VERSION ""

NS_ :

BS_:

BU_: WPC2 RLPSU DPSU APSU PSB SHVU_RR vHS_B2 FCS EMCU SLB ARS RCM CGW_CCU vDummy_HS_B ATS RLHV SGU PFSU ALBCU DSAU SWRC SHVU_FR RCS RRPSU BLTN_CAM SCM DLBCU OHCL RWPC RRHV WPC HOD ASAU

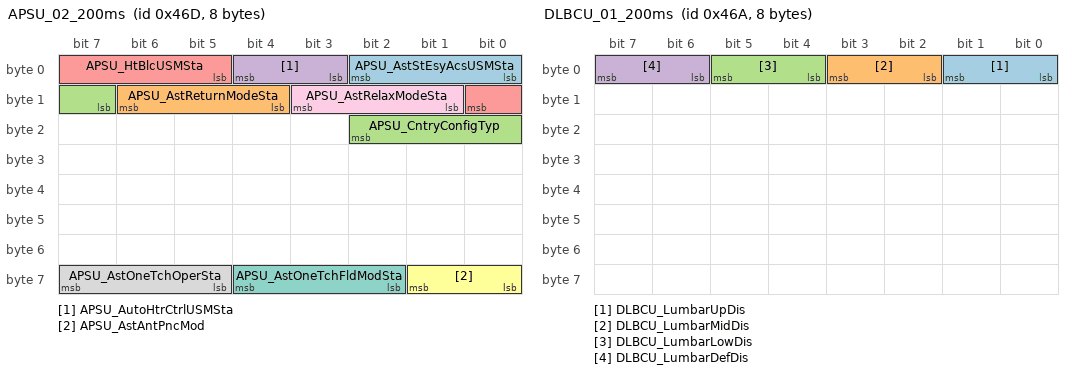
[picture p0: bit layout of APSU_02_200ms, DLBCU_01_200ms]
BO_ 1133 APSU_02_200ms: 8 APSU
 SG_ APSU_AstStEsyAcsUSMSta : 0|3@1+ (1,0) [0|0] ""  ALBCU,CGW_CCU
 SG_ APSU_AstReturnModeSta : 12|3@1+ (1,0) [0|0] ""  CGW_CCU
 SG_ APSU_CntryConfigTyp : 15|4@1+ (1,0) [0|0] ""  Vector__XXX
 SG_ APSU_AutoHtrCtrlUSMSta : 3|2@1+ (1,0) [0|0] ""  Vector__XXX
 SG_ APSU_HtBlcUSMSta : 5|4@1+ (1,0) [0|0] ""  Vector__XXX
 SG_ APSU_AstAntPncMod : 56|2@1+ (1,0) [0|0] ""  RLPSU,RRPSU
 SG_ APSU_AstOneTchFldModSta : 58|3@1+ (1,0) [0|0] ""  RLPSU,RRPSU
 SG_ APSU_AstOneTchOperSta : 61|3@1+ (1,0) [0|0] ""  RLPSU,RRPSU
 SG_ APSU_AstRelaxModeSta : 9|3@1+ (1,0) [0|0] ""  CGW_CCU

BO_ 1130 DLBCU_01_200ms: 8 DLBCU
 SG_ DLBCU_LumbarUpDis : 0|2@1+ (1,0) [0|0] ""  CGW_CCU
 SG_ DLBCU_LumbarMidDis : 2|2@1+ (1,0) [0|0] ""  CGW_CCU
 SG_ DLBCU_LumbarLowDis : 4|2@1+ (1,0) [0|0] ""  CGW_CCU
 SG_ DLBCU_LumbarDefDis : 6|2@1+ (1,0) [0|0] ""  CGW_CCU

BO_ 1131 DLBCU_02_200ms: 8 DLBCU
 SG_ DLBCU_BolsterInfDis : 0|2@1+ (1,0) [0|0] ""  CGW_CCU
 SG_ DLBCU_BolsterDefDis : 2|2@1+ (1,0) [0|0] ""  CGW_CCU

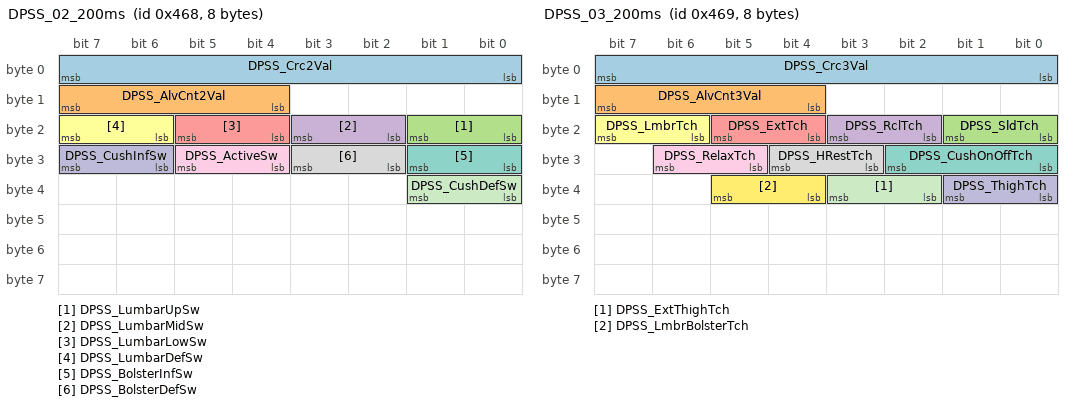
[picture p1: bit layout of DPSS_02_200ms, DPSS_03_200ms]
BO_ 1128 DPSS_02_200ms: 8 DPSU
 SG_ DPSS_Crc2Val : 0|8@1+ (1,0) [0|0] ""  DLBCU
 SG_ DPSS_AlvCnt2Val : 12|4@1+ (1,0) [0|0] ""  DLBCU
 SG_ DPSS_LumbarUpSw : 16|2@1+ (1,0) [0|0] ""  DLBCU
 SG_ DPSS_LumbarMidSw : 18|2@1+ (1,0) [0|0] ""  DLBCU
 SG_ DPSS_LumbarLowSw : 20|2@1+ (1,0) [0|0] ""  DLBCU
 SG_ DPSS_LumbarDefSw : 22|2@1+ (1,0) [0|0] ""  DLBCU
 SG_ DPSS_BolsterInfSw : 24|2@1+ (1,0) [0|0] ""  DLBCU
 SG_ DPSS_BolsterDefSw : 26|2@1+ (1,0) [0|0] ""  DLBCU
 SG_ DPSS_ActiveSw : 28|2@1+ (1,0) [0|0] ""  DLBCU
 SG_ DPSS_CushInfSw : 30|2@1+ (1,0) [0|0] ""  DLBCU
 SG_ DPSS_CushDefSw : 32|2@1+ (1,0) [0|0] ""  DLBCU

BO_ 1129 DPSS_03_200ms: 8 DPSU
 SG_ DPSS_Crc3Val : 0|8@1+ (1,0) [0|0] ""  CGW_CCU
 SG_ DPSS_AlvCnt3Val : 12|4@1+ (1,0) [0|0] ""  Vector__XXX
 SG_ DPSS_SldTch : 16|2@1+ (1,0) [0|0] ""  CGW_CCU
 SG_ DPSS_RclTch : 18|2@1+ (1,0) [0|0] ""  CGW_CCU
 SG_ DPSS_ExtTch : 20|2@1+ (1,0) [0|0] ""  CGW_CCU
 SG_ DPSS_LmbrTch : 22|2@1+ (1,0) [0|0] ""  CGW_CCU
 SG_ DPSS_CushOnOffTch : 24|3@1+ (1,0) [0|0] ""  CGW_CCU
 SG_ DPSS_HRestTch : 27|2@1+ (1,0) [0|0] ""  CGW_CCU
 SG_ DPSS_RelaxTch : 29|2@1+ (1,0) [0|0] ""  CGW_CCU
 SG_ DPSS_ThighTch : 32|2@1+ (1,0) [0|0] ""  CGW_CCU
 SG_ DPSS_ExtThighTch : 34|2@1+ (1,0) [0|0] ""  CGW_CCU
 SG_ DPSS_LmbrBolsterTch : 36|2@1+ (1,0) [0|0] ""  CGW_CCU

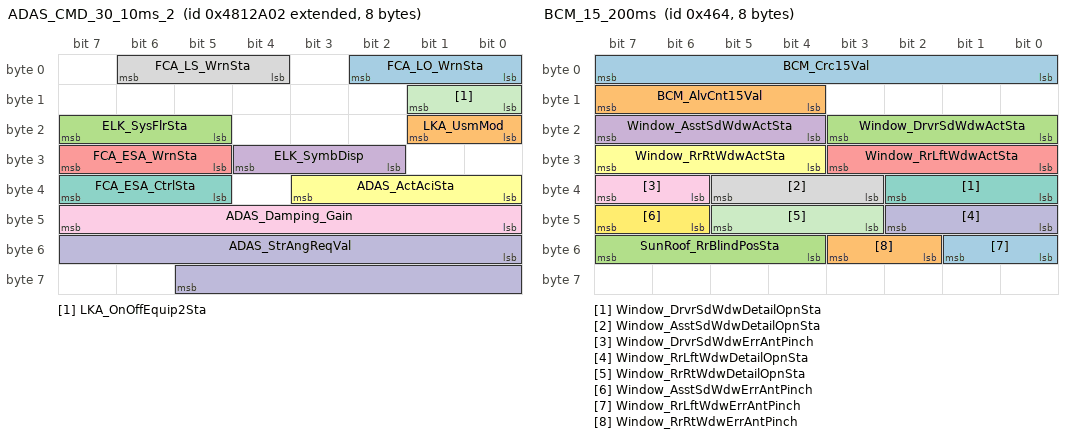
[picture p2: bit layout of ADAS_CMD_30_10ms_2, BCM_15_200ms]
BO_ 2223057410 ADAS_CMD_30_10ms_2: 8 CGW_CCU
 SG_ FCA_LO_WrnSta : 0|3@1+ (1,0) [0|0] ""  SWRC
 SG_ LKA_UsmMod : 16|2@1+ (1,0) [0|0] ""  Vector__XXX
 SG_ ELK_SysFlrSta : 21|3@1+ (1,0) [0|0] ""  Vector__XXX
 SG_ ELK_SymbDisp : 26|3@1+ (1,0) [0|0] ""  Vector__XXX
 SG_ FCA_ESA_WrnSta : 29|3@1+ (1,0) [0|0] ""  SWRC
 SG_ ADAS_ActAciSta : 32|4@1+ (1,0) [0|0] ""  Vector__XXX
 SG_ FCA_ESA_CtrlSta : 37|3@1+ (1,0) [0|0] ""  Vector__XXX
 SG_ FCA_LS_WrnSta : 4|3@1+ (1,0) [0|0] ""  SWRC
 SG_ ADAS_Damping_Gain : 40|8@1+ (1,0) [0|0] ""  Vector__XXX
 SG_ ADAS_StrAngReqVal : 48|14@1- (0.1,0) [0|0] "Deg"  Vector__XXX
 SG_ LKA_OnOffEquip2Sta : 8|2@1+ (1,0) [0|0] ""  Vector__XXX

BO_ 1127 DPSS_01_200ms: 8 DPSU
 SG_ DPSS_Crc1Val : 0|8@1+ (1,0) [0|0] ""  Vector__XXX
 SG_ DPSS_AlvCnt1Val : 12|4@1+ (1,0) [0|0] ""  Vector__XXX
 SG_ DPSS_StExtFwdMvBtn : 16|2@1+ (1,0) [0|0] ""  Vector__XXX
 SG_ DPSS_StExtBwdMvBtn : 18|2@1+ (1,0) [0|0] ""  Vector__XXX
 SG_ DPSS_StSldFwdMvBtn : 20|2@1+ (1,0) [0|0] ""  Vector__XXX
 SG_ DPSS_StSldBwdMvBtn : 24|2@1+ (1,0) [0|0] ""  Vector__XXX
 SG_ DPSS_StRclFwdMvBtn : 26|2@1+ (1,0) [0|0] ""  Vector__XXX
 SG_ DPSS_StRclBwdMvBtn : 28|2@1+ (1,0) [0|0] ""  Vector__XXX
 SG_ DPSS_StHgtUpMvBtn : 30|2@1+ (1,0) [0|0] ""  Vector__XXX
 SG_ DPSS_StHgtDnMvBtn : 32|2@1+ (1,0) [0|0] ""  Vector__XXX
 SG_ DPSS_StTltUpMvBtn : 34|2@1+ (1,0) [0|0] ""  Vector__XXX
 SG_ DPSS_StTltDnMvBtn : 36|2@1+ (1,0) [0|0] ""  Vector__XXX
 SG_ DPSS_StHRestUpMvBtn : 38|2@1+ (1,0) [0|0] ""  Vector__XXX
 SG_ DPSS_StHRestDnMvBtn : 40|2@1+ (1,0) [0|0] ""  Vector__XXX
 SG_ DPSS_StHRestFwdMvBtn : 42|2@1+ (1,0) [0|0] ""  Vector__XXX
 SG_ DPSS_StHRestBwdMvBtn : 44|2@1+ (1,0) [0|0] ""  Vector__XXX
 SG_ DPSS_StLegUpMvBtn : 46|2@1+ (1,0) [0|0] ""  Vector__XXX
 SG_ DPSS_StLegDnMvBtn : 48|2@1+ (1,0) [0|0] ""  Vector__XXX
 SG_ DPSS_StRlxModeBtn : 50|2@1+ (1,0) [0|0] ""  Vector__XXX
 SG_ DPSS_StRlxReturnBtn : 52|2@1+ (1,0) [0|0] ""  Vector__XXX
 SG_ DPSS_StRlxTltUpMvBtn : 54|2@1+ (1,0) [0|0] ""  Vector__XXX
 SG_ DPSS_StRlxTltDnMvBtn : 56|2@1+ (1,0) [0|0] ""  Vector__XXX

BO_ 1124 BCM_15_200ms: 8 CGW_CCU
 SG_ BCM_Crc15Val : 0|8@1+ (1,0) [0|0] ""  Vector__XXX
 SG_ BCM_AlvCnt15Val : 12|4@1+ (1,0) [0|0] ""  Vector__XXX
 SG_ Window_DrvrSdWdwActSta : 16|4@1+ (1,0) [0|0] ""  Vector__XXX
 SG_ Window_AsstSdWdwActSta : 20|4@1+ (1,0) [0|0] ""  Vector__XXX
 SG_ Window_RrLftWdwActSta : 24|4@1+ (1,0) [0|0] ""  Vector__XXX
 SG_ Window_RrRtWdwActSta : 28|4@1+ (1,0) [0|0] ""  Vector__XXX
 SG_ Window_DrvrSdWdwDetailOpnSta : 32|3@1+ (1,0) [0|0] ""  Vector__XXX
 SG_ Window_AsstSdWdwDetailOpnSta : 35|3@1+ (1,0) [0|0] ""  Vector__XXX
 SG_ Window_DrvrSdWdwErrAntPinch : 38|2@1+ (1,0) [0|0] ""  Vector__XXX
 SG_ Window_RrLftWdwDetailOpnSta : 40|3@1+ (1,0) [0|0] ""  Vector__XXX
 SG_ Window_RrRtWdwDetailOpnSta : 43|3@1+ (1,0) [0|0] ""  Vector__XXX
 SG_ Window_AsstSdWdwErrAntPinch : 46|2@1+ (1,0) [0|0] ""  Vector__XXX
 SG_ Window_RrLftWdwErrAntPinch : 48|2@1+ (1,0) [0|0] ""  Vector__XXX
 SG_ Window_RrRtWdwErrAntPinch : 50|2@1+ (1,0) [0|0] ""  Vector__XXX
 SG_ SunRoof_RrBlindPosSta : 52|4@1+ (1,0) [0|0] ""  ATS

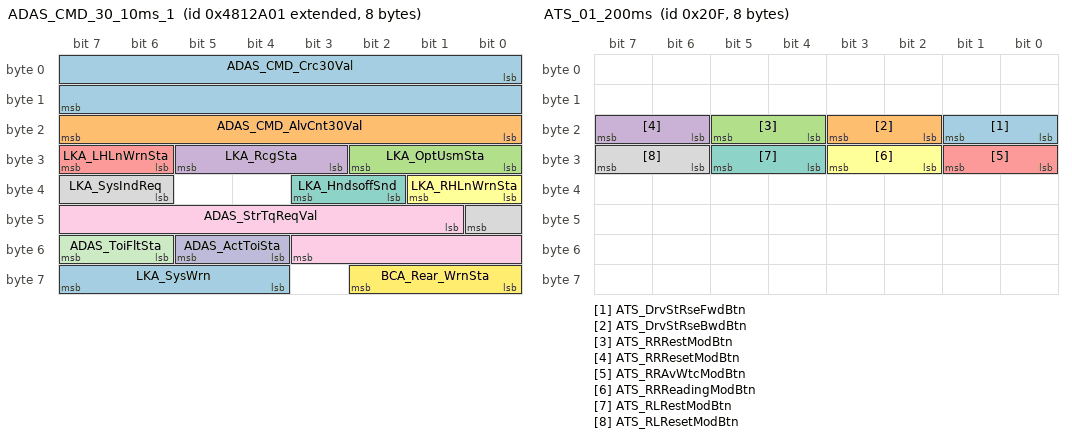
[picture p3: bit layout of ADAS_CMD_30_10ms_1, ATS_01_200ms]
BO_ 2223057409 ADAS_CMD_30_10ms_1: 8 CGW_CCU
 SG_ ADAS_CMD_Crc30Val : 0|16@1+ (1,0) [0|0] ""  Vector__XXX
 SG_ ADAS_CMD_AlvCnt30Val : 16|8@1+ (1,0) [0|0] ""  Vector__XXX
 SG_ LKA_OptUsmSta : 24|3@1+ (1,0) [0|0] ""  Vector__XXX
 SG_ LKA_RcgSta : 27|3@1+ (1,0) [0|0] ""  Vector__XXX
 SG_ LKA_LHLnWrnSta : 30|2@1+ (1,0) [0|0] ""  Vector__XXX
 SG_ LKA_RHLnWrnSta : 32|2@1+ (1,0) [0|0] ""  Vector__XXX
 SG_ LKA_HndsoffSnd : 34|2@1+ (1,0) [0|0] ""  Vector__XXX
 SG_ LKA_SysIndReq : 38|3@1+ (1,0) [0|0] ""  Vector__XXX
 SG_ ADAS_StrTqReqVal : 41|11@1+ (0.0078125,-8) [0|0] "Nm"  Vector__XXX
 SG_ ADAS_ActToiSta : 52|2@1+ (1,0) [0|0] ""  Vector__XXX
 SG_ ADAS_ToiFltSta : 54|2@1+ (1,0) [0|0] ""  Vector__XXX
 SG_ BCA_Rear_WrnSta : 56|3@1+ (1,0) [0|0] ""  Vector__XXX
 SG_ LKA_SysWrn : 60|4@1+ (1,0) [0|0] ""  Vector__XXX

BO_ 527 ATS_01_200ms: 8 ATS
 SG_ ATS_DrvStRseFwdBtn : 16|2@1+ (1,0) [0|0] ""  Vector__XXX
 SG_ ATS_DrvStRseBwdBtn : 18|2@1+ (1,0) [0|0] ""  Vector__XXX
 SG_ ATS_RRRestModBtn : 20|2@1+ (1,0) [0|0] ""  Vector__XXX
 SG_ ATS_RRResetModBtn : 22|2@1+ (1,0) [0|0] ""  Vector__XXX
 SG_ ATS_RRAvWtcModBtn : 24|2@1+ (1,0) [0|0] ""  Vector__XXX
 SG_ ATS_RRReadingModBtn : 26|2@1+ (1,0) [0|0] ""  Vector__XXX
 SG_ ATS_RLRestModBtn : 28|2@1+ (1,0) [0|0] ""  Vector__XXX
 SG_ ATS_RLResetModBtn : 30|2@1+ (1,0) [0|0] ""  Vector__XXX

BO_ 1616 MKBD_HU_E_01: 8 CGW_CCU
 SG_ MKBD_IllumiState : 48|2@1+ (1,0) [0|0] ""  Vector__XXX
 SG_ MKBD_SeatKeySet : 50|2@1+ (1,0) [0|0] ""  APSU,SHVU_FR,DPSU

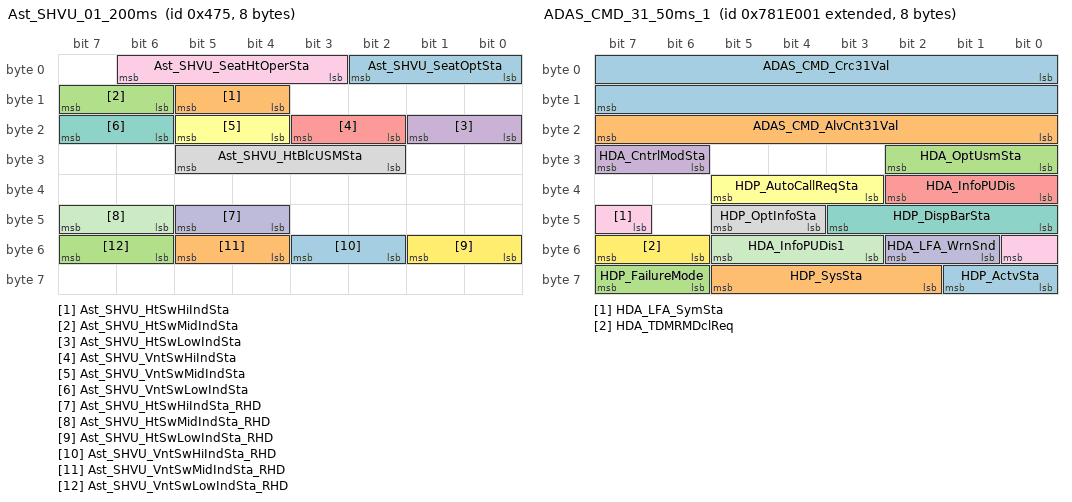
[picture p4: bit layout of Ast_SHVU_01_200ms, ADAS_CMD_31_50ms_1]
BO_ 1141 Ast_SHVU_01_200ms: 8 APSU
 SG_ Ast_SHVU_SeatOptSta : 0|3@1+ (1,0) [0|0] ""  FCS,CGW_CCU
 SG_ Ast_SHVU_HtSwHiIndSta : 12|2@1+ (1,0) [0|0] ""  FCS,CGW_CCU
 SG_ Ast_SHVU_HtSwMidIndSta : 14|2@1+ (1,0) [0|0] ""  FCS,CGW_CCU
 SG_ Ast_SHVU_HtSwLowIndSta : 16|2@1+ (1,0) [0|0] ""  FCS,CGW_CCU
 SG_ Ast_SHVU_VntSwHiIndSta : 18|2@1+ (1,0) [0|0] ""  FCS,CGW_CCU
 SG_ Ast_SHVU_VntSwMidIndSta : 20|2@1+ (1,0) [0|0] ""  FCS,CGW_CCU
 SG_ Ast_SHVU_VntSwLowIndSta : 22|2@1+ (1,0) [0|0] ""  FCS,CGW_CCU
 SG_ Ast_SHVU_HtBlcUSMSta : 26|4@1+ (1,0) [0|0] ""  CGW_CCU
 SG_ Ast_SHVU_SeatHtOperSta : 3|4@1+ (1,0) [0|0] ""  CGW_CCU
 SG_ Ast_SHVU_HtSwHiIndSta_RHD : 44|2@1+ (1,0) [0|0] ""  FCS,CGW_CCU
 SG_ Ast_SHVU_HtSwMidIndSta_RHD : 46|2@1+ (1,0) [0|0] ""  FCS,CGW_CCU
 SG_ Ast_SHVU_HtSwLowIndSta_RHD : 48|2@1+ (1,0) [0|0] ""  FCS,CGW_CCU
 SG_ Ast_SHVU_VntSwHiIndSta_RHD : 50|2@1+ (1,0) [0|0] ""  FCS,CGW_CCU
 SG_ Ast_SHVU_VntSwMidIndSta_RHD : 52|2@1+ (1,0) [0|0] ""  FCS,CGW_CCU
 SG_ Ast_SHVU_VntSwLowIndSta_RHD : 54|2@1+ (1,0) [0|0] ""  FCS,CGW_CCU

BO_ 543 ATS_02_200ms: 8 ATS
 SG_ ATS_AstStSldFwdBtn : 16|2@1+ (1,0) [0|0] ""  Vector__XXX
 SG_ ATS_AstStSldBwdBtn : 18|2@1+ (1,0) [0|0] ""  Vector__XXX
 SG_ ATS_AstStRclFwdBtn : 20|2@1+ (1,0) [0|0] ""  Vector__XXX
 SG_ ATS_AstStRclBwdBtn : 22|2@1+ (1,0) [0|0] ""  Vector__XXX
 SG_ ATS_AstStHgtUpBtn : 28|2@1+ (1,0) [0|0] ""  Vector__XXX
 SG_ ATS_AstStHgtDnBtn : 30|2@1+ (1,0) [0|0] ""  Vector__XXX
 SG_ ATS_AstStHRestUpBtn : 40|2@1+ (1,0) [0|0] ""  Vector__XXX
 SG_ ATS_AstStHRestDnBtn : 42|2@1+ (1,0) [0|0] ""  Vector__XXX
 SG_ ATS_AstStHRestFwdBtn : 44|2@1+ (1,0) [0|0] ""  Vector__XXX
 SG_ ATS_AstStHRestBwdBtn : 46|2@1+ (1,0) [0|0] ""  Vector__XXX
 SG_ ATS_AstStHRestFldBtn : 48|2@1+ (1,0) [0|0] ""  Vector__XXX
 SG_ ATS_AstStHRestUnFldBtn : 50|2@1+ (1,0) [0|0] ""  Vector__XXX
 SG_ ATS_AstStRseFwdBtn : 52|2@1+ (1,0) [0|0] ""  Vector__XXX
 SG_ ATS_AstStRseBwdBtn : 54|2@1+ (1,0) [0|0] ""  Vector__XXX
 SG_ ATS_AstStFRestFldBtn : 56|2@1+ (1,0) [0|0] ""  Vector__XXX
 SG_ ATS_AstStFRestUnFldBtn : 58|2@1+ (1,0) [0|0] ""  Vector__XXX
 SG_ ATS_AstTltUpBtn : 60|2@1+ (1,0) [0|0] ""  Vector__XXX
 SG_ ATS_AstTltDnBtn : 62|2@1+ (1,0) [0|0] ""  Vector__XXX

BO_ 2273435649 ADAS_CMD_31_50ms_1: 8 CGW_CCU
 SG_ ADAS_CMD_Crc31Val : 0|16@1+ (1,0) [0|0] ""  Vector__XXX
 SG_ ADAS_CMD_AlvCnt31Val : 16|8@1+ (1,0) [0|0] ""  Vector__XXX
 SG_ HDA_OptUsmSta : 24|3@1+ (1,0) [0|0] ""  Vector__XXX
 SG_ HDA_CntrlModSta : 30|2@1+ (1,0) [0|0] ""  Vector__XXX
 SG_ HDA_InfoPUDis : 32|3@1+ (1,0) [0|0] ""  Vector__XXX
 SG_ HDP_AutoCallReqSta : 35|3@1+ (1,0) [0|0] ""  Vector__XXX
 SG_ HDP_DispBarSta : 40|4@1+ (1,0) [0|0] ""  Vector__XXX
 SG_ HDP_OptInfoSta : 44|2@1+ (1,0) [0|0] ""  Vector__XXX
 SG_ HDA_LFA_SymSta : 47|2@1+ (1,0) [0|0] ""  Vector__XXX
 SG_ HDA_LFA_WrnSnd : 49|2@1+ (1,0) [0|0] ""  Vector__XXX
 SG_ HDA_InfoPUDis1 : 51|3@1+ (1,0) [0|0] ""  Vector__XXX
 SG_ HDA_TDMRMDclReq : 54|2@1+ (1,0) [0|0] ""  Vector__XXX
 SG_ HDP_ActvSta : 56|2@1+ (1,0) [0|0] ""  Vector__XXX
 SG_ HDP_SysSta : 58|4@1+ (1,0) [0|0] ""  HOD
 SG_ HDP_FailureMode : 62|2@1+ (1,0) [0|0] ""  Vector__XXX

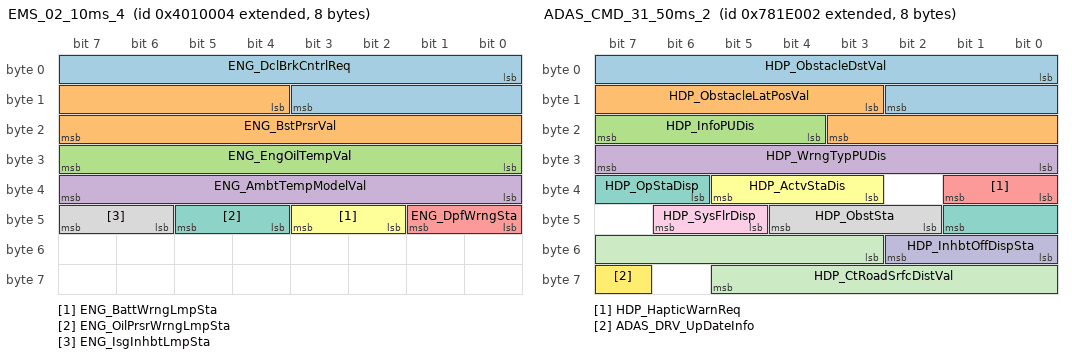
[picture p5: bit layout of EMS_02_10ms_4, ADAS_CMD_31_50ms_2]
BO_ 2214658052 EMS_02_10ms_4: 8 CGW_CCU
 SG_ ENG_DclBrkCntrlReq : 0|12@1+ (0.001,-4.094) [0|0] "m/s^2"  Vector__XXX
 SG_ ENG_BstPrsrVal : 12|12@1+ (1.322,0) [0|0] "hPa"  Vector__XXX
 SG_ ENG_EngOilTempVal : 24|8@1+ (0.75,-40) [0|0] "¡É"  Vector__XXX
 SG_ ENG_AmbtTempModelVal : 32|8@1+ (0.5,-41) [0|0] "¡É"  Vector__XXX
 SG_ ENG_DpfWrngSta : 40|2@1+ (1,0) [0|0] ""  Vector__XXX
 SG_ ENG_BattWrngLmpSta : 42|2@1+ (1,0) [0|0] ""  Vector__XXX
 SG_ ENG_OilPrsrWrngLmpSta : 44|2@1+ (1,0) [0|0] ""  Vector__XXX
 SG_ ENG_IsgInhbtLmpSta : 46|2@1+ (1,0) [0|0] ""  FCS

BO_ 2273435650 ADAS_CMD_31_50ms_2: 8 CGW_CCU
 SG_ HDP_ObstacleDstVal : 0|11@1+ (0.1,0) [0|0] "m"  Vector__XXX
 SG_ HDP_ObstacleLatPosVal : 11|9@1+ (0.1,-20) [0|0] "m"  Vector__XXX
 SG_ HDP_InfoPUDis : 20|4@1+ (1,0) [0|0] ""  Vector__XXX
 SG_ HDP_WrngTypPUDis : 24|8@1+ (1,0) [0|0] ""  Vector__XXX
 SG_ HDP_HapticWarnReq : 32|2@1+ (1,0) [0|0] ""  PSB
 SG_ HDP_ActvStaDis : 35|3@1+ (1,0) [0|0] ""  Vector__XXX
 SG_ HDP_OpStaDisp : 38|4@1+ (1,0) [0|0] ""  Vector__XXX
 SG_ HDP_ObstSta : 42|3@1+ (1,0) [0|0] ""  Vector__XXX
 SG_ HDP_SysFlrDisp : 45|2@1+ (1,0) [0|0] ""  Vector__XXX
 SG_ HDP_InhbtOffDispSta : 48|3@1+ (1,0) [0|0] ""  Vector__XXX
 SG_ HDP_CtRoadSrfcDistVal : 51|11@1+ (1,0) [0|0] ""  Vector__XXX
 SG_ ADAS_DRV_UpDateInfo : 63|1@1+ (1,0) [0|0] ""  Vector__XXX

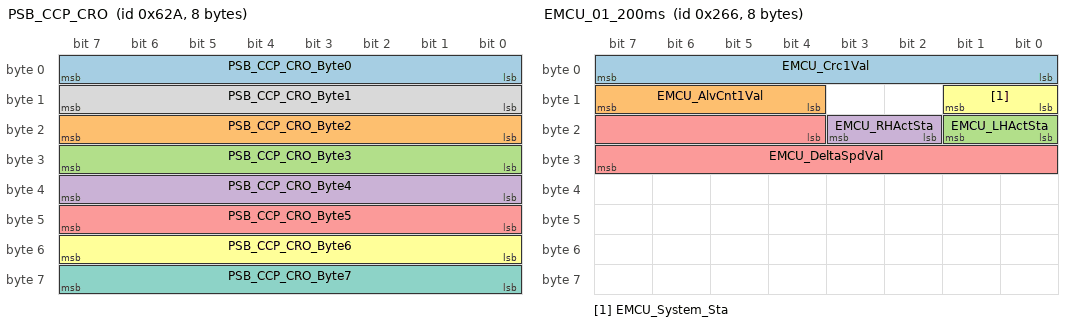
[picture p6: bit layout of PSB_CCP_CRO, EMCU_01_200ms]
BO_ 1578 PSB_CCP_CRO: 8 CGW_CCU
 SG_ PSB_CCP_CRO_Byte0 : 0|8@1+ (1,0) [0|0] ""  PSB
 SG_ PSB_CCP_CRO_Byte2 : 16|8@1+ (1,0) [0|0] ""  PSB
 SG_ PSB_CCP_CRO_Byte3 : 24|8@1+ (1,0) [0|0] ""  PSB
 SG_ PSB_CCP_CRO_Byte4 : 32|8@1+ (1,0) [0|0] ""  PSB
 SG_ PSB_CCP_CRO_Byte5 : 40|8@1+ (1,0) [0|0] ""  PSB
 SG_ PSB_CCP_CRO_Byte6 : 48|8@1+ (1,0) [0|0] ""  PSB
 SG_ PSB_CCP_CRO_Byte7 : 56|8@1+ (1,0) [0|0] ""  PSB
 SG_ PSB_CCP_CRO_Byte1 : 8|8@1+ (1,0) [0|0] ""  PSB

BO_ 614 EMCU_01_200ms: 8 EMCU
 SG_ EMCU_Crc1Val : 0|8@1+ (1,0) [0|0] ""  Vector__XXX
 SG_ EMCU_AlvCnt1Val : 12|4@1+ (1,0) [0|0] ""  Vector__XXX
 SG_ EMCU_LHActSta : 16|2@1+ (1,0) [0|0] ""  Vector__XXX
 SG_ EMCU_RHActSta : 18|2@1+ (1,0) [0|0] ""  Vector__XXX
 SG_ EMCU_DeltaSpdVal : 20|12@1+ (0.01,0) [0|0] ""  Vector__XXX
 SG_ EMCU_System_Sta : 8|2@1+ (1,0) [0|0] ""  Vector__XXX

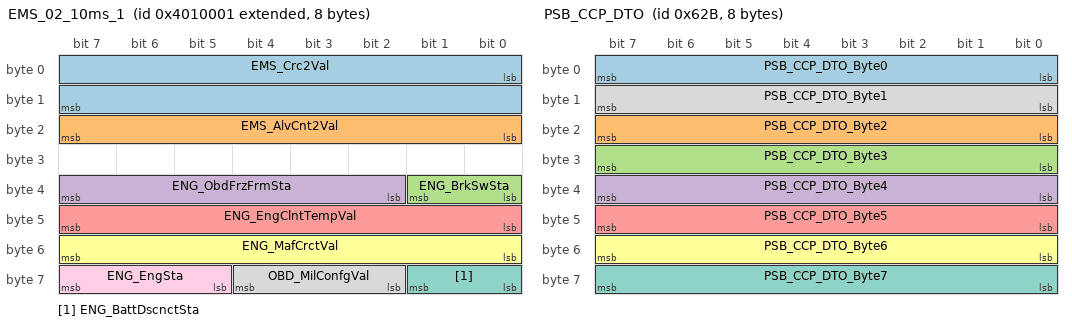
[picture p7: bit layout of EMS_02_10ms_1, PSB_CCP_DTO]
BO_ 2214658049 EMS_02_10ms_1: 8 CGW_CCU
 SG_ EMS_Crc2Val : 0|16@1+ (1,0) [0|0] ""  Vector__XXX
 SG_ EMS_AlvCnt2Val : 16|8@1+ (1,0) [0|0] ""  Vector__XXX
 SG_ ENG_BrkSwSta : 32|2@1+ (1,0) [0|0] ""  BLTN_CAM
 SG_ ENG_ObdFrzFrmSta : 34|6@1+ (1,0) [0|0] ""  Vector__XXX
 SG_ ENG_EngClntTempVal : 40|8@1+ (0.75,-48) [0|0] "¡É"  Vector__XXX
 SG_ ENG_MafCrctVal : 48|8@1+ (0.00781,0) [0|0] ""  Vector__XXX
 SG_ ENG_BattDscnctSta : 56|2@1+ (1,0) [0|0] ""  Vector__XXX
 SG_ OBD_MilConfgVal : 58|3@1+ (1,0) [0|0] ""  Vector__XXX
 SG_ ENG_EngSta : 61|3@1+ (1,0) [0|0] ""  SCM,WPC,RWPC,SWRC,APSU,RLHV,RRHV,SHVU_FR,SHVU_RR,DPSU,DLBCU,PFSU,RRPSU,RLPSU,HOD,RCM,BLTN_CAM,EMCU,WPC2

BO_ 1579 PSB_CCP_DTO: 8 PSB
 SG_ PSB_CCP_DTO_Byte0 : 0|8@1+ (1,0) [0|0] ""  CGW_CCU
 SG_ PSB_CCP_DTO_Byte2 : 16|8@1+ (1,0) [0|0] ""  CGW_CCU
 SG_ PSB_CCP_DTO_Byte3 : 24|8@1+ (1,0) [0|0] ""  CGW_CCU
 SG_ PSB_CCP_DTO_Byte4 : 32|8@1+ (1,0) [0|0] ""  CGW_CCU
 SG_ PSB_CCP_DTO_Byte5 : 40|8@1+ (1,0) [0|0] ""  CGW_CCU
 SG_ PSB_CCP_DTO_Byte6 : 48|8@1+ (1,0) [0|0] ""  CGW_CCU
 SG_ PSB_CCP_DTO_Byte7 : 56|8@1+ (1,0) [0|0] ""  CGW_CCU
 SG_ PSB_CCP_DTO_Byte1 : 8|8@1+ (1,0) [0|0] ""  CGW_CCU

BO_ 2244046850 ADAS_PRK_10_20ms_2: 8 CGW_CCU
 SG_ ADAS_PRK_PDW_SwIndOnReq : 0|2@1+ (1,0) [0|0] ""  FCS
 SG_ PCA_RrEquipChkSta : 10|2@1+ (1,0) [0|0] ""  Vector__XXX
 SG_ PCA_FrWrngLvlSta : 12|3@1+ (1,0) [0|0] ""  Vector__XXX
 SG_ PCA_LtWrngLvlSta : 16|3@1+ (1,0) [0|0] ""  Vector__XXX
 SG_ ADAS_PRK_PDW_OptTyp : 2|3@1+ (1,0) [0|0] ""  Vector__XXX
 SG_ PCA_RtWrngLvlSta : 20|3@1+ (1,0) [0|0] ""  Vector__XXX
 SG_ PCA_RrFlrDis : 32|2@1+ (1,0) [0|0] ""  Vector__XXX
 SG_ PCA_FrFlrDis : 34|2@1+ (1,0) [0|0] ""  Vector__XXX
 SG_ PCA_LtFlrDis : 36|2@1+ (1,0) [0|0] ""  Vector__XXX
 SG_ PCA_RtFlrDis : 38|2@1+ (1,0) [0|0] ""  Vector__XXX
 SG_ PCA_FrBndryLn : 40|2@1+ (1,0) [0|0] ""  Vector__XXX
 SG_ PCA_RrBndryLn : 42|2@1+ (1,0) [0|0] ""  Vector__XXX
 SG_ PCA_LtBndryLn : 44|2@1+ (1,0) [0|0] ""  Vector__XXX
 SG_ PCA_RtBndryLn : 46|2@1+ (1,0) [0|0] ""  Vector__XXX
 SG_ PCA_WrngPhrs : 48|3@1+ (1,0) [0|0] ""  Vector__XXX
 SG_ ADAS_PRK_PDW_AutoOn_USM : 5|2@1+ (1,0) [0|0] ""  Vector__XXX
 SG_ PCA_FrSdEquipChkSta : 8|2@1+ (1,0) [0|0] ""  Vector__XXX

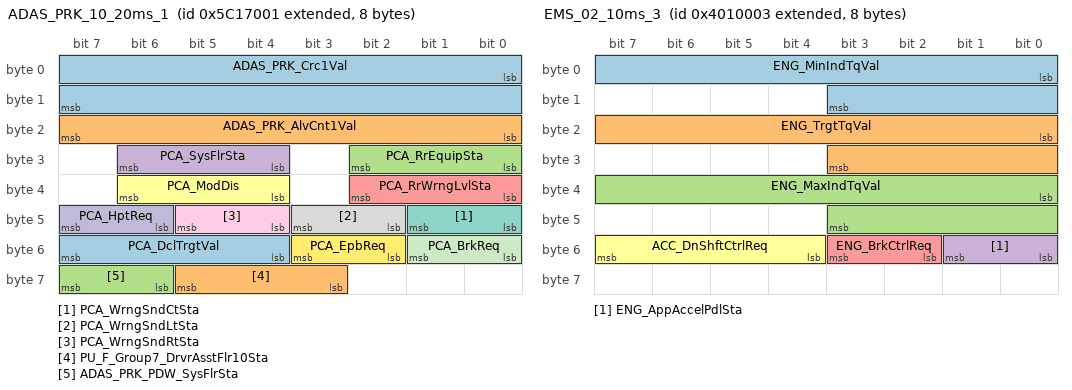
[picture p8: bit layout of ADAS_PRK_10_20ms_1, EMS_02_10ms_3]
BO_ 2244046849 ADAS_PRK_10_20ms_1: 8 CGW_CCU
 SG_ ADAS_PRK_Crc1Val : 0|16@1+ (1,0) [0|0] ""  Vector__XXX
 SG_ ADAS_PRK_AlvCnt1Val : 16|8@1+ (1,0) [0|0] ""  Vector__XXX
 SG_ PCA_RrEquipSta : 24|3@1+ (1,0) [0|0] ""  Vector__XXX
 SG_ PCA_SysFlrSta : 28|3@1+ (1,0) [0|0] ""  Vector__XXX
 SG_ PCA_RrWrngLvlSta : 32|3@1+ (1,0) [0|0] ""  Vector__XXX
 SG_ PCA_ModDis : 36|3@1+ (1,0) [0|0] ""  Vector__XXX
 SG_ PCA_WrngSndCtSta : 40|2@1+ (1,0) [0|0] ""  Vector__XXX
 SG_ PCA_WrngSndLtSta : 42|2@1+ (1,0) [0|0] ""  Vector__XXX
 SG_ PCA_WrngSndRtSta : 44|2@1+ (1,0) [0|0] ""  Vector__XXX
 SG_ PCA_HptReq : 46|2@1+ (1,0) [0|0] ""  Vector__XXX
 SG_ PCA_BrkReq : 48|2@1+ (1,0) [0|0] ""  Vector__XXX
 SG_ PCA_EpbReq : 50|2@1+ (1,0) [0|0] ""  Vector__XXX
 SG_ PCA_DclTrgtVal : 52|4@1+ (0.04,0) [0|0] "g"  Vector__XXX
 SG_ PU_F_Group7_DrvrAsstFlr10Sta : 59|3@1+ (1,0) [0|0] ""  Vector__XXX
 SG_ ADAS_PRK_PDW_SysFlrSta : 62|2@1+ (1,0) [0|0] ""  Vector__XXX

BO_ 2214658051 EMS_02_10ms_3: 8 CGW_CCU
 SG_ ENG_MinIndTqVal : 0|12@1- (1,0) [0|0] "Nm"  Vector__XXX
 SG_ ENG_TrgtTqVal : 16|12@1- (1,0) [0|0] "Nm"  Vector__XXX
 SG_ ENG_MaxIndTqVal : 32|12@1- (1,0) [0|0] "Nm"  Vector__XXX
 SG_ ENG_AppAccelPdlSta : 48|2@1+ (1,0) [0|0] ""  Vector__XXX
 SG_ ENG_BrkCtrlReq : 50|2@1+ (1,0) [0|0] ""  Vector__XXX
 SG_ ACC_DnShftCtrlReq : 52|4@1+ (1,0) [0|0] ""  Vector__XXX

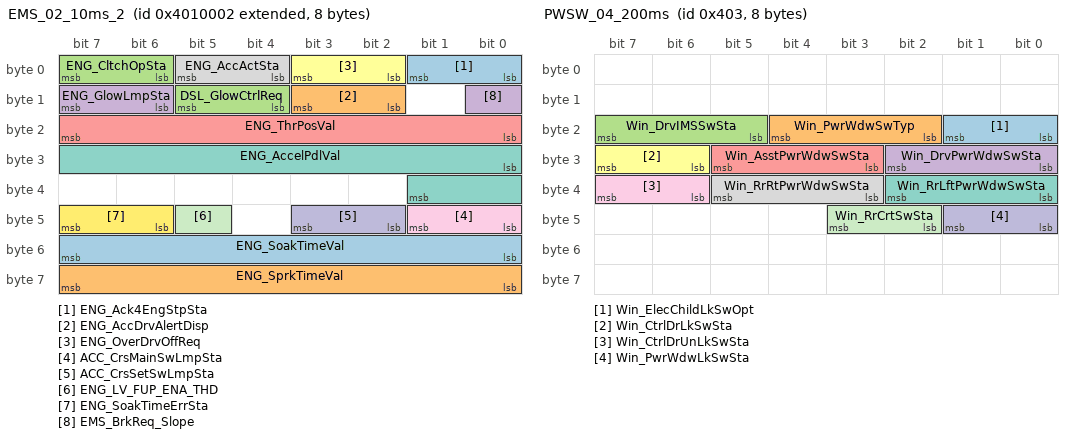
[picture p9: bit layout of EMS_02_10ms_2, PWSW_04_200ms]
BO_ 2214658050 EMS_02_10ms_2: 8 CGW_CCU
 SG_ ENG_Ack4EngStpSta : 0|2@1+ (1,0) [0|0] ""  Vector__XXX
 SG_ ENG_AccDrvAlertDisp : 10|2@1+ (1,0) [0|0] ""  Vector__XXX
 SG_ DSL_GlowCtrlReq : 12|2@1+ (1,0) [0|0] ""  Vector__XXX
 SG_ ENG_GlowLmpSta : 14|2@1+ (1,0) [0|0] ""  Vector__XXX
 SG_ ENG_ThrPosVal : 16|8@1+ (0.4694836,-15.0234742) [0|0] "%"  Vector__XXX
 SG_ ENG_OverDrvOffReq : 2|2@1+ (1,0) [0|0] ""  Vector__XXX
 SG_ ENG_AccelPdlVal : 24|10@1+ (0.09784,0) [0|0] "%"  BLTN_CAM,EMCU
 SG_ ENG_AccActSta : 4|2@1+ (1,0) [0|0] ""  Vector__XXX
 SG_ ACC_CrsMainSwLmpSta : 40|2@1+ (1,0) [0|0] ""  Vector__XXX
 SG_ ACC_CrsSetSwLmpSta : 42|2@1+ (1,0) [0|0] ""  Vector__XXX
 SG_ ENG_LV_FUP_ENA_THD : 45|1@1+ (1,0) [0|0] ""  Vector__XXX
 SG_ ENG_SoakTimeErrSta : 46|2@1+ (1,0) [0|0] ""  Vector__XXX
 SG_ ENG_SoakTimeVal : 48|8@1+ (1,0) [0|0] "Min"  Vector__XXX
 SG_ ENG_SprkTimeVal : 56|8@1+ (0.375,-35.625) [0|0] "¢ª"  Vector__XXX
 SG_ ENG_CltchOpSta : 6|2@1+ (1,0) [0|0] ""  Vector__XXX
 SG_ EMS_BrkReq_Slope : 8|1@1+ (1,0) [0|0] ""  Vector__XXX

BO_ 1027 PWSW_04_200ms: 8 CGW_CCU
 SG_ Win_ElecChildLkSwOpt : 16|2@1+ (1,0) [0|0] ""  Vector__XXX
 SG_ Win_PwrWdwSwTyp : 18|3@1+ (1,0) [0|0] ""  Vector__XXX
 SG_ Win_DrvIMSSwSta : 21|3@1+ (1,0) [0|0] ""  DPSU
 SG_ Win_DrvPwrWdwSwSta : 24|3@1+ (1,0) [0|0] ""  Vector__XXX
 SG_ Win_AsstPwrWdwSwSta : 27|3@1+ (1,0) [0|0] ""  Vector__XXX
 SG_ Win_CtrlDrLkSwSta : 30|2@1+ (1,0) [0|0] ""  Vector__XXX
 SG_ Win_RrLftPwrWdwSwSta : 32|3@1+ (1,0) [0|0] ""  Vector__XXX
 SG_ Win_RrRtPwrWdwSwSta : 35|3@1+ (1,0) [0|0] ""  Vector__XXX
 SG_ Win_CtrlDrUnLkSwSta : 38|2@1+ (1,0) [0|0] ""  Vector__XXX
 SG_ Win_PwrWdwLkSwSta : 40|2@1+ (1,0) [0|0] ""  Vector__XXX
 SG_ Win_RrCrtSwSta : 42|2@1+ (1,0) [0|0] ""  Vector__XXX

BO_TX_BU_ 1141 : APSU,SHVU_FR;
CM_ BO_ 2223057409 "[P] Periodic";
CM_ SG_ 2223057409 ADAS_CMD_Crc30Val "ADAS_CMD_CyclicRedundancyCheck30Value";
CM_ SG_ 2223057409 ADAS_CMD_AlvCnt30Val "ADAS_CMD_AliveCounter30Value";
CM_ SG_ 2223057409 LKA_OptUsmSta "LKA_OptionUsmStatus ##2G##LDW_LKA - LKA11 - CF_LKA_Opt_USM";
CM_ SG_ 2223057409 LKA_RcgSta "LKA_RecognitionStatus ##2G##LDW_LKA - LKA11 - CF_LKA_LaneRecogState";
CM_ SG_ 2223057409 LKA_LHLnWrnSta "LKA_LHLaneWarningStatus ##2G##LDW_LKA - LKA11 - CF_LKA_LHWarning";
CM_ SG_ 2223057409 LKA_RHLnWrnSta "LKA_RHLaneWarningStatus ##2G##LDW_LKA - LKA11 - CF_LKA_RHWarning";
CM_ SG_ 2223057409 LKA_HndsoffSnd "LKA_HandsoffSound ##2G##LDW_LKA - LKA11 - CF_LKA_HandsOff_Snd";
CM_ SG_ 2223057409 LKA_SysIndReq "LKA_SystemIndicatorRequest ##2G##LDW_LKA - LKA11 - CF_LKA_SymbolState";
CM_ SG_ 2223057409 ADAS_StrTqReqVal "LKA_SteeringTorqueRequestValue ##2G##LDW_LKA - LKA11 - CR_LKA_StrToqReq";
CM_ SG_ 2223057409 ADAS_ActToiSta "ADAS_ActiveTorqueOverlayInterfaceStatus ##2G##LDW_LKA - LKA11 - CF_LKA_ActToi";
CM_ SG_ 2223057409 ADAS_ToiFltSta "ADAS_TorqueOverlayInterfaceFaultStatus ##2G##LDW_LKA - LKA11 - CF_LKA_ToiFlt";
CM_ SG_ 2223057409 BCA_Rear_WrnSta "BCA_Rear_WarningStatus";
CM_ SG_ 2223057409 LKA_SysWrn "LKA_Additional_Info";
CM_ BO_ 2223057410 "[P] Periodic";
CM_ SG_ 2223057410 FCA_LO_WrnSta "FCA_LO_WarningStatus";
CM_ SG_ 2223057410 LKA_UsmMod "LKA_USM Mode ##2G##LDW_LKA-LKA11-CF_LKA_USM_Mode";
CM_ SG_ 2223057410 ELK_SysFlrSta "ELK System Failure State";
CM_ SG_ 2223057410 ELK_SymbDisp "ELK Symbol Display";
CM_ SG_ 2223057410 FCA_ESA_WrnSta "FCA w/ ESA HMI";
CM_ SG_ 2223057410 ADAS_ActAciSta "ADAS_ActiveAngleControlInterfaceStatus";
CM_ SG_ 2223057410 FCA_ESA_CtrlSta "FCA w/ ESA Control Status";
CM_ SG_ 2223057410 FCA_LS_WrnSta "FCA_LS_WarningStatus";
CM_ SG_ 2223057410 ADAS_Damping_Gain "ADAS_Damping_Gain";
CM_ SG_ 2223057410 ADAS_StrAngReqVal "ADAS_SteeringAngleRequestValue";
CM_ SG_ 2223057410 LKA_OnOffEquip2Sta "LKA On Off Equipment 2 State";
CM_ BO_ 2273435649 "[P] Periodic";
CM_ SG_ 2273435649 ADAS_CMD_Crc31Val "ADAS_CMD_CyclicRedundancyCheck31Value";
CM_ SG_ 2273435649 ADAS_CMD_AlvCnt31Val "ADAS_CMD_AliveCounter31Value";
CM_ SG_ 2273435649 HDA_OptUsmSta "HDA_OptionUSMStatus ##2G##LDW_LKA - HDA11 - CF_HDA_Opt_USM";
CM_ SG_ 2273435649 HDA_CntrlModSta "HDA_ControlModeStatus ##2G##LDW_LKA - HDA11 - CF_HDA_Mode";
CM_ SG_ 2273435649 HDA_InfoPUDis "HDA_InformationPopUpDisplay ##2G##LDW_LKA - HDA11 - CF_HDA_InfoDisplay";
CM_ SG_ 2273435649 HDP_AutoCallReqSta "HDP Auto Call Request State";
CM_ SG_ 2273435649 HDP_DispBarSta "HDP Display Bar State";
CM_ SG_ 2273435649 HDP_OptInfoSta "HDP Option Infomation State";
CM_ SG_ 2273435649 HDA_LFA_SymSta "HDA_LFA_SymbolStatus ##2G##LDW_LKA - HDA11 - CF_HDA_LFA_SymbolState";
CM_ SG_ 2273435649 HDA_LFA_WrnSnd "HDA/LFA Additional Warning Sound";
CM_ SG_ 2273435649 HDA_InfoPUDis1 "HDA_InfomationPopupDisplay";
CM_ SG_ 2273435649 HDP_ActvSta "HDP_ControlActiveStatus";
CM_ SG_ 2273435649 HDP_SysSta "HDP_SystemStatus";
CM_ BO_ 2273435650 "[P] Periodic";
CM_ SG_ 2273435650 HDP_ObstacleDstVal "HDP_InPathObstacleDistance";
CM_ SG_ 2273435650 HDP_ObstacleLatPosVal "HDP_InPathObstaclePositionValue";
CM_ SG_ 2273435650 HDP_InfoPUDis "HDP_InformationPopupDisplay (main pop-up)";
CM_ SG_ 2273435650 HDP_WrngTypPUDis "HDP_WarningTypePopupDisplay (mini pop-up)";
CM_ SG_ 2273435650 HDP_HapticWarnReq "Request for HDP haptic warning";
CM_ SG_ 2273435650 HDP_ActvStaDis "HDP_Active/Deactive Status Display";
CM_ SG_ 2273435650 HDP_OpStaDisp "HDP Operation State Display";
CM_ SG_ 2273435650 HDP_ObstSta "HDP Obstacle State";
CM_ SG_ 2273435650 HDP_SysFlrDisp "HDP System Failure Display";
CM_ SG_ 2273435650 HDP_InhbtOffDispSta "HDP Inhibit Off Display State";
CM_ SG_ 2273435650 HDP_CtRoadSrfcDistVal "HDP Center Road Surface Distance Value";
CM_ SG_ 2273435650 ADAS_DRV_UpDateInfo "ADAS_DRV update state info";
CM_ BO_ 2244046849 "[P] Periodic";
CM_ SG_ 2244046849 ADAS_PRK_Crc1Val "ADAS_PRK_CyclicRedundancyCheck1Value";
CM_ SG_ 2244046849 ADAS_PRK_AlvCnt1Val "ADAs_PRK_AliveCounter1Value";
CM_ SG_ 2244046849 PCA_RrEquipSta "PCA_RearEquipmentStatus";
CM_ SG_ 2244046849 PCA_SysFlrSta "PCA_SystemFailureStatus";
CM_ SG_ 2244046849 PCA_RrWrngLvlSta "PCA_RearWarningLevelStatus";
CM_ SG_ 2244046849 PCA_ModDis "PCA_ ModeDisplay";
CM_ SG_ 2244046849 PCA_WrngSndCtSta "PCA_WarningSoundCenterStatus";
CM_ SG_ 2244046849 PCA_WrngSndLtSta "PCA_WarningSoundLeftStatus";
CM_ SG_ 2244046849 PCA_WrngSndRtSta "PCA_WarningSoundRightStatus";
CM_ SG_ 2244046849 PCA_HptReq "PCA_HapticRequest";
CM_ SG_ 2244046849 PCA_BrkReq "PCA_BrakeRequest";
CM_ SG_ 2244046849 PCA_EpbReq "PCA_EPBRequest";
CM_ SG_ 2244046849 PCA_DclTrgtVal "PCA_DecelerationTargetValue";
CM_ SG_ 2244046849 PU_F_Group7_DrvrAsstFlr10Sta "PDW or PCA Blockage / Failure Status";
CM_ SG_ 2244046849 ADAS_PRK_PDW_SysFlrSta "PDW System Failure State";
CM_ BO_ 2244046850 "[P] Periodic";
CM_ SG_ 2244046850 PCA_RrEquipChkSta "PCA RearEquipmentCheckStatus";
CM_ SG_ 2244046850 PCA_FrWrngLvlSta "PCA_FrontWarningLevelStatus";
CM_ SG_ 2244046850 PCA_LtWrngLvlSta "PCA_LeftWarningLevelStatus";
CM_ SG_ 2244046850 ADAS_PRK_PDW_OptTyp "Option information for None, PDW-R, PDW-FR, PDW-FSR";
CM_ SG_ 2244046850 PCA_RtWrngLvlSta "PCA_RightWarningLevelStatus";
CM_ SG_ 2244046850 PCA_RrFlrDis "PCA_RearFailureDisplay";
CM_ SG_ 2244046850 PCA_FrFlrDis "PCA_FrontFailureDisplay";
CM_ SG_ 2244046850 PCA_LtFlrDis "PCA_LeftFailureDisplay";
CM_ SG_ 2244046850 PCA_RtFlrDis "PCA_RightFailureDisplay";
CM_ SG_ 2244046850 PCA_FrBndryLn "PCA - Front Boundary Line Display Status";
CM_ SG_ 2244046850 PCA_RrBndryLn "PCA - Rear Boundary Line Display Status";
CM_ SG_ 2244046850 PCA_LtBndryLn "PCA - Left Boundary Line Display Status";
CM_ SG_ 2244046850 PCA_RtBndryLn "PCA - Right Boundary Line Display Status";
CM_ SG_ 2244046850 PCA_WrngPhrs "PCA - Warning Phrase Display Status";
CM_ SG_ 2244046850 PCA_FrSdEquipChkSta "PCA_FrontSideEquipmentCheckStatus";
CM_ BO_ 1133 "[PE] Periodic and On Event";
CM_ SG_ 1133 APSU_AstStEsyAcsUSMSta "USM_MovingValue";
CM_ SG_ 1133 APSU_CntryConfigTyp "APSU_ContryConfigurationType";
CM_ SG_ 1133 APSU_AutoHtrCtrlUSMSta "Auto Down Seat Heater (USM Setting)";
CM_ SG_ 1133 APSU_HtBlcUSMSta "Hetaer Balance Assistant USM R vaule";
CM_ BO_ 527 "[PE] Periodic and On Event";
CM_ SG_ 527 ATS_DrvStRseFwdBtn "Drive Seat  RSE Forward Touch Button";
CM_ SG_ 527 ATS_DrvStRseBwdBtn "Drive Seat  RSE Backward Touch Button";
CM_ SG_ 527 ATS_RRRestModBtn "Rear Right Rest Mode Touch Button";
CM_ SG_ 527 ATS_RRResetModBtn "Rear Right Return Mode Touch Button";
CM_ SG_ 527 ATS_RRAvWtcModBtn "Rear Right AV Watching Mode Touch Button";
CM_ SG_ 527 ATS_RRReadingModBtn "Rear Right Reading Mode Touch Button";
CM_ SG_ 527 ATS_RLRestModBtn "Rear Left Rest Mode Touch Button";
CM_ SG_ 527 ATS_RLResetModBtn "Rear Left Return Mode Touch Button";
CM_ BO_ 543 "[PE] Periodic and On Event";
CM_ SG_ 543 ATS_AstStSldFwdBtn "Assist Power Seat Slide Forward Rear Walk In Button";
CM_ SG_ 543 ATS_AstStSldBwdBtn "Assist Power Seat Slide Backward Rear Walk In Button";
CM_ SG_ 543 ATS_AstStRclFwdBtn "Assist Power Seat Recline Forward Rear Walk In Button";
CM_ SG_ 543 ATS_AstStRclBwdBtn "Assist Power Seat Recline Backward Rear Walk In Button";
CM_ SG_ 543 ATS_AstStHgtUpBtn "Assist Power Seat Height Up Walk In Button";
CM_ SG_ 543 ATS_AstStHgtDnBtn "Assist Power Seat Height Dn Walk In Button";
CM_ SG_ 543 ATS_AstStHRestUpBtn "Assist Power Seat Head Rest Up Walk In Button";
CM_ SG_ 543 ATS_AstStHRestDnBtn "Assist Power Seat  Head Rest Dn Walk In Button";
CM_ SG_ 543 ATS_AstStHRestFwdBtn "Assist Power Seat Head Rest Forward  Walk In Button";
CM_ SG_ 543 ATS_AstStHRestBwdBtn "Assist Power Seat Head Rest Backward  Walk In Button";
CM_ SG_ 543 ATS_AstStHRestFldBtn "Assist Power Seat Head Rest Folding  Walk In Button";
CM_ SG_ 543 ATS_AstStHRestUnFldBtn "Assist Power Seat Head Rest Unfolding  Walk In Button";
CM_ SG_ 543 ATS_AstStRseFwdBtn "Assist Power Seat RSE Forward  Walk In Button";
CM_ SG_ 543 ATS_AstStRseBwdBtn "Assist Power Seat RSE Backward Walk In Button";
CM_ SG_ 543 ATS_AstStFRestFldBtn "Assist Power Seat Foot Rest Folding Walk In Button";
CM_ SG_ 543 ATS_AstStFRestUnFldBtn "Assist Power Seat Foot Rest Unfolding Walk In Button";
CM_ SG_ 543 ATS_AstTltUpBtn "Assist Power Seat  Tilt Up Walk In Button";
CM_ SG_ 543 ATS_AstTltDnBtn "Assist Power Seat Tilt Down  Walk In Button";
CM_ BO_ 1141 "[PE] Periodic and On Event";
CM_ SG_ 1141 Ast_SHVU_SeatOptSta "Ast Seat Heater/Vent option info";
CM_ SG_ 1141 Ast_SHVU_HtSwHiIndSta "Ast Seat Heater Switch High Indicator Status";
CM_ SG_ 1141 Ast_SHVU_HtSwMidIndSta "Ast Seat Heater Switch Mid Indicator Status";
CM_ SG_ 1141 Ast_SHVU_HtSwLowIndSta "Ast Seat Heater Switch Low Indicator Status";
CM_ SG_ 1141 Ast_SHVU_VntSwHiIndSta "Ast Seat Vent Switch High Indicator Status";
CM_ SG_ 1141 Ast_SHVU_VntSwMidIndSta "Ast Seat Vent Switch Mid Indicator Status";
CM_ SG_ 1141 Ast_SHVU_VntSwLowIndSta "Ast Seat Vent Switch Low Indicator Status";
CM_ SG_ 1141 Ast_SHVU_HtBlcUSMSta "Hetaer Balance Assistant USM R vaule";
CM_ SG_ 1141 Ast_SHVU_SeatHtOperSta "Ast Seat Heater/Vent current operation state";
CM_ SG_ 1141 Ast_SHVU_HtSwHiIndSta_RHD "Ast Seat Heater Switch High Indicator Status(RHD)";
CM_ SG_ 1141 Ast_SHVU_HtSwMidIndSta_RHD "Ast Seat Heater Switch Mid Indicator Status(RHD)";
CM_ SG_ 1141 Ast_SHVU_HtSwLowIndSta_RHD "Ast Seat Heater Switch Low Indicator Status(RHD)";
CM_ SG_ 1141 Ast_SHVU_VntSwHiIndSta_RHD "Ast Seat Vent Switch High Indicator Status(RHD)";
CM_ SG_ 1141 Ast_SHVU_VntSwMidIndSta_RHD "Ast Seat Vent Switch Mid Indicator Status(RHD)";
CM_ SG_ 1141 Ast_SHVU_VntSwLowIndSta_RHD "Ast Seat Vent Switch Low Indicator Status(RHD)";
CM_ BO_ 1124 "[PE] Periodic and On Event";
CM_ SG_ 1124 BCM_Crc15Val "BCM_CyclicRedundancyCheck15Value";
CM_ SG_ 1124 BCM_AlvCnt15Val "BCM_AliveCounter15Value";
CM_ SG_ 1124 Window_DrvrSdWdwActSta "Window_DriverSideWindowActionStatus ##2G##BCM - BCMmsg25 - C_DrvWindowActState";
CM_ SG_ 1124 Window_AsstSdWdwActSta "Window_AssistantSideWindowActionStatus ##2G##BCM - BCMmsg25 - C_AstWindowActState";
CM_ SG_ 1124 Window_RrLftWdwActSta "Window_RearLeftWindowActionStatus ##2G##BCM - BCMmsg25 - C_RLWindowActState";
CM_ SG_ 1124 Window_RrRtWdwActSta "Window_RearRightWindowActionStatus ##2G##BCM - BCMmsg25 - C_RRWindowActState";
CM_ SG_ 1124 Window_DrvrSdWdwDetailOpnSta "Window_DriverSideWindowDetailOpenStatus ##2G##BCM - BCMmsg26 - C_DrvWdwDetailOpenState";
CM_ SG_ 1124 Window_AsstSdWdwDetailOpnSta "Window_AssistantSideWindowDetailOpenStatus ##2G##BCM - BCMmsg26 - C_AstWdwDetailOpenState";
CM_ SG_ 1124 Window_DrvrSdWdwErrAntPinch "Window_DriverSideWindowErrorAntiPinch ##2G##BCM - BCMmsg26 - C_DrvWdwErrAntiPinch";
CM_ SG_ 1124 Window_RrLftWdwDetailOpnSta "Window_RearLeftWindowDetailOpenStatus ##2G##BCM - BCMmsg26 - C_RLWdwDetailOpenState";
CM_ SG_ 1124 Window_RrRtWdwDetailOpnSta "Window_RearRightWindowDetailOpenStatus ##2G##BCM - BCMmsg26 - C_RRWdwDetailOpenState";
CM_ SG_ 1124 Window_AsstSdWdwErrAntPinch "Window_AssistantSideWindowErrorAntiPinch ##2G##BCM - BCMmsg26 - C_AstWdwErrAntiPinch";
CM_ SG_ 1124 Window_RrLftWdwErrAntPinch "Window_RearLeftWindowErrorAntiPinch ##2G##BCM - BCMmsg26 - C_RLWdwErrAntiPinch";
CM_ SG_ 1124 Window_RrRtWdwErrAntPinch "Window_RearRightWindowErrorAntiPinch ##2G##BCM - BCMmsg26 - C_RRWdwErrAntiPinch";
CM_ SG_ 1124 SunRoof_RrBlindPosSta "SunRoof_RearBlindPositionStatus";
CM_ BO_ 1130 "[PE] Periodic and On Event";
CM_ SG_ 1130 DLBCU_LumbarUpDis "DLBCU_LumbarUppperDisplay";
CM_ SG_ 1130 DLBCU_LumbarMidDis "DLBCU_LumbarMidDisplay";
CM_ SG_ 1130 DLBCU_LumbarLowDis "DLBCU_LumbarLowerDisplay";
CM_ SG_ 1130 DLBCU_LumbarDefDis "DLBCU_LumbarDeflationDisplay";
CM_ BO_ 1131 "[PE] Periodic and On Event";
CM_ SG_ 1131 DLBCU_BolsterInfDis "DLBCU_BolsterInflationDisplay";
CM_ SG_ 1131 DLBCU_BolsterDefDis "DLBCU_BolsterDeflationDisplay";
CM_ BO_ 1127 "[PE] Periodic and On Event";
CM_ SG_ 1127 DPSS_Crc1Val "DPSS_CyclicRedundancyCheck1Value";
CM_ SG_ 1127 DPSS_AlvCnt1Val "DPSS_AliveCounter1Value";
CM_ SG_ 1127 DPSS_StExtFwdMvBtn "DPSS_ExtensionForwardMoveButton";
CM_ SG_ 1127 DPSS_StExtBwdMvBtn "DPSS_ExtensionBackwardMoveButton";
CM_ SG_ 1127 DPSS_StSldFwdMvBtn "DPSS_SlideForwardMoveButton";
CM_ SG_ 1127 DPSS_StSldBwdMvBtn "DPSS_SlideBackwardMoveButton";
CM_ SG_ 1127 DPSS_StRclFwdMvBtn "DPSS_ReclinerForwardMoveButton";
CM_ SG_ 1127 DPSS_StRclBwdMvBtn "DPSS_ReclinerBackwardMoveButton";
CM_ SG_ 1127 DPSS_StHgtUpMvBtn "DPSS_HeightUpMoveButton";
CM_ SG_ 1127 DPSS_StHgtDnMvBtn "DPSS_HeightDownMoveButton";
CM_ SG_ 1127 DPSS_StTltUpMvBtn "DPSS_TiltUpMoveButton";
CM_ SG_ 1127 DPSS_StTltDnMvBtn "DPSS_TiltDownMoveButton";
CM_ SG_ 1127 DPSS_StHRestUpMvBtn "DPSS_StHRestUpMvBtn";
CM_ SG_ 1127 DPSS_StHRestDnMvBtn "DPSS_StHRestDnMvBtn";
CM_ SG_ 1127 DPSS_StHRestFwdMvBtn "DPSS_StHRestFwdMvBtn";
CM_ SG_ 1127 DPSS_StHRestBwdMvBtn "DPSS_StHRestBwdMvBtn";
CM_ SG_ 1127 DPSS_StLegUpMvBtn "DPSS_LegUpMoveButton";
CM_ SG_ 1127 DPSS_StLegDnMvBtn "DPSS_LegDownMoveButton";
CM_ SG_ 1127 DPSS_StRlxModeBtn "DPSS_RelaxModeButton";
CM_ SG_ 1127 DPSS_StRlxReturnBtn "DPSS_RelaxReturnButton";
CM_ SG_ 1127 DPSS_StRlxTltUpMvBtn "DPSS_RelaxTiltUpMoveButton";
CM_ SG_ 1127 DPSS_StRlxTltDnMvBtn "DPSS_RelaxTiltDownMoveButton";
CM_ BO_ 1128 "[PE] Periodic and On Event";
CM_ SG_ 1128 DPSS_Crc2Val "DPSS_CyclicRedundancyCheck2Value";
CM_ SG_ 1128 DPSS_AlvCnt2Val "DPSS_AliveCounter2Value";
CM_ SG_ 1128 DPSS_LumbarUpSw "DPSS_LumbarUpMoveSwitch";
CM_ SG_ 1128 DPSS_LumbarMidSw "DPSS_LumbarMiddleSwitch";
CM_ SG_ 1128 DPSS_LumbarLowSw "DPSS_LumbarLowerSwitch";
CM_ SG_ 1128 DPSS_LumbarDefSw "DPSS_LumbarDeflationSwitch";
CM_ SG_ 1128 DPSS_BolsterInfSw "DPSS_BolsterInflationSwitch";
CM_ SG_ 1128 DPSS_BolsterDefSw "DPSS_BolsterDeflationSwitch";
CM_ SG_ 1128 DPSS_ActiveSw "DPSS_ActiveSwitch";
CM_ SG_ 1128 DPSS_CushInfSw "DPSS_Cush Support Inflation Switch";
CM_ SG_ 1128 DPSS_CushDefSw "DPSS_Cush Support Deflation Switch";
CM_ BO_ 1129 "[PE] Periodic and On Event";
CM_ SG_ 1129 DPSS_Crc3Val "DPSS_CyclicRedundancyCheck3Value";
CM_ SG_ 1129 DPSS_AlvCnt3Val "DPSS_AliveCounter3Value";
CM_ SG_ 1129 DPSS_SldTch "DPSS_SlideTouch";
CM_ SG_ 1129 DPSS_RclTch "DPSS_ReclinerTouch";
CM_ SG_ 1129 DPSS_ExtTch "DPSS_ExtensionTouch";
CM_ SG_ 1129 DPSS_LmbrTch "DPSS_LumbarTouch";
CM_ SG_ 1129 DPSS_CushOnOffTch "DPSS_CushOnOffTouch";
CM_ SG_ 1129 DPSS_HRestTch "DPSS_HeadResetTouch";
CM_ SG_ 1129 DPSS_RelaxTch "DPSS_RelaxTouch";
CM_ SG_ 1129 DPSS_ThighTch "DPSS_ThighTouch";
CM_ SG_ 1129 DPSS_ExtThighTch "DPSS_ExtensionThighTouch";
CM_ SG_ 1129 DPSS_LmbrBolsterTch "DPSS_LumbarBolsterTouch";
CM_ BO_ 614 "[PE] Periodic and On Event";
CM_ SG_ 614 EMCU_Crc1Val "EMCU_CyclicRedundancyCheck1Value";
CM_ SG_ 614 EMCU_AlvCnt1Val "EMCU_AliveCounter1Value";
CM_ SG_ 614 EMCU_LHActSta "EMCU_LeftActuatorStatus";
CM_ SG_ 614 EMCU_RHActSta "EMCU_RightActuatorStatus";
CM_ SG_ 614 EMCU_DeltaSpdVal "EMCU_DeltaSpeedValue";
CM_ SG_ 614 EMCU_System_Sta "EMCU_SystemStatus";
CM_ BO_ 2214658049 "[P] Periodic";
CM_ SG_ 2214658049 EMS_Crc2Val "EMS_CyclicRedundancyCheck2Value";
CM_ SG_ 2214658049 EMS_AlvCnt2Val "EMS_AliveCounter2Value";
CM_ SG_ 2214658049 ENG_BrkSwSta "ENG_BrakeSwitchStatus ##2G##EMS - EMS12 - BRAKE_ACT";
CM_ SG_ 2214658049 ENG_ObdFrzFrmSta "ENG_ObdFreezeFrameStatus ##2G##EMS - EMS12 - OBD_FRF_ACK";
CM_ SG_ 2214658049 ENG_EngClntTempVal "ENG_EngineCoolantTemperatureValue ##2G##EMS - EMS12 - TEMP_ENG";
CM_ SG_ 2214658049 ENG_MafCrctVal "ENG_MassAirFlowCorrectionValue ##2G##EMS - EMS12 - MAF_FAC_ALTI_MMV";
CM_ SG_ 2214658049 ENG_BattDscnctSta "ENG_BatteryDisconnectStatus ##2G##EMS - EMS12 - VB_OFF_ACT";
CM_ SG_ 2214658049 OBD_MilConfgVal "OBD_MalfunctionIndicationLampConfigurationValue ##2G##EMS - EMS12 - CONF_MIL_FMY";
CM_ SG_ 2214658049 ENG_EngSta "ENG_EngineStatus ##2G##EMS - EMS16 - ENG_STAT";
CM_ BO_ 2214658050 "[P] Periodic";
CM_ SG_ 2214658050 ENG_Ack4EngStpSta "ENG_AcknowledgeForEngineStopStatus ##2G##EMS - EMS12 - ACK_ES";
CM_ SG_ 2214658050 ENG_AccDrvAlertDisp "The status of No Auto cruise Engaged or Auto cruise Disengaged.";
CM_ SG_ 2214658050 DSL_GlowCtrlReq "DSL_GlowControlRequest ##2G##EMS - EMS12 - GP_CTL";
CM_ SG_ 2214658050 ENG_GlowLmpSta "ENG_GlowLampStatus ##2G##EMS - EMS16 - GLOW_STAT";
CM_ SG_ 2214658050 ENG_ThrPosVal "ENG_ThrottlePositionValue ##2G##EMS - EMS12 - TPS";
CM_ SG_ 2214658050 ENG_OverDrvOffReq "ENG_OverDriveOffRequest ##2G##EMS - EMS12 - OD_OFF_REQ";
CM_ SG_ 2214658050 ENG_AccelPdlVal "ENG_AcceleratorPedalValue ##2G##EMS - EMS12 - PV_AV_CAN";
CM_ SG_ 2214658050 ENG_AccActSta "ENG_AutoCruiseControlActiveStatus ##2G##EMS - EMS12 - ACC_ACT";
CM_ SG_ 2214658050 ACC_CrsMainSwLmpSta "ACC_CruiseMainSwLampStatus ##2G##EMS - EMS16 - CRUISE_LAMP_M";
CM_ SG_ 2214658050 ACC_CrsSetSwLmpSta "ACC_CruiseSetSwLampStatus ##2G##EMS - EMS16 - CRUISE_LAMP_S";
CM_ SG_ 2214658050 ENG_LV_FUP_ENA_THD "Fuel prsssure state ##2G##EMS - LPI11 - LV_FUP_ENA_THD";
CM_ SG_ 2214658050 ENG_SoakTimeErrSta "ENG_SoakTimeErrorStatus ##2G##EMS - EMS16 - SOAK_TIME_ERROR";
CM_ SG_ 2214658050 ENG_SoakTimeVal "ENG_SoakTimeValue ##2G##EMS - EMS16 - SOAK_TIME";
CM_ SG_ 2214658050 ENG_SprkTimeVal "ENG_SparkTimeValue ##2G##EMS - EMS16 - SPK_TIME_CUR";
CM_ SG_ 2214658050 ENG_CltchOpSta "ENG_ClutchStatus ##2G##EMS - EMS12 - CLU_ACK";
CM_ SG_ 2214658050 EMS_BrkReq_Slope "Brake request at slope for anti-stall";
CM_ BO_ 2214658051 "[P] Periodic";
CM_ SG_ 2214658051 ENG_MinIndTqVal "ENG_MinimumIndicatedTorqueValue ##2G##EMS - EMS16 - TQI_MIN";
CM_ SG_ 2214658051 ENG_TrgtTqVal "ENG_TargetTorqueValue ##2G##EMS - EMS16 - TQI_TARGET";
CM_ SG_ 2214658051 ENG_MaxIndTqVal "ENG_MaximumIndicatedTorqueValue ##2G##EMS - EMS16 - TQI_MAX";
CM_ SG_ 2214658051 ENG_AppAccelPdlSta "ENG_AppliedAcceleratorPedalStatus ##2G##EMS - EMS16 - CF_Ems_AclAct";
CM_ SG_ 2214658051 ENG_BrkCtrlReq "ENG_BrakeControlRequest ##2G##EMS - EMS19 - CF_Ems_BrkReq";
CM_ SG_ 2214658051 ACC_DnShftCtrlReq "ACC_DownShiftControlRequest ##2G##EMS - EMS19 - CF_Ems_DnShftReq";
CM_ BO_ 2214658052 "[P] Periodic";
CM_ SG_ 2214658052 ENG_DclBrkCntrlReq "ENG_DecelerationBrakeControlRequest ##2G##EMS - EMS19 - CF_Ems_DecelReq";
CM_ SG_ 2214658052 ENG_BstPrsrVal "ENG_BoostPressureValue ##2G##EMS - EMS19 - CR_Ems_BstPre";
CM_ SG_ 2214658052 ENG_EngOilTempVal "ENG_EngineOilTemperatureValue ##2G##EMS - EMS19 - CR_Ems_EngOilTemp";
CM_ SG_ 2214658052 ENG_AmbtTempModelVal "ENG_AmbientTemperatureModelValue ##2G##EMS - EMS19 - CF_Ems_ModeledAmbTemp";
CM_ SG_ 2214658052 ENG_DpfWrngSta "ENG_DpfWarningStatus ##2G##EMS - EMS19 - DPF_LAMP_STAT";
CM_ SG_ 2214658052 ENG_BattWrngLmpSta "ENG_BatteryWarningLampStatus ##2G##EMS - EMS19 - BAT_LAMP_STAT";
CM_ SG_ 2214658052 ENG_OilPrsrWrngLmpSta "ENG_OilPressureWarningLampStatus ##2G##EMS - EMS19 - CF_Ems_OPSFail";
CM_ SG_ 2214658052 ENG_IsgInhbtLmpSta "ENG_IsgInhibitLampStatus ##2G##EMS - EMS19 - ISG_INHIBIT_LAMP_STAT";
CM_ BO_ 1616 "[EC] On Event and On Change";
CM_ SG_ 1616 MKBD_IllumiState "Signal to confirm completion transmission of illumination information between MKBD and HU";
CM_ SG_ 1616 MKBD_SeatKeySet "The signal for transmitting Seat Key inputs from MKBD to Seat ECU";
CM_ BO_ 1578 "[EW] On Event and On Write";
CM_ SG_ 1578 PSB_CCP_CRO_Byte0 "EOL Message for PSB";
CM_ SG_ 1578 PSB_CCP_CRO_Byte2 "EOL Message for PSB";
CM_ SG_ 1578 PSB_CCP_CRO_Byte3 "EOL Message for PSB";
CM_ SG_ 1578 PSB_CCP_CRO_Byte4 "EOL Message for PSB";
CM_ SG_ 1578 PSB_CCP_CRO_Byte5 "EOL Message for PSB";
CM_ SG_ 1578 PSB_CCP_CRO_Byte6 "EOL Message for PSB";
CM_ SG_ 1578 PSB_CCP_CRO_Byte7 "EOL Message for PSB";
CM_ SG_ 1578 PSB_CCP_CRO_Byte1 "EOL Message for PSB";
CM_ BO_ 1579 "[EW] On Event and On Write";
CM_ SG_ 1579 PSB_CCP_DTO_Byte0 "EOL Message for PSB";
CM_ SG_ 1579 PSB_CCP_DTO_Byte2 "EOL Message for PSB";
CM_ SG_ 1579 PSB_CCP_DTO_Byte3 "EOL Message for PSB";
CM_ SG_ 1579 PSB_CCP_DTO_Byte4 "EOL Message for PSB";
CM_ SG_ 1579 PSB_CCP_DTO_Byte5 "EOL Message for PSB";
CM_ SG_ 1579 PSB_CCP_DTO_Byte6 "EOL Message for PSB";
CM_ SG_ 1579 PSB_CCP_DTO_Byte7 "EOL Message for PSB";
CM_ SG_ 1579 PSB_CCP_DTO_Byte1 "EOL Message for PSB";
CM_ BO_ 1027 "[PE] Periodic and On Event";
CM_ SG_ 1027 Win_ElecChildLkSwOpt "Window_ElectricChildLockSwitchOption";
CM_ SG_ 1027 Win_PwrWdwSwTyp "Window_PowerWindowSwitchType";
CM_ SG_ 1027 Win_DrvIMSSwSta "Window_DriverIMSSwitchStatus";
CM_ SG_ 1027 Win_DrvPwrWdwSwSta "Window_DriverPowerWindowSwitchStatus";
CM_ SG_ 1027 Win_AsstPwrWdwSwSta "Window_AssistantPowerWindowSwitchStatus";
CM_ SG_ 1027 Win_CtrlDrLkSwSta "Window_CentralDoorLockSwitchStatus";
CM_ SG_ 1027 Win_RrLftPwrWdwSwSta "Window_RearLeftPowerWindowSwitchStatus";
CM_ SG_ 1027 Win_RrRtPwrWdwSwSta "Window_RearRightPowerWindowSwitchStatus";
CM_ SG_ 1027 Win_CtrlDrUnLkSwSta "Window_CentralDoorUnlockSwitchStatus";
CM_ SG_ 1027 Win_PwrWdwLkSwSta "Window_PowerWindowLockSwitchStatus";
CM_ SG_ 1027 Win_RrCrtSwSta "Window_RearCurtainSwitchStatus";
BA_DEF_ BO_ "DiagState" ENUM "No","Yes" ;
BA_DEF_ BO_ "DiagResponse" ENUM "No","Yes" ;
BA_DEF_ BO_ "DiagRequest" ENUM "No","Yes" ;
BA_DEF_ BO_ "TpMessage" ENUM "No","Yes" ;
BA_DEF_ BO_ "UsrMsgIDSforwardDeviation" INT 0 100 ;
BA_DEF_ BO_ "UsrMsgIDSbackwardDeviation" INT 50 1000 ;
BA_DEF_ BO_ "GenMsgCycleTime" INT 0 2000 ;
BA_DEF_ BO_ "GenMsgStartDelayTime" INT 0 2000 ;
BA_DEF_ BO_ "GenMsgSendType" ENUM "Cyclic","NoMsgSendType" ;
BA_DEF_ BO_ "GenMsgCycleTimeFast" INT 0 500 ;
BA_DEF_ BO_ "GenMsgDelayTime" INT 0 20 ;
BA_DEF_ BO_ "GenMsgILSupport" ENUM "No","Yes" ;
BA_DEF_ BO_ "GenMsgNrOfRepetition" INT 0 3 ;
BA_DEF_ BO_ "NmMessage" ENUM "No","Yes" ;
BA_DEF_ BO_ "NWM-Botschaft" ENUM "No","Yes" ;
BA_DEF_ BO_ "TpTxIndex" INT 0 255 ;
BA_DEF_ BO_ "VFrameFormat" ENUM "StandardCAN","ExtendedCAN","reserved","reserved","reserved","reserved","reserved","reserved","reserved","reserved","reserved","reserved","reserved","reserved","StandardCAN_FD","ExtendedCAN_FD" ;
BA_DEF_ SG_ "UserSigValidity" ENUM "B+","ACC","IG","IG1","IG2","IG3","IG1 or IG2","IG1 or IG3","Undef" ;
BA_DEF_ SG_ "TimeoutValue" STRING ;
BA_DEF_ SG_ "UsrSigPurpose" ENUM "Undef","FN","DIAG","DIAG(Req)","DIAG(Res)","DIAG(Phy)","DEV","CCP(Req)","CCP(Res)","NM","TP" ;
BA_DEF_ SG_ "GenSigStartValue" INT 0 1215752192 ;
BA_DEF_ SG_ "NetworkRequest" ENUM "Yes","No" ;
BA_DEF_ SG_ "NetworkRequestHoldingTime" INT 0 65535 ;
BA_DEF_ SG_ "Description" STRING ;
BA_DEF_ SG_ "Version" STRING ;
BA_DEF_ SG_ "GenSigEnvVarType" ENUM "Int","Float","Undef" ;
BA_DEF_ SG_ "GenSigSendType" ENUM "Cyclic","OnWrite","OnWriteWithRepetition","OnChange","OnChangeWithRepetition","IfActive","IfActiveWithRepetition","NoSigSendType","OnChangeAndIfActive","OnChangeAndIfActiveWithRepetition" ;
BA_DEF_ SG_ "GwSigLatencyTime" INT 0 65536 ;
BA_DEF_ SG_ "GwSigMissingSourceType" ENUM "Undef","OldValue","DefaultValue","InitialValue" ;
BA_DEF_ SG_ "NWM-WakeupAllowed" ENUM "<n.a.>" ;
BA_DEF_ SG_ "RoutingFactor" INT 1 1215752192 ;
BA_DEF_REL_ BU_SG_REL_ "GenSigTimeoutTime" INT 0 7000 ;
BA_DEF_DEF_ "DiagState" "No" ;
BA_DEF_DEF_ "DiagResponse" "No" ;
BA_DEF_DEF_ "DiagRequest" "No" ;
BA_DEF_DEF_ "TpMessage" "No" ;
BA_DEF_DEF_ "UsrMsgIDSforwardDeviation" 10 ;
BA_DEF_DEF_ "UsrMsgIDSbackwardDeviation" 100 ;
BA_DEF_DEF_ "GenMsgCycleTime" 200 ;
BA_DEF_DEF_ "GenMsgStartDelayTime" 0 ;
BA_DEF_DEF_ "GenMsgSendType" "NoMsgSendType" ;
BA_DEF_DEF_ "GenMsgCycleTimeFast" 40 ;
BA_DEF_DEF_ "GenMsgDelayTime" 20 ;
BA_DEF_DEF_ "GenMsgILSupport" "Yes" ;
BA_DEF_DEF_ "GenMsgNrOfRepetition" 3 ;
BA_DEF_DEF_ "NmMessage" "No" ;
BA_DEF_DEF_ "NWM-Botschaft" "No" ;
BA_DEF_DEF_ "TpTxIndex" 0 ;
BA_DEF_DEF_ "VFrameFormat" "StandardCAN" ;
BA_DEF_DEF_ "UserSigValidity" "IG" ;
BA_DEF_DEF_ "TimeoutValue" "" ;
BA_DEF_DEF_ "UsrSigPurpose" "FN" ;
BA_DEF_DEF_ "GenSigStartValue" 0 ;
BA_DEF_DEF_ "NetworkRequest" "No" ;
BA_DEF_DEF_ "NetworkRequestHoldingTime" 0 ;
BA_DEF_DEF_ "Description" "" ;
BA_DEF_DEF_ "Version" "" ;
BA_DEF_DEF_ "GenSigEnvVarType" "Undef" ;
BA_DEF_DEF_ "GenSigSendType" "NoSigSendType" ;
BA_DEF_DEF_ "GwSigLatencyTime" 40 ;
BA_DEF_DEF_ "GwSigMissingSourceType" "Undef" ;
BA_DEF_DEF_ "NWM-WakeupAllowed" "<n.a.>" ;
BA_DEF_DEF_ "RoutingFactor" 1 ;
BA_DEF_DEF_REL_ "GenSigTimeoutTime" 500 ;
BA_ "GenMsgSendType" BO_ 2223057409 0;
BA_ "GenMsgCycleTime" BO_ 2223057409 50;
BA_ "GenMsgCycleTimeFast" BO_ 2223057409 0;
BA_ "GenMsgNrOfRepetition" BO_ 2223057409 0;
BA_ "VFrameFormat" BO_ 2223057409 1;
BA_ "Description" SG_ 2223057409 ADAS_CMD_Crc30Val "The data area for CRC calculation is based on the data length (DLC) of the message DB.

The CRC shall be calculated over the entire data block (excluding the CRC bytes) including the user data, alive counter and Data ID

 

- CRC Polynomial (0x1021) , Initial Value : 0xFFFF, XOR value : 0x0000, Data ID : Message ID + 0xF800 

- The initial value is for CRC calculation and the message should be sent with the calculated result value. 

- The mathematical expression to 16 bit CRC polynomial is given here. G(x) = x16 + x12 + x5 + 1";
BA_ "GenSigStartValue" SG_ 2223057409 ADAS_CMD_Crc30Val 65535;
BA_ "UserSigValidity" SG_ 2223057409 ADAS_CMD_Crc30Val 3;
BA_ "RoutingFactor" SG_ 2223057409 ADAS_CMD_Crc30Val 5;
BA_ "Version" SG_ 2223057409 ADAS_CMD_Crc30Val "18.11.08";
BA_ "Description" SG_ 2223057409 ADAS_CMD_AlvCnt30Val "For the first transmission request for a data element the counter shall be initialized with 0 and shall be incremented by 1 for every subsequent send request. 

When the counter reaches the maximum value(0xFF), then it shall restart with 0 for the next send request";
BA_ "UserSigValidity" SG_ 2223057409 ADAS_CMD_AlvCnt30Val 3;
BA_ "RoutingFactor" SG_ 2223057409 ADAS_CMD_AlvCnt30Val 5;
BA_ "Version" SG_ 2223057409 ADAS_CMD_AlvCnt30Val "18.11.08";
BA_ "UserSigValidity" SG_ 2223057409 LKA_OptUsmSta 3;
BA_ "RoutingFactor" SG_ 2223057409 LKA_OptUsmSta 5;
BA_ "Version" SG_ 2223057409 LKA_OptUsmSta "17.12.02";
BA_ "UserSigValidity" SG_ 2223057409 LKA_RcgSta 3;
BA_ "RoutingFactor" SG_ 2223057409 LKA_RcgSta 5;
BA_ "Version" SG_ 2223057409 LKA_RcgSta "18.10.12";
BA_ "UserSigValidity" SG_ 2223057409 LKA_LHLnWrnSta 3;
BA_ "RoutingFactor" SG_ 2223057409 LKA_LHLnWrnSta 5;
BA_ "Version" SG_ 2223057409 LKA_LHLnWrnSta "19.02.05";
BA_ "UserSigValidity" SG_ 2223057409 LKA_RHLnWrnSta 3;
BA_ "RoutingFactor" SG_ 2223057409 LKA_RHLnWrnSta 5;
BA_ "Version" SG_ 2223057409 LKA_RHLnWrnSta "19.02.05";
BA_ "UserSigValidity" SG_ 2223057409 LKA_HndsoffSnd 3;
BA_ "RoutingFactor" SG_ 2223057409 LKA_HndsoffSnd 5;
BA_ "Version" SG_ 2223057409 LKA_HndsoffSnd "17.12.02";
BA_ "UserSigValidity" SG_ 2223057409 LKA_SysIndReq 3;
BA_ "RoutingFactor" SG_ 2223057409 LKA_SysIndReq 5;
BA_ "Version" SG_ 2223057409 LKA_SysIndReq "20.12.00";
BA_ "Description" SG_ 2223057409 ADAS_StrTqReqVal "This is the driver torque overlay demand value. A negative value represents a torque that would accelerate the steering wheel in a clockwise direction. This signal is always zero whilst the TOI is inactive.";
BA_ "GenSigStartValue" SG_ 2223057409 ADAS_StrTqReqVal 1024;
BA_ "UserSigValidity" SG_ 2223057409 ADAS_StrTqReqVal 3;
BA_ "RoutingFactor" SG_ 2223057409 ADAS_StrTqReqVal 5;
BA_ "Version" SG_ 2223057409 ADAS_StrTqReqVal "18.10.00";
BA_ "Description" SG_ 2223057409 ADAS_ActToiSta "This is a flag that is set to 1 when requesting the steering to activate the torque overlay interface (TOI).  This must be done before an attempt is made to request non-zero steering torque overlay.";
BA_ "UserSigValidity" SG_ 2223057409 ADAS_ActToiSta 3;
BA_ "RoutingFactor" SG_ 2223057409 ADAS_ActToiSta 5;
BA_ "Version" SG_ 2223057409 ADAS_ActToiSta "18.12.07";
BA_ "Description" SG_ 2223057409 ADAS_ToiFltSta "This fault flag is set when a fault in the LKA system has been detected by the LKA ECU such that LKA can no longer function. CAN failures, internal video ECU failures, hard-wired component (e.g. master switch) failures and other system logic failures are all reported by this flag. Failures reported by the MDPS are not looped back through this flag.";
BA_ "UserSigValidity" SG_ 2223057409 ADAS_ToiFltSta 3;
BA_ "RoutingFactor" SG_ 2223057409 ADAS_ToiFltSta 5;
BA_ "Version" SG_ 2223057409 ADAS_ToiFltSta "18.12.07";
BA_ "Description" SG_ 2223057409 BCA_Rear_WrnSta "This signal indicates BCA-Rear warning for display and sound.";
BA_ "UserSigValidity" SG_ 2223057409 BCA_Rear_WrnSta 3;
BA_ "RoutingFactor" SG_ 2223057409 BCA_Rear_WrnSta 5;
BA_ "Version" SG_ 2223057409 BCA_Rear_WrnSta "18.10.09";
BA_ "Description" SG_ 2223057409 LKA_SysWrn "A signal that provides additional information on the operation of the LKA system for the HMI to display to the driver. This includes additional fault information, reasons for unavailability of the system and additional warnings like the hands-off warning. Some of the information may be displayed for short periods, whilst others like the hands-off warning may be displayed for longer periods.";
BA_ "UserSigValidity" SG_ 2223057409 LKA_SysWrn 3;
BA_ "RoutingFactor" SG_ 2223057409 LKA_SysWrn 5;
BA_ "Version" SG_ 2223057409 LKA_SysWrn "20.12.00";
BA_ "GenMsgSendType" BO_ 2223057410 0;
BA_ "GenMsgCycleTime" BO_ 2223057410 50;
BA_ "GenMsgCycleTimeFast" BO_ 2223057410 0;
BA_ "GenMsgNrOfRepetition" BO_ 2223057410 0;
BA_ "VFrameFormat" BO_ 2223057410 1;
BA_ "Description" SG_ 2223057410 FCA_LO_WrnSta "This signal indicates FCA-LO warning for display and sound.";
BA_ "UserSigValidity" SG_ 2223057410 FCA_LO_WrnSta 3;
BA_ "RoutingFactor" SG_ 2223057410 FCA_LO_WrnSta 5;
BA_ "Version" SG_ 2223057410 FCA_LO_WrnSta "17.11.00";
BA_ "Description" SG_ 2223057410 LKA_UsmMod "This signal indicates LKA USM Mode";
BA_ "UserSigValidity" SG_ 2223057410 LKA_UsmMod 3;
BA_ "RoutingFactor" SG_ 2223057410 LKA_UsmMod 5;
BA_ "Version" SG_ 2223057410 LKA_UsmMod "19.05.00";
BA_ "Description" SG_ 2223057410 ELK_SysFlrSta "ELK ÀÛµ¿ Á¦ÇÑ, °íÀå ÆË¾÷ ½ÅÈ£";
BA_ "UserSigValidity" SG_ 2223057410 ELK_SysFlrSta 3;
BA_ "RoutingFactor" SG_ 2223057410 ELK_SysFlrSta 5;
BA_ "Version" SG_ 2223057410 ELK_SysFlrSta "20.09.00";
BA_ "Description" SG_ 2223057410 ELK_SymbDisp "This signal describes warning symbol about ELK system (FCA-LO/LS, w/ ESA).";
BA_ "UserSigValidity" SG_ 2223057410 ELK_SymbDisp 3;
BA_ "RoutingFactor" SG_ 2223057410 ELK_SymbDisp 5;
BA_ "Version" SG_ 2223057410 ELK_SymbDisp "20.12.04";
BA_ "Description" SG_ 2223057410 FCA_ESA_WrnSta "FCA w/ ESA HMI";
BA_ "UserSigValidity" SG_ 2223057410 FCA_ESA_WrnSta 3;
BA_ "RoutingFactor" SG_ 2223057410 FCA_ESA_WrnSta 5;
BA_ "Version" SG_ 2223057410 FCA_ESA_WrnSta "18.08.06";
BA_ "Description" SG_ 2223057410 ADAS_ActAciSta "State for angle control";
BA_ "UserSigValidity" SG_ 2223057410 ADAS_ActAciSta 3;
BA_ "RoutingFactor" SG_ 2223057410 ADAS_ActAciSta 5;
BA_ "Version" SG_ 2223057410 ADAS_ActAciSta "19.11.03";
BA_ "Description" SG_ 2223057410 FCA_ESA_CtrlSta "FCA w/ ESA Control Status for ECS Control";
BA_ "UserSigValidity" SG_ 2223057410 FCA_ESA_CtrlSta 3;
BA_ "RoutingFactor" SG_ 2223057410 FCA_ESA_CtrlSta 5;
BA_ "Version" SG_ 2223057410 FCA_ESA_CtrlSta "18.10.00";
BA_ "Description" SG_ 2223057410 FCA_LS_WrnSta "This signal indicates FCA-LS warning for display and sound.";
BA_ "UserSigValidity" SG_ 2223057410 FCA_LS_WrnSta 3;
BA_ "RoutingFactor" SG_ 2223057410 FCA_LS_WrnSta 5;
BA_ "Version" SG_ 2223057410 FCA_LS_WrnSta "17.11.00";
BA_ "Description" SG_ 2223057410 ADAS_Damping_Gain "ADAS Damping Gain for MDPS";
BA_ "GenSigStartValue" SG_ 2223057410 ADAS_Damping_Gain 100;
BA_ "UserSigValidity" SG_ 2223057410 ADAS_Damping_Gain 3;
BA_ "RoutingFactor" SG_ 2223057410 ADAS_Damping_Gain 5;
BA_ "Version" SG_ 2223057410 ADAS_Damping_Gain "18.12.01";
BA_ "Description" SG_ 2223057410 ADAS_StrAngReqVal "Request angle control value";
BA_ "UserSigValidity" SG_ 2223057410 ADAS_StrAngReqVal 3;
BA_ "RoutingFactor" SG_ 2223057410 ADAS_StrAngReqVal 5;
BA_ "Version" SG_ 2223057410 ADAS_StrAngReqVal "19.08.05";
BA_ "Description" SG_ 2223057410 LKA_OnOffEquip2Sta "Signal to turn LKA function on and off in USM. When USM content for LKA function is just a toggle button, this signal can be used.";
BA_ "UserSigValidity" SG_ 2223057410 LKA_OnOffEquip2Sta 3;
BA_ "RoutingFactor" SG_ 2223057410 LKA_OnOffEquip2Sta 5;
BA_ "Version" SG_ 2223057410 LKA_OnOffEquip2Sta "20.12.00";
BA_ "GenMsgSendType" BO_ 2273435649 0;
BA_ "GenMsgCycleTime" BO_ 2273435649 150;
BA_ "GenMsgCycleTimeFast" BO_ 2273435649 0;
BA_ "GenMsgNrOfRepetition" BO_ 2273435649 0;
BA_ "VFrameFormat" BO_ 2273435649 1;
BA_ "Description" SG_ 2273435649 ADAS_CMD_Crc31Val "The data area for CRC calculation is based on the data length (DLC) of the message DB.

The CRC shall be calculated over the entire data block (excluding the CRC bytes) including the user data, alive counter and Data ID

 

- CRC Polynomial (0x1021) , Initial Value : 0xFFFF, XOR value : 0x0000, Data ID : Message ID + 0xF800 

- The initial value is for CRC calculation and the message should be sent with the calculated result value. 

- The mathematical expression to 16 bit CRC polynomial is given here. G(x) = x16 + x12 + x5 + 1";
BA_ "UserSigValidity" SG_ 2273435649 ADAS_CMD_Crc31Val 3;
BA_ "RoutingFactor" SG_ 2273435649 ADAS_CMD_Crc31Val 3;
BA_ "Version" SG_ 2273435649 ADAS_CMD_Crc31Val "18.11.08";
BA_ "Description" SG_ 2273435649 ADAS_CMD_AlvCnt31Val "For the first transmission request for a data element the counter shall be initialized with 0 and shall be incremented by 1 for every subsequent send request. 

When the counter reaches the maximum value(0xFF), then it shall restart with 0 for the next send request";
BA_ "UserSigValidity" SG_ 2273435649 ADAS_CMD_AlvCnt31Val 3;
BA_ "RoutingFactor" SG_ 2273435649 ADAS_CMD_AlvCnt31Val 3;
BA_ "Version" SG_ 2273435649 ADAS_CMD_AlvCnt31Val "18.11.08";
BA_ "Description" SG_ 2273435649 HDA_OptUsmSta "This is HDA system status needed for the cluster USM display.";
BA_ "UserSigValidity" SG_ 2273435649 HDA_OptUsmSta 3;
BA_ "RoutingFactor" SG_ 2273435649 HDA_OptUsmSta 3;
BA_ "Version" SG_ 2273435649 HDA_OptUsmSta "17.12.02";
BA_ "Description" SG_ 2273435649 HDA_CntrlModSta "This is HDA Control Mode needed for longitudinal/lateral control and cluster display.";
BA_ "UserSigValidity" SG_ 2273435649 HDA_CntrlModSta 3;
BA_ "RoutingFactor" SG_ 2273435649 HDA_CntrlModSta 3;
BA_ "Version" SG_ 2273435649 HDA_CntrlModSta "20.05.02";
BA_ "Description" SG_ 2273435649 HDA_InfoPUDis "This is HDA information display needed for the cluster pop-up display.";
BA_ "UserSigValidity" SG_ 2273435649 HDA_InfoPUDis 3;
BA_ "RoutingFactor" SG_ 2273435649 HDA_InfoPUDis 3;
BA_ "Version" SG_ 2273435649 HDA_InfoPUDis "21.10.02";
BA_ "Description" SG_ 2273435649 HDP_AutoCallReqSta "This signal is needed for HDP Auto Call.";
BA_ "UserSigValidity" SG_ 2273435649 HDP_AutoCallReqSta 3;
BA_ "RoutingFactor" SG_ 2273435649 HDP_AutoCallReqSta 3;
BA_ "Version" SG_ 2273435649 HDP_AutoCallReqSta "21.04.03";
BA_ "Description" SG_ 2273435649 HDP_DispBarSta "This signal indicates HDP operation state (always not covered other display)";
BA_ "UserSigValidity" SG_ 2273435649 HDP_DispBarSta 0;
BA_ "RoutingFactor" SG_ 2273435649 HDP_DispBarSta 3;
BA_ "Version" SG_ 2273435649 HDP_DispBarSta "21.03.11";
BA_ "Description" SG_ 2273435649 HDP_OptInfoSta "This signal indicates whether the HDP system has been applied or not.";
BA_ "UserSigValidity" SG_ 2273435649 HDP_OptInfoSta 0;
BA_ "RoutingFactor" SG_ 2273435649 HDP_OptInfoSta 3;
BA_ "Version" SG_ 2273435649 HDP_OptInfoSta "21.03.11";
BA_ "Description" SG_ 2273435649 HDA_LFA_SymSta "This signal shows the state of steering assist.";
BA_ "UserSigValidity" SG_ 2273435649 HDA_LFA_SymSta 3;
BA_ "RoutingFactor" SG_ 2273435649 HDA_LFA_SymSta 3;
BA_ "Version" SG_ 2273435649 HDA_LFA_SymSta "20.11.02";
BA_ "Description" SG_ 2273435649 HDA_LFA_WrnSnd "HDA/LFA Additional Warning Sound";
BA_ "UserSigValidity" SG_ 2273435649 HDA_LFA_WrnSnd 3;
BA_ "RoutingFactor" SG_ 2273435649 HDA_LFA_WrnSnd 3;
BA_ "Version" SG_ 2273435649 HDA_LFA_WrnSnd "18.02.03";
BA_ "Description" SG_ 2273435649 HDA_InfoPUDis1 "This is HDA/LFA information display needed for the cluster pop-up display.";
BA_ "UserSigValidity" SG_ 2273435649 HDA_InfoPUDis1 3;
BA_ "RoutingFactor" SG_ 2273435649 HDA_InfoPUDis1 3;
BA_ "Version" SG_ 2273435649 HDA_InfoPUDis1 "21.01.08";
BA_ "Description" SG_ 2273435649 HDA_TDMRMDclReq "This signal show the state of LFA automatic deactivation.";
BA_ "UserSigValidity" SG_ 2273435649 HDA_TDMRMDclReq 3;
BA_ "RoutingFactor" SG_ 2273435649 HDA_TDMRMDclReq 3;
BA_ "Version" SG_ 2273435649 HDA_TDMRMDclReq "19.02.00";
BA_ "Description" SG_ 2273435649 HDP_ActvSta "This signal indicates control active status of HDP.";
BA_ "UserSigValidity" SG_ 2273435649 HDP_ActvSta 3;
BA_ "RoutingFactor" SG_ 2273435649 HDP_ActvSta 3;
BA_ "Version" SG_ 2273435649 HDP_ActvSta "19.11.02";
BA_ "Description" SG_ 2273435649 HDP_SysSta "This signal indicates system status of HDP.";
BA_ "UserSigValidity" SG_ 2273435649 HDP_SysSta 3;
BA_REL_ "GenSigTimeoutTime" BU_SG_REL_ HOD SG_ 2273435649 HDP_SysSta 1500;
BA_ "RoutingFactor" SG_ 2273435649 HDP_SysSta 3;
BA_ "Version" SG_ 2273435649 HDP_SysSta "20.07.10";
BA_ "Description" SG_ 2273435649 HDP_FailureMode "This signal shows HDP failure status";
BA_ "UserSigValidity" SG_ 2273435649 HDP_FailureMode 3;
BA_ "RoutingFactor" SG_ 2273435649 HDP_FailureMode 3;
BA_ "Version" SG_ 2273435649 HDP_FailureMode "20.07.10";
BA_ "GenMsgSendType" BO_ 2273435650 0;
BA_ "GenMsgCycleTime" BO_ 2273435650 150;
BA_ "GenMsgCycleTimeFast" BO_ 2273435650 0;
BA_ "GenMsgNrOfRepetition" BO_ 2273435650 0;
BA_ "VFrameFormat" BO_ 2273435650 1;
BA_ "Description" SG_ 2273435650 HDP_ObstacleDstVal "This signal indicates distance to a obstacle which is on driving path.";
BA_ "GenSigStartValue" SG_ 2273435650 HDP_ObstacleDstVal 2046;
BA_ "UserSigValidity" SG_ 2273435650 HDP_ObstacleDstVal 3;
BA_ "RoutingFactor" SG_ 2273435650 HDP_ObstacleDstVal 3;
BA_ "Version" SG_ 2273435650 HDP_ObstacleDstVal "19.11.02";
BA_ "Description" SG_ 2273435650 HDP_ObstacleLatPosVal "This signal indicates distance to a obstacle which is on driving path.";
BA_ "GenSigStartValue" SG_ 2273435650 HDP_ObstacleLatPosVal 510;
BA_ "UserSigValidity" SG_ 2273435650 HDP_ObstacleLatPosVal 3;
BA_ "RoutingFactor" SG_ 2273435650 HDP_ObstacleLatPosVal 3;
BA_ "Version" SG_ 2273435650 HDP_ObstacleLatPosVal "19.11.02";
BA_ "Description" SG_ 2273435650 HDP_InfoPUDis "This signal needed for the cluster pop-up display to inform HDP system status and warning.";
BA_ "UserSigValidity" SG_ 2273435650 HDP_InfoPUDis 3;
BA_ "RoutingFactor" SG_ 2273435650 HDP_InfoPUDis 3;
BA_ "Version" SG_ 2273435650 HDP_InfoPUDis "20.09.00";
BA_ "Description" SG_ 2273435650 HDP_WrngTypPUDis "This signal is needed for the cluster mini pop-up display to inform a reason of unavailable/TD activation or warning messages.";
BA_ "UserSigValidity" SG_ 2273435650 HDP_WrngTypPUDis 3;
BA_ "RoutingFactor" SG_ 2273435650 HDP_WrngTypPUDis 3;
BA_ "Version" SG_ 2273435650 HDP_WrngTypPUDis "20.03.01";
BA_ "Description" SG_ 2273435650 HDP_HapticWarnReq "This signal is needed for HDP haptic warning";
BA_ "UserSigValidity" SG_ 2273435650 HDP_HapticWarnReq 3;
BA_REL_ "GenSigTimeoutTime" BU_SG_REL_ PSB SG_ 2273435650 HDP_HapticWarnReq 1500;
BA_ "RoutingFactor" SG_ 2273435650 HDP_HapticWarnReq 3;
BA_ "Version" SG_ 2273435650 HDP_HapticWarnReq "20.03.01";
BA_ "Description" SG_ 2273435650 HDP_ActvStaDis "This signal is needed for the cluster symbol display to inform a activation or deactivation status";
BA_ "UserSigValidity" SG_ 2273435650 HDP_ActvStaDis 3;
BA_ "RoutingFactor" SG_ 2273435650 HDP_ActvStaDis 3;
BA_ "Version" SG_ 2273435650 HDP_ActvStaDis "20.03.01";
BA_ "Description" SG_ 2273435650 HDP_OpStaDisp "This signal is needed for the cluster symbol display to inform highway driving pilot status";
BA_ "UserSigValidity" SG_ 2273435650 HDP_OpStaDisp 3;
BA_ "RoutingFactor" SG_ 2273435650 HDP_OpStaDisp 3;
BA_ "Version" SG_ 2273435650 HDP_OpStaDisp "20.06.01";
BA_ "Description" SG_ 2273435650 HDP_ObstSta "This signal represents the state of in-path obstacle and information of controllable state.

- ÀÚÂ÷¼±»óÀÇ Àü¹æ ÀÏ¹Ý¹°Ã¼ ÀÎ½Ä ¿©ºÎ ¹× Á¦¾î °¡´É »óÅÂ Á¤º¸";
BA_ "UserSigValidity" SG_ 2273435650 HDP_ObstSta 3;
BA_ "RoutingFactor" SG_ 2273435650 HDP_ObstSta 3;
BA_ "Version" SG_ 2273435650 HDP_ObstSta "20.06.01";
BA_ "Description" SG_ 2273435650 HDP_SysFlrDisp "This signal is for pop-up indication of HDP system failure.

If this signal is set to 1, the display device shall indicate HDP failure information to the driver.";
BA_ "UserSigValidity" SG_ 2273435650 HDP_SysFlrDisp 3;
BA_ "RoutingFactor" SG_ 2273435650 HDP_SysFlrDisp 3;
BA_ "Version" SG_ 2273435650 HDP_SysFlrDisp "20.09.00";
BA_ "Description" SG_ 2273435650 HDP_InhbtOffDispSta "This signal is shows that driving safety functions are inhibited while HDP in operation";
BA_ "UserSigValidity" SG_ 2273435650 HDP_InhbtOffDispSta 3;
BA_ "RoutingFactor" SG_ 2273435650 HDP_InhbtOffDispSta 3;
BA_ "Version" SG_ 2273435650 HDP_InhbtOffDispSta "20.12.04";
BA_ "Description" SG_ 2273435650 HDP_CtRoadSrfcDistVal "This signal is notifying how far to display the road surfaces.";
BA_ "GenSigStartValue" SG_ 2273435650 HDP_CtRoadSrfcDistVal 2046;
BA_ "UserSigValidity" SG_ 2273435650 HDP_CtRoadSrfcDistVal 3;
BA_ "RoutingFactor" SG_ 2273435650 HDP_CtRoadSrfcDistVal 3;
BA_ "Version" SG_ 2273435650 HDP_CtRoadSrfcDistVal "21.03.11";
BA_ "Description" SG_ 2273435650 ADAS_DRV_UpDateInfo "ADAS_DRV update state info for AVN";
BA_ "GenSigStartValue" SG_ 2273435650 ADAS_DRV_UpDateInfo 1;
BA_ "UserSigValidity" SG_ 2273435650 ADAS_DRV_UpDateInfo 3;
BA_ "RoutingFactor" SG_ 2273435650 ADAS_DRV_UpDateInfo 3;
BA_ "Version" SG_ 2273435650 ADAS_DRV_UpDateInfo "20.10.02";
BA_ "GenMsgSendType" BO_ 2244046849 0;
BA_ "GenMsgCycleTime" BO_ 2244046849 100;
BA_ "GenMsgCycleTimeFast" BO_ 2244046849 0;
BA_ "GenMsgNrOfRepetition" BO_ 2244046849 0;
BA_ "VFrameFormat" BO_ 2244046849 1;
BA_ "Description" SG_ 2244046849 ADAS_PRK_Crc1Val "The data area for CRC calculation is based on the data length (DLC) of the message DB.

The CRC shall be calculated over the entire data block (excluding the CRC bytes) including the user data, alive counter and Data ID

 

- CRC Polynomial (0x1021) , Initial Value : 0xFFFF, XOR value : 0x0000, Data ID : Message ID + 0xF800 

- The initial value is for CRC calculation and the message should be sent with the calculated result value. 

- The mathematical expression to 16 bit CRC polynomial is given here. G(x) = x16 + x12 + x5 + 1";
BA_ "GenSigStartValue" SG_ 2244046849 ADAS_PRK_Crc1Val 65535;
BA_ "UserSigValidity" SG_ 2244046849 ADAS_PRK_Crc1Val 3;
BA_ "RoutingFactor" SG_ 2244046849 ADAS_PRK_Crc1Val 5;
BA_ "Version" SG_ 2244046849 ADAS_PRK_Crc1Val "18.11.08";
BA_ "Description" SG_ 2244046849 ADAS_PRK_AlvCnt1Val "For the first transmission request for a data element the counter shall be initialized with 0 and shall be incremented by 1 for every subsequent send request. 

When the counter reaches the maximum value(0xFF), then it shall restart with 0 for the next send request";
BA_ "UserSigValidity" SG_ 2244046849 ADAS_PRK_AlvCnt1Val 3;
BA_ "RoutingFactor" SG_ 2244046849 ADAS_PRK_AlvCnt1Val 5;
BA_ "Version" SG_ 2244046849 ADAS_PRK_AlvCnt1Val "18.11.08";
BA_ "Description" SG_ 2244046849 PCA_RrEquipSta "PCA Rear Equipment Status";
BA_ "UserSigValidity" SG_ 2244046849 PCA_RrEquipSta 3;
BA_ "RoutingFactor" SG_ 2244046849 PCA_RrEquipSta 5;
BA_ "Version" SG_ 2244046849 PCA_RrEquipSta "19.10.03";
BA_ "Description" SG_ 2244046849 PCA_SysFlrSta "PCA Failure status";
BA_ "UserSigValidity" SG_ 2244046849 PCA_SysFlrSta 3;
BA_ "RoutingFactor" SG_ 2244046849 PCA_SysFlrSta 5;
BA_ "Version" SG_ 2244046849 PCA_SysFlrSta "21.02.00";
BA_ "Description" SG_ 2244046849 PCA_RrWrngLvlSta "PCA Rear Warning level status";
BA_ "UserSigValidity" SG_ 2244046849 PCA_RrWrngLvlSta 3;
BA_ "RoutingFactor" SG_ 2244046849 PCA_RrWrngLvlSta 5;
BA_ "Version" SG_ 2244046849 PCA_RrWrngLvlSta "19.10.03";
BA_ "Description" SG_ 2244046849 PCA_ModDis "PCA Mode Display";
BA_ "UserSigValidity" SG_ 2244046849 PCA_ModDis 3;
BA_ "RoutingFactor" SG_ 2244046849 PCA_ModDis 5;
BA_ "Version" SG_ 2244046849 PCA_ModDis "20.02.01";
BA_ "Description" SG_ 2244046849 PCA_WrngSndCtSta "Warning sound center status";
BA_ "UserSigValidity" SG_ 2244046849 PCA_WrngSndCtSta 3;
BA_ "RoutingFactor" SG_ 2244046849 PCA_WrngSndCtSta 5;
BA_ "Version" SG_ 2244046849 PCA_WrngSndCtSta "20.01.01";
BA_ "Description" SG_ 2244046849 PCA_WrngSndLtSta "Warning sound left status";
BA_ "UserSigValidity" SG_ 2244046849 PCA_WrngSndLtSta 3;
BA_ "RoutingFactor" SG_ 2244046849 PCA_WrngSndLtSta 5;
BA_ "Version" SG_ 2244046849 PCA_WrngSndLtSta "20.01.01";
BA_ "Description" SG_ 2244046849 PCA_WrngSndRtSta "Warning sound right status";
BA_ "UserSigValidity" SG_ 2244046849 PCA_WrngSndRtSta 3;
BA_ "RoutingFactor" SG_ 2244046849 PCA_WrngSndRtSta 5;
BA_ "Version" SG_ 2244046849 PCA_WrngSndRtSta "17.12.00";
BA_ "Description" SG_ 2244046849 PCA_HptReq "PCA Haptic Request";
BA_ "UserSigValidity" SG_ 2244046849 PCA_HptReq 3;
BA_ "RoutingFactor" SG_ 2244046849 PCA_HptReq 5;
BA_ "Version" SG_ 2244046849 PCA_HptReq "20.02.03";
BA_ "Description" SG_ 2244046849 PCA_BrkReq "Brake request

with EPB : 0x2 PCA Brake on (hold)

without EPB : 0x1 PCA Brake on";
BA_ "UserSigValidity" SG_ 2244046849 PCA_BrkReq 3;
BA_ "RoutingFactor" SG_ 2244046849 PCA_BrkReq 5;
BA_ "Version" SG_ 2244046849 PCA_BrkReq "19.07.06";
BA_ "Description" SG_ 2244046849 PCA_EpbReq "request to hold the vehicle, applying EPB";
BA_ "UserSigValidity" SG_ 2244046849 PCA_EpbReq 3;
BA_ "RoutingFactor" SG_ 2244046849 PCA_EpbReq 5;
BA_ "Version" SG_ 2244046849 PCA_EpbReq "19.07.06";
BA_ "Description" SG_ 2244046849 PCA_DclTrgtVal "Deceleration target value";
BA_ "UserSigValidity" SG_ 2244046849 PCA_DclTrgtVal 3;
BA_ "RoutingFactor" SG_ 2244046849 PCA_DclTrgtVal 5;
BA_ "Version" SG_ 2244046849 PCA_DclTrgtVal "18.07.01";
BA_ "Description" SG_ 2244046849 PU_F_Group7_DrvrAsstFlr10Sta "PDW & PCA Blockage / Failure Display (Full Pop-up)";
BA_ "UserSigValidity" SG_ 2244046849 PU_F_Group7_DrvrAsstFlr10Sta 3;
BA_ "RoutingFactor" SG_ 2244046849 PU_F_Group7_DrvrAsstFlr10Sta 5;
BA_ "Version" SG_ 2244046849 PU_F_Group7_DrvrAsstFlr10Sta "22.01.06";
BA_ "Description" SG_ 2244046849 ADAS_PRK_PDW_SysFlrSta "PDW Failure Status";
BA_ "UserSigValidity" SG_ 2244046849 ADAS_PRK_PDW_SysFlrSta 3;
BA_ "RoutingFactor" SG_ 2244046849 ADAS_PRK_PDW_SysFlrSta 5;
BA_ "Version" SG_ 2244046849 ADAS_PRK_PDW_SysFlrSta "20.11.02";
BA_ "GenMsgSendType" BO_ 2244046850 0;
BA_ "GenMsgCycleTime" BO_ 2244046850 100;
BA_ "GenMsgCycleTimeFast" BO_ 2244046850 0;
BA_ "GenMsgNrOfRepetition" BO_ 2244046850 0;
BA_ "VFrameFormat" BO_ 2244046850 1;
BA_ "Description" SG_ 2244046850 ADAS_PRK_PDW_SwIndOnReq "-PDW Switch Indicator On/Off Request

This signal is used for PDW-R and PDW-F/R";
BA_ "UserSigValidity" SG_ 2244046850 ADAS_PRK_PDW_SwIndOnReq 3;
BA_REL_ "GenSigTimeoutTime" BU_SG_REL_ FCS SG_ 2244046850 ADAS_PRK_PDW_SwIndOnReq 1500;
BA_ "RoutingFactor" SG_ 2244046850 ADAS_PRK_PDW_SwIndOnReq 5;
BA_ "Version" SG_ 2244046850 ADAS_PRK_PDW_SwIndOnReq "18.05.02";
BA_ "Description" SG_ 2244046850 PCA_RrEquipChkSta "PCA Rear Equipment Check Status";
BA_ "UserSigValidity" SG_ 2244046850 PCA_RrEquipChkSta 3;
BA_ "RoutingFactor" SG_ 2244046850 PCA_RrEquipChkSta 5;
BA_ "Version" SG_ 2244046850 PCA_RrEquipChkSta "20.05.02";
BA_ "Description" SG_ 2244046850 PCA_FrWrngLvlSta "PCA Front warning level status";
BA_ "UserSigValidity" SG_ 2244046850 PCA_FrWrngLvlSta 3;
BA_ "RoutingFactor" SG_ 2244046850 PCA_FrWrngLvlSta 5;
BA_ "Version" SG_ 2244046850 PCA_FrWrngLvlSta "19.10.03";
BA_ "Description" SG_ 2244046850 PCA_LtWrngLvlSta "PCA Left warning level status";
BA_ "UserSigValidity" SG_ 2244046850 PCA_LtWrngLvlSta 3;
BA_ "RoutingFactor" SG_ 2244046850 PCA_LtWrngLvlSta 5;
BA_ "Version" SG_ 2244046850 PCA_LtWrngLvlSta "20.01.01";
BA_ "Description" SG_ 2244046850 ADAS_PRK_PDW_OptTyp "this signal means PDW Option (Non, PDW-R, PDW-FR, PDW-FSR)";
BA_ "UserSigValidity" SG_ 2244046850 ADAS_PRK_PDW_OptTyp 3;
BA_ "RoutingFactor" SG_ 2244046850 ADAS_PRK_PDW_OptTyp 5;
BA_ "Version" SG_ 2244046850 ADAS_PRK_PDW_OptTyp "20.11.02";
BA_ "Description" SG_ 2244046850 PCA_RtWrngLvlSta "PCA Right warning level status";
BA_ "UserSigValidity" SG_ 2244046850 PCA_RtWrngLvlSta 3;
BA_ "RoutingFactor" SG_ 2244046850 PCA_RtWrngLvlSta 5;
BA_ "Version" SG_ 2244046850 PCA_RtWrngLvlSta "19.08.08";
BA_ "Description" SG_ 2244046850 PCA_RrFlrDis "PCA Rear Failure Display";
BA_ "UserSigValidity" SG_ 2244046850 PCA_RrFlrDis 3;
BA_ "RoutingFactor" SG_ 2244046850 PCA_RrFlrDis 5;
BA_ "Version" SG_ 2244046850 PCA_RrFlrDis "19.10.04";
BA_ "Description" SG_ 2244046850 PCA_FrFlrDis "PCA Front Failure Display";
BA_ "UserSigValidity" SG_ 2244046850 PCA_FrFlrDis 3;
BA_ "RoutingFactor" SG_ 2244046850 PCA_FrFlrDis 5;
BA_ "Version" SG_ 2244046850 PCA_FrFlrDis "19.10.04";
BA_ "Description" SG_ 2244046850 PCA_LtFlrDis "PCA Left Failure Display";
BA_ "UserSigValidity" SG_ 2244046850 PCA_LtFlrDis 3;
BA_ "RoutingFactor" SG_ 2244046850 PCA_LtFlrDis 5;
BA_ "Version" SG_ 2244046850 PCA_LtFlrDis "20.01.01";
BA_ "Description" SG_ 2244046850 PCA_RtFlrDis "PCA Right Failure Display";
BA_ "UserSigValidity" SG_ 2244046850 PCA_RtFlrDis 3;
BA_ "RoutingFactor" SG_ 2244046850 PCA_RtFlrDis 5;
BA_ "Version" SG_ 2244046850 PCA_RtFlrDis "19.10.04";
BA_ "UserSigValidity" SG_ 2244046850 PCA_FrBndryLn 3;
BA_ "RoutingFactor" SG_ 2244046850 PCA_FrBndryLn 5;
BA_ "Version" SG_ 2244046850 PCA_FrBndryLn "21.04.09";
BA_ "UserSigValidity" SG_ 2244046850 PCA_RrBndryLn 3;
BA_ "RoutingFactor" SG_ 2244046850 PCA_RrBndryLn 5;
BA_ "Version" SG_ 2244046850 PCA_RrBndryLn "21.04.09";
BA_ "UserSigValidity" SG_ 2244046850 PCA_LtBndryLn 3;
BA_ "RoutingFactor" SG_ 2244046850 PCA_LtBndryLn 5;
BA_ "Version" SG_ 2244046850 PCA_LtBndryLn "21.04.09";
BA_ "UserSigValidity" SG_ 2244046850 PCA_RtBndryLn 3;
BA_ "RoutingFactor" SG_ 2244046850 PCA_RtBndryLn 5;
BA_ "Version" SG_ 2244046850 PCA_RtBndryLn "21.04.09";
BA_ "UserSigValidity" SG_ 2244046850 PCA_WrngPhrs 3;
BA_ "RoutingFactor" SG_ 2244046850 PCA_WrngPhrs 5;
BA_ "Version" SG_ 2244046850 PCA_WrngPhrs "21.04.09";
BA_ "Description" SG_ 2244046850 ADAS_PRK_PDW_AutoOn_USM "PDW system automatically on/off setting status";
BA_ "UserSigValidity" SG_ 2244046850 ADAS_PRK_PDW_AutoOn_USM 3;
BA_ "RoutingFactor" SG_ 2244046850 ADAS_PRK_PDW_AutoOn_USM 5;
BA_ "Version" SG_ 2244046850 ADAS_PRK_PDW_AutoOn_USM "18.05.02";
BA_ "Description" SG_ 2244046850 PCA_FrSdEquipChkSta "PCA Front Side Equipment Check Status";
BA_ "UserSigValidity" SG_ 2244046850 PCA_FrSdEquipChkSta 3;
BA_ "RoutingFactor" SG_ 2244046850 PCA_FrSdEquipChkSta 5;
BA_ "Version" SG_ 2244046850 PCA_FrSdEquipChkSta "20.05.02";
BA_ "GenMsgSendType" BO_ 1133 0;
BA_ "GenSigSendType" SG_ 1133 APSU_AstStEsyAcsUSMSta 4;
BA_ "UserSigValidity" SG_ 1133 APSU_AstStEsyAcsUSMSta 0;
BA_REL_ "GenSigTimeoutTime" BU_SG_REL_ ALBCU SG_ 1133 APSU_AstStEsyAcsUSMSta 1500;
BA_REL_ "GenSigTimeoutTime" BU_SG_REL_ CGW_CCU SG_ 1133 APSU_AstStEsyAcsUSMSta 1500;
BA_ "NetworkRequest" SG_ 1133 APSU_AstStEsyAcsUSMSta 0;
BA_ "NetworkRequestHoldingTime" SG_ 1133 APSU_AstStEsyAcsUSMSta 5000;
BA_ "Version" SG_ 1133 APSU_AstStEsyAcsUSMSta "18.02.01";
BA_ "Description" SG_ 1133 APSU_AstReturnModeSta "APSU_AssistReturnModeState";
BA_ "GenSigSendType" SG_ 1133 APSU_AstReturnModeSta 4;
BA_ "UserSigValidity" SG_ 1133 APSU_AstReturnModeSta 0;
BA_REL_ "GenSigTimeoutTime" BU_SG_REL_ CGW_CCU SG_ 1133 APSU_AstReturnModeSta 1500;
BA_ "NetworkRequest" SG_ 1133 APSU_AstReturnModeSta 0;
BA_ "NetworkRequestHoldingTime" SG_ 1133 APSU_AstReturnModeSta 5000;
BA_ "Version" SG_ 1133 APSU_AstReturnModeSta "19.12.00";
BA_ "GenSigSendType" SG_ 1133 APSU_CntryConfigTyp 4;
BA_ "UserSigValidity" SG_ 1133 APSU_CntryConfigTyp 0;
BA_ "NetworkRequest" SG_ 1133 APSU_CntryConfigTyp 0;
BA_ "NetworkRequestHoldingTime" SG_ 1133 APSU_CntryConfigTyp 5000;
BA_ "Version" SG_ 1133 APSU_CntryConfigTyp "21.07.06";
BA_ "Description" SG_ 1133 APSU_AutoHtrCtrlUSMSta "-(Old)C_AstAutoHeatRValue";
BA_ "GenSigSendType" SG_ 1133 APSU_AutoHtrCtrlUSMSta 4;
BA_ "UserSigValidity" SG_ 1133 APSU_AutoHtrCtrlUSMSta 0;
BA_ "NetworkRequest" SG_ 1133 APSU_AutoHtrCtrlUSMSta 0;
BA_ "NetworkRequestHoldingTime" SG_ 1133 APSU_AutoHtrCtrlUSMSta 5000;
BA_ "Version" SG_ 1133 APSU_AutoHtrCtrlUSMSta "18.02.01";
BA_ "Description" SG_ 1133 APSU_HtBlcUSMSta "Hetaer Balance Assistant USM R vaule";
BA_ "GenSigSendType" SG_ 1133 APSU_HtBlcUSMSta 4;
BA_ "UserSigValidity" SG_ 1133 APSU_HtBlcUSMSta 0;
BA_ "Version" SG_ 1133 APSU_HtBlcUSMSta "18.07.03";
BA_ "Description" SG_ 1133 APSU_AstAntPncMod "¾ÈÆ¼-ÇÉÄ¡ µ¿ÀÛ »óÅÂ Á¤º¸

Anti-Pinch Mode Operating Status Information";
BA_ "GenSigSendType" SG_ 1133 APSU_AstAntPncMod 4;
BA_ "UserSigValidity" SG_ 1133 APSU_AstAntPncMod 0;
BA_REL_ "GenSigTimeoutTime" BU_SG_REL_ RLPSU SG_ 1133 APSU_AstAntPncMod 1500;
BA_REL_ "GenSigTimeoutTime" BU_SG_REL_ RRPSU SG_ 1133 APSU_AstAntPncMod 1500;
BA_ "Version" SG_ 1133 APSU_AstAntPncMod "20.12.04";
BA_ "Description" SG_ 1133 APSU_AstOneTchFldModSta "¸®Å¬¶óÀÌ´× / ¿øÅÍÄ¡Æúµå ¸ðµå Á¤º¸

Assist Reclining / One-Touch Folding Mode Status Information";
BA_ "GenSigSendType" SG_ 1133 APSU_AstOneTchFldModSta 4;
BA_ "UserSigValidity" SG_ 1133 APSU_AstOneTchFldModSta 0;
BA_REL_ "GenSigTimeoutTime" BU_SG_REL_ RLPSU SG_ 1133 APSU_AstOneTchFldModSta 1500;
BA_REL_ "GenSigTimeoutTime" BU_SG_REL_ RRPSU SG_ 1133 APSU_AstOneTchFldModSta 1500;
BA_ "Version" SG_ 1133 APSU_AstOneTchFldModSta "20.12.04";
BA_ "Description" SG_ 1133 APSU_AstOneTchOperSta "¿øÅÍÄ¡ µ¿ÀÛ °¡´É ¿©ºÎ ¹× µ¿ÀÛ ¿Ï·á »óÅÂ Á¤º¸

One-Touch Operating Status Information";
BA_ "GenSigSendType" SG_ 1133 APSU_AstOneTchOperSta 4;
BA_ "UserSigValidity" SG_ 1133 APSU_AstOneTchOperSta 0;
BA_REL_ "GenSigTimeoutTime" BU_SG_REL_ RLPSU SG_ 1133 APSU_AstOneTchOperSta 1500;
BA_REL_ "GenSigTimeoutTime" BU_SG_REL_ RRPSU SG_ 1133 APSU_AstOneTchOperSta 1500;
BA_ "Version" SG_ 1133 APSU_AstOneTchOperSta "20.12.04";
BA_ "Description" SG_ 1133 APSU_AstRelaxModeSta "APSU_AssistRelaxModeState";
BA_ "GenSigSendType" SG_ 1133 APSU_AstRelaxModeSta 4;
BA_ "UserSigValidity" SG_ 1133 APSU_AstRelaxModeSta 0;
BA_REL_ "GenSigTimeoutTime" BU_SG_REL_ CGW_CCU SG_ 1133 APSU_AstRelaxModeSta 1500;
BA_ "NetworkRequest" SG_ 1133 APSU_AstRelaxModeSta 0;
BA_ "NetworkRequestHoldingTime" SG_ 1133 APSU_AstRelaxModeSta 5000;
BA_ "Version" SG_ 1133 APSU_AstRelaxModeSta "19.12.00";
BA_ "GenMsgSendType" BO_ 527 0;
BA_ "Description" SG_ 527 ATS_DrvStRseFwdBtn "¿îÀü¼® ¸ð´ÏÅÍ °¢µµ Á¶Àý Àü¹æ ÀÌµ¿";
BA_ "GenSigSendType" SG_ 527 ATS_DrvStRseFwdBtn 4;
BA_ "UserSigValidity" SG_ 527 ATS_DrvStRseFwdBtn 3;
BA_ "NetworkRequest" SG_ 527 ATS_DrvStRseFwdBtn 0;
BA_ "NetworkRequestHoldingTime" SG_ 527 ATS_DrvStRseFwdBtn 5000;
BA_ "Version" SG_ 527 ATS_DrvStRseFwdBtn "19.09.02";
BA_ "Description" SG_ 527 ATS_DrvStRseBwdBtn "¿îÀü¼® ¸ð´ÏÅÍ °¢µµ Á¶Àý ÈÄ¹æ ÀÌµ¿";
BA_ "GenSigSendType" SG_ 527 ATS_DrvStRseBwdBtn 4;
BA_ "UserSigValidity" SG_ 527 ATS_DrvStRseBwdBtn 3;
BA_ "NetworkRequest" SG_ 527 ATS_DrvStRseBwdBtn 0;
BA_ "NetworkRequestHoldingTime" SG_ 527 ATS_DrvStRseBwdBtn 5000;
BA_ "Version" SG_ 527 ATS_DrvStRseBwdBtn "19.09.02";
BA_ "Description" SG_ 527 ATS_RRRestModBtn "ÈÄ¼® RH REST ¸ðµå ÀÛµ¿";
BA_ "GenSigSendType" SG_ 527 ATS_RRRestModBtn 4;
BA_ "UserSigValidity" SG_ 527 ATS_RRRestModBtn 3;
BA_ "NetworkRequest" SG_ 527 ATS_RRRestModBtn 0;
BA_ "NetworkRequestHoldingTime" SG_ 527 ATS_RRRestModBtn 5000;
BA_ "Version" SG_ 527 ATS_RRRestModBtn "19.09.02";
BA_ "Description" SG_ 527 ATS_RRResetModBtn "ÈÄ¼® RH RETURN ¸ðµå ÀÛµ¿";
BA_ "GenSigSendType" SG_ 527 ATS_RRResetModBtn 4;
BA_ "UserSigValidity" SG_ 527 ATS_RRResetModBtn 3;
BA_ "NetworkRequest" SG_ 527 ATS_RRResetModBtn 0;
BA_ "NetworkRequestHoldingTime" SG_ 527 ATS_RRResetModBtn 5000;
BA_ "Version" SG_ 527 ATS_RRResetModBtn "19.09.02";
BA_ "Description" SG_ 527 ATS_RRAvWtcModBtn "ÈÄ¼® RH AVN ¸ðµå ÀÛµ¿";
BA_ "GenSigSendType" SG_ 527 ATS_RRAvWtcModBtn 4;
BA_ "UserSigValidity" SG_ 527 ATS_RRAvWtcModBtn 3;
BA_ "NetworkRequest" SG_ 527 ATS_RRAvWtcModBtn 0;
BA_ "NetworkRequestHoldingTime" SG_ 527 ATS_RRAvWtcModBtn 5000;
BA_ "Version" SG_ 527 ATS_RRAvWtcModBtn "19.09.02";
BA_ "Description" SG_ 527 ATS_RRReadingModBtn "ÈÄ¼® RH READING ¸ðµå ÀÛµ¿";
BA_ "GenSigSendType" SG_ 527 ATS_RRReadingModBtn 4;
BA_ "UserSigValidity" SG_ 527 ATS_RRReadingModBtn 3;
BA_ "NetworkRequest" SG_ 527 ATS_RRReadingModBtn 0;
BA_ "NetworkRequestHoldingTime" SG_ 527 ATS_RRReadingModBtn 5000;
BA_ "Version" SG_ 527 ATS_RRReadingModBtn "19.09.02";
BA_ "Description" SG_ 527 ATS_RLRestModBtn "ÈÄ¼® LH REST ¸ðµå ÀÛµ¿";
BA_ "GenSigSendType" SG_ 527 ATS_RLRestModBtn 4;
BA_ "UserSigValidity" SG_ 527 ATS_RLRestModBtn 3;
BA_ "NetworkRequest" SG_ 527 ATS_RLRestModBtn 0;
BA_ "NetworkRequestHoldingTime" SG_ 527 ATS_RLRestModBtn 5000;
BA_ "Version" SG_ 527 ATS_RLRestModBtn "19.09.02";
BA_ "Description" SG_ 527 ATS_RLResetModBtn "ÈÄ¼® LH RETURN ¸ðµå ÀÛµ¿";
BA_ "GenSigSendType" SG_ 527 ATS_RLResetModBtn 4;
BA_ "UserSigValidity" SG_ 527 ATS_RLResetModBtn 3;
BA_ "NetworkRequest" SG_ 527 ATS_RLResetModBtn 0;
BA_ "NetworkRequestHoldingTime" SG_ 527 ATS_RLResetModBtn 5000;
BA_ "Version" SG_ 527 ATS_RLResetModBtn "19.09.02";
BA_ "GenMsgSendType" BO_ 543 0;
BA_ "Description" SG_ 543 ATS_AstStSldFwdBtn "µ¿½Â¼® ½½¶óÀÌµù Àü¹æ ÀÌµ¿ (¿öÅ©ÀÎ ÀÛµ¿)";
BA_ "GenSigSendType" SG_ 543 ATS_AstStSldFwdBtn 4;
BA_ "UserSigValidity" SG_ 543 ATS_AstStSldFwdBtn 3;
BA_ "NetworkRequest" SG_ 543 ATS_AstStSldFwdBtn 0;
BA_ "NetworkRequestHoldingTime" SG_ 543 ATS_AstStSldFwdBtn 5000;
BA_ "Version" SG_ 543 ATS_AstStSldFwdBtn "19.09.02";
BA_ "Description" SG_ 543 ATS_AstStSldBwdBtn "µ¿½Â¼® ½½¶óÀÌµù ÈÄ¹æ ÀÌµ¿ (¿öÅ©ÀÎ ÀÛµ¿)";
BA_ "GenSigSendType" SG_ 543 ATS_AstStSldBwdBtn 4;
BA_ "UserSigValidity" SG_ 543 ATS_AstStSldBwdBtn 3;
BA_ "NetworkRequest" SG_ 543 ATS_AstStSldBwdBtn 0;
BA_ "NetworkRequestHoldingTime" SG_ 543 ATS_AstStSldBwdBtn 5000;
BA_ "Version" SG_ 543 ATS_AstStSldBwdBtn "19.09.02";
BA_ "Description" SG_ 543 ATS_AstStRclFwdBtn "µ¿½Â¼® ¸®Å¬¶óÀÌ´× Àü¹æ ÀÌµ¿ (¿öÅ©ÀÎ ÀÛµ¿)";
BA_ "GenSigSendType" SG_ 543 ATS_AstStRclFwdBtn 4;
BA_ "UserSigValidity" SG_ 543 ATS_AstStRclFwdBtn 3;
BA_ "NetworkRequest" SG_ 543 ATS_AstStRclFwdBtn 0;
BA_ "NetworkRequestHoldingTime" SG_ 543 ATS_AstStRclFwdBtn 5000;
BA_ "Version" SG_ 543 ATS_AstStRclFwdBtn "19.09.02";
BA_ "Description" SG_ 543 ATS_AstStRclBwdBtn "µ¿½Â¼® ¸®Å¬¶óÀÌ´× ÈÄ¹æ ÀÌµ¿ (¿öÅ©ÀÎ ÀÛµ¿)";
BA_ "GenSigSendType" SG_ 543 ATS_AstStRclBwdBtn 4;
BA_ "UserSigValidity" SG_ 543 ATS_AstStRclBwdBtn 3;
BA_ "NetworkRequest" SG_ 543 ATS_AstStRclBwdBtn 0;
BA_ "NetworkRequestHoldingTime" SG_ 543 ATS_AstStRclBwdBtn 5000;
BA_ "Version" SG_ 543 ATS_AstStRclBwdBtn "19.09.02";
BA_ "Description" SG_ 543 ATS_AstStHgtUpBtn "µ¿½Â¼® ÇÏÀÌÆ® ¾÷ ÀÌµ¿ (¿öÅ©ÀÎ ÀÛµ¿)";
BA_ "GenSigSendType" SG_ 543 ATS_AstStHgtUpBtn 4;
BA_ "UserSigValidity" SG_ 543 ATS_AstStHgtUpBtn 3;
BA_ "NetworkRequest" SG_ 543 ATS_AstStHgtUpBtn 0;
BA_ "NetworkRequestHoldingTime" SG_ 543 ATS_AstStHgtUpBtn 5000;
BA_ "Version" SG_ 543 ATS_AstStHgtUpBtn "19.09.02";
BA_ "Description" SG_ 543 ATS_AstStHgtDnBtn "µ¿½Â¼® ÇÏÀÌÆ® ´Ù¿î ÀÌµ¿ (¿öÅ©ÀÎ ÀÛµ¿)";
BA_ "GenSigSendType" SG_ 543 ATS_AstStHgtDnBtn 4;
BA_ "UserSigValidity" SG_ 543 ATS_AstStHgtDnBtn 3;
BA_ "NetworkRequest" SG_ 543 ATS_AstStHgtDnBtn 0;
BA_ "NetworkRequestHoldingTime" SG_ 543 ATS_AstStHgtDnBtn 5000;
BA_ "Version" SG_ 543 ATS_AstStHgtDnBtn "19.09.02";
BA_ "Description" SG_ 543 ATS_AstStHRestUpBtn "µ¿½Â¼® Çìµå·¹½ºÆ® ¾÷ ÀÌµ¿ (¿öÅ©ÀÎ ÀÛµ¿)";
BA_ "GenSigSendType" SG_ 543 ATS_AstStHRestUpBtn 4;
BA_ "UserSigValidity" SG_ 543 ATS_AstStHRestUpBtn 3;
BA_ "NetworkRequest" SG_ 543 ATS_AstStHRestUpBtn 0;
BA_ "NetworkRequestHoldingTime" SG_ 543 ATS_AstStHRestUpBtn 5000;
BA_ "Version" SG_ 543 ATS_AstStHRestUpBtn "19.09.02";
BA_ "Description" SG_ 543 ATS_AstStHRestDnBtn "µ¿½Â¼® Çìµå·¹½ºÆ® ´Ù¿î ÀÌµ¿ (¿öÅ©ÀÎ ÀÛµ¿)";
BA_ "GenSigSendType" SG_ 543 ATS_AstStHRestDnBtn 4;
BA_ "UserSigValidity" SG_ 543 ATS_AstStHRestDnBtn 3;
BA_ "NetworkRequest" SG_ 543 ATS_AstStHRestDnBtn 0;
BA_ "NetworkRequestHoldingTime" SG_ 543 ATS_AstStHRestDnBtn 5000;
BA_ "Version" SG_ 543 ATS_AstStHRestDnBtn "19.09.02";
BA_ "Description" SG_ 543 ATS_AstStHRestFwdBtn "µ¿½Â¼® Çìµå·¹½ºÆ® Àü¹æ ÀÌµ¿ (¿öÅ©ÀÎ ÀÛµ¿)";
BA_ "GenSigSendType" SG_ 543 ATS_AstStHRestFwdBtn 4;
BA_ "UserSigValidity" SG_ 543 ATS_AstStHRestFwdBtn 3;
BA_ "NetworkRequest" SG_ 543 ATS_AstStHRestFwdBtn 0;
BA_ "NetworkRequestHoldingTime" SG_ 543 ATS_AstStHRestFwdBtn 5000;
BA_ "Version" SG_ 543 ATS_AstStHRestFwdBtn "19.09.02";
BA_ "Description" SG_ 543 ATS_AstStHRestBwdBtn "µ¿½Â¼® Çìµå·¹½ºÆ® ÈÄ¹æ ÀÌµ¿ (¿öÅ©ÀÎ ÀÛµ¿)";
BA_ "GenSigSendType" SG_ 543 ATS_AstStHRestBwdBtn 4;
BA_ "UserSigValidity" SG_ 543 ATS_AstStHRestBwdBtn 3;
BA_ "NetworkRequest" SG_ 543 ATS_AstStHRestBwdBtn 0;
BA_ "NetworkRequestHoldingTime" SG_ 543 ATS_AstStHRestBwdBtn 5000;
BA_ "Version" SG_ 543 ATS_AstStHRestBwdBtn "19.09.02";
BA_ "Description" SG_ 543 ATS_AstStHRestFldBtn "µ¿½Â¼® Çìµå·¹½ºÆ® Æúµù ÀÌµ¿ (¿öÅ©ÀÎ ÀÛµ¿)";
BA_ "GenSigSendType" SG_ 543 ATS_AstStHRestFldBtn 4;
BA_ "UserSigValidity" SG_ 543 ATS_AstStHRestFldBtn 3;
BA_ "NetworkRequest" SG_ 543 ATS_AstStHRestFldBtn 0;
BA_ "NetworkRequestHoldingTime" SG_ 543 ATS_AstStHRestFldBtn 5000;
BA_ "Version" SG_ 543 ATS_AstStHRestFldBtn "19.09.02";
BA_ "Description" SG_ 543 ATS_AstStHRestUnFldBtn "µ¿½Â¼® Çìµå·¹½ºÆ® ¾ðÆúµù ÀÌµ¿ (¿öÅ©ÀÎ ÀÛµ¿)";
BA_ "GenSigSendType" SG_ 543 ATS_AstStHRestUnFldBtn 4;
BA_ "UserSigValidity" SG_ 543 ATS_AstStHRestUnFldBtn 3;
BA_ "NetworkRequest" SG_ 543 ATS_AstStHRestUnFldBtn 0;
BA_ "NetworkRequestHoldingTime" SG_ 543 ATS_AstStHRestUnFldBtn 5000;
BA_ "Version" SG_ 543 ATS_AstStHRestUnFldBtn "19.09.02";
BA_ "Description" SG_ 543 ATS_AstStRseFwdBtn "µ¿½Â¼® ¸ð´ÏÅÍ °¢µµ Á¶Àý Àü¹æ ÀÌµ¿";
BA_ "GenSigSendType" SG_ 543 ATS_AstStRseFwdBtn 4;
BA_ "UserSigValidity" SG_ 543 ATS_AstStRseFwdBtn 3;
BA_ "NetworkRequest" SG_ 543 ATS_AstStRseFwdBtn 0;
BA_ "NetworkRequestHoldingTime" SG_ 543 ATS_AstStRseFwdBtn 5000;
BA_ "Version" SG_ 543 ATS_AstStRseFwdBtn "19.09.02";
BA_ "Description" SG_ 543 ATS_AstStRseBwdBtn "µ¿½Â¼® ¸ð´ÏÅÍ °¢µµ Á¶Àý ÈÄ¹æ ÀÌµ¿";
BA_ "GenSigSendType" SG_ 543 ATS_AstStRseBwdBtn 4;
BA_ "UserSigValidity" SG_ 543 ATS_AstStRseBwdBtn 3;
BA_ "NetworkRequest" SG_ 543 ATS_AstStRseBwdBtn 0;
BA_ "NetworkRequestHoldingTime" SG_ 543 ATS_AstStRseBwdBtn 5000;
BA_ "Version" SG_ 543 ATS_AstStRseBwdBtn "19.09.02";
BA_ "Description" SG_ 543 ATS_AstStFRestFldBtn "µ¿½Â¼® Ç²·¹½ºÆ® Æúµù ÀÌµ¿ (¿öÅ©ÀÎ ÀÛµ¿)";
BA_ "GenSigSendType" SG_ 543 ATS_AstStFRestFldBtn 4;
BA_ "UserSigValidity" SG_ 543 ATS_AstStFRestFldBtn 3;
BA_ "NetworkRequest" SG_ 543 ATS_AstStFRestFldBtn 0;
BA_ "NetworkRequestHoldingTime" SG_ 543 ATS_AstStFRestFldBtn 5000;
BA_ "Version" SG_ 543 ATS_AstStFRestFldBtn "19.09.02";
BA_ "Description" SG_ 543 ATS_AstStFRestUnFldBtn "µ¿½Â¼® Ç²·¹½ºÆ® ¾ðÆúµù ÀÌµ¿ (¿öÅ©ÀÎ ÀÛµ¿)";
BA_ "GenSigSendType" SG_ 543 ATS_AstStFRestUnFldBtn 4;
BA_ "UserSigValidity" SG_ 543 ATS_AstStFRestUnFldBtn 3;
BA_ "NetworkRequest" SG_ 543 ATS_AstStFRestUnFldBtn 0;
BA_ "NetworkRequestHoldingTime" SG_ 543 ATS_AstStFRestUnFldBtn 5000;
BA_ "Version" SG_ 543 ATS_AstStFRestUnFldBtn "19.09.02";
BA_ "Description" SG_ 543 ATS_AstTltUpBtn "µ¿½Â¼® Æ¿Æ® UP ÀÌµ¿ (¿öÅ©ÀÎ ÀÛµ¿)";
BA_ "GenSigSendType" SG_ 543 ATS_AstTltUpBtn 4;
BA_ "UserSigValidity" SG_ 543 ATS_AstTltUpBtn 3;
BA_ "NetworkRequest" SG_ 543 ATS_AstTltUpBtn 0;
BA_ "NetworkRequestHoldingTime" SG_ 543 ATS_AstTltUpBtn 5000;
BA_ "Version" SG_ 543 ATS_AstTltUpBtn "19.12.00";
BA_ "Description" SG_ 543 ATS_AstTltDnBtn "µ¿½Â¼® Æ¿Æ® DOWN ÀÌµ¿ (¿öÅ©ÀÎ ÀÛµ¿)";
BA_ "GenSigSendType" SG_ 543 ATS_AstTltDnBtn 4;
BA_ "UserSigValidity" SG_ 543 ATS_AstTltDnBtn 3;
BA_ "NetworkRequest" SG_ 543 ATS_AstTltDnBtn 0;
BA_ "NetworkRequestHoldingTime" SG_ 543 ATS_AstTltDnBtn 5000;
BA_ "Version" SG_ 543 ATS_AstTltDnBtn "19.12.00";
BA_ "GenMsgSendType" BO_ 1141 0;
BA_ "Description" SG_ 1141 Ast_SHVU_SeatOptSta "µ¿½Â¼® ½ÃÆ®¿¡ Àû¿ëµÈ È÷ÅÍ/ÅëÇ³ ¿É¼Ç »ç¾ç";
BA_ "GenSigSendType" SG_ 1141 Ast_SHVU_SeatOptSta 4;
BA_ "UserSigValidity" SG_ 1141 Ast_SHVU_SeatOptSta 3;
BA_REL_ "GenSigTimeoutTime" BU_SG_REL_ FCS SG_ 1141 Ast_SHVU_SeatOptSta 1500;
BA_REL_ "GenSigTimeoutTime" BU_SG_REL_ CGW_CCU SG_ 1141 Ast_SHVU_SeatOptSta 1500;
BA_ "NetworkRequest" SG_ 1141 Ast_SHVU_SeatOptSta 0;
BA_ "NetworkRequestHoldingTime" SG_ 1141 Ast_SHVU_SeatOptSta 5000;
BA_ "Version" SG_ 1141 Ast_SHVU_SeatOptSta "19.01.04";
BA_ "Description" SG_ 1141 Ast_SHVU_HtSwHiIndSta "µ¿½Â¼® ½ÃÆ® ¿­¼± ½ºÀ§Ä¡ High Indicator Á¤º¸";
BA_ "GenSigSendType" SG_ 1141 Ast_SHVU_HtSwHiIndSta 4;
BA_ "UserSigValidity" SG_ 1141 Ast_SHVU_HtSwHiIndSta 3;
BA_REL_ "GenSigTimeoutTime" BU_SG_REL_ FCS SG_ 1141 Ast_SHVU_HtSwHiIndSta 1500;
BA_REL_ "GenSigTimeoutTime" BU_SG_REL_ CGW_CCU SG_ 1141 Ast_SHVU_HtSwHiIndSta 1500;
BA_ "NetworkRequest" SG_ 1141 Ast_SHVU_HtSwHiIndSta 0;
BA_ "NetworkRequestHoldingTime" SG_ 1141 Ast_SHVU_HtSwHiIndSta 5000;
BA_ "Version" SG_ 1141 Ast_SHVU_HtSwHiIndSta "19.01.04";
BA_ "Description" SG_ 1141 Ast_SHVU_HtSwMidIndSta "µ¿½Â¼® ½ÃÆ® ¿­¼± ½ºÀ§Ä¡ Mid Indicator Á¤º¸";
BA_ "GenSigSendType" SG_ 1141 Ast_SHVU_HtSwMidIndSta 4;
BA_ "UserSigValidity" SG_ 1141 Ast_SHVU_HtSwMidIndSta 3;
BA_REL_ "GenSigTimeoutTime" BU_SG_REL_ FCS SG_ 1141 Ast_SHVU_HtSwMidIndSta 1500;
BA_REL_ "GenSigTimeoutTime" BU_SG_REL_ CGW_CCU SG_ 1141 Ast_SHVU_HtSwMidIndSta 1500;
BA_ "NetworkRequest" SG_ 1141 Ast_SHVU_HtSwMidIndSta 0;
BA_ "NetworkRequestHoldingTime" SG_ 1141 Ast_SHVU_HtSwMidIndSta 5000;
BA_ "Version" SG_ 1141 Ast_SHVU_HtSwMidIndSta "19.01.04";
BA_ "Description" SG_ 1141 Ast_SHVU_HtSwLowIndSta "µ¿½Â¼® ½ÃÆ® ¿­¼± ½ºÀ§Ä¡ Low Indicator Á¤º¸";
BA_ "GenSigSendType" SG_ 1141 Ast_SHVU_HtSwLowIndSta 4;
BA_ "UserSigValidity" SG_ 1141 Ast_SHVU_HtSwLowIndSta 3;
BA_REL_ "GenSigTimeoutTime" BU_SG_REL_ FCS SG_ 1141 Ast_SHVU_HtSwLowIndSta 1500;
BA_REL_ "GenSigTimeoutTime" BU_SG_REL_ CGW_CCU SG_ 1141 Ast_SHVU_HtSwLowIndSta 1500;
BA_ "NetworkRequest" SG_ 1141 Ast_SHVU_HtSwLowIndSta 0;
BA_ "NetworkRequestHoldingTime" SG_ 1141 Ast_SHVU_HtSwLowIndSta 5000;
BA_ "Version" SG_ 1141 Ast_SHVU_HtSwLowIndSta "19.01.04";
BA_ "Description" SG_ 1141 Ast_SHVU_VntSwHiIndSta "µ¿½Â¼® ½ÃÆ® ÅëÇ³ ½ºÀ§Ä¡ High Indicator Á¤º¸";
BA_ "GenSigSendType" SG_ 1141 Ast_SHVU_VntSwHiIndSta 4;
BA_ "UserSigValidity" SG_ 1141 Ast_SHVU_VntSwHiIndSta 3;
BA_REL_ "GenSigTimeoutTime" BU_SG_REL_ FCS SG_ 1141 Ast_SHVU_VntSwHiIndSta 1500;
BA_REL_ "GenSigTimeoutTime" BU_SG_REL_ CGW_CCU SG_ 1141 Ast_SHVU_VntSwHiIndSta 1500;
BA_ "NetworkRequest" SG_ 1141 Ast_SHVU_VntSwHiIndSta 0;
BA_ "NetworkRequestHoldingTime" SG_ 1141 Ast_SHVU_VntSwHiIndSta 5000;
BA_ "Version" SG_ 1141 Ast_SHVU_VntSwHiIndSta "19.01.04";
BA_ "Description" SG_ 1141 Ast_SHVU_VntSwMidIndSta "µ¿½Â¼® ½ÃÆ® ÅëÇ³ ½ºÀ§Ä¡ Mid Indicator Á¤º¸";
BA_ "GenSigSendType" SG_ 1141 Ast_SHVU_VntSwMidIndSta 4;
BA_ "UserSigValidity" SG_ 1141 Ast_SHVU_VntSwMidIndSta 3;
BA_REL_ "GenSigTimeoutTime" BU_SG_REL_ FCS SG_ 1141 Ast_SHVU_VntSwMidIndSta 1500;
BA_REL_ "GenSigTimeoutTime" BU_SG_REL_ CGW_CCU SG_ 1141 Ast_SHVU_VntSwMidIndSta 1500;
BA_ "NetworkRequest" SG_ 1141 Ast_SHVU_VntSwMidIndSta 0;
BA_ "NetworkRequestHoldingTime" SG_ 1141 Ast_SHVU_VntSwMidIndSta 5000;
BA_ "Version" SG_ 1141 Ast_SHVU_VntSwMidIndSta "19.01.04";
BA_ "Description" SG_ 1141 Ast_SHVU_VntSwLowIndSta "µ¿½Â¼® ½ÃÆ® ÅëÇ³ ½ºÀ§Ä¡ Low Indicator Á¤º¸";
BA_ "GenSigSendType" SG_ 1141 Ast_SHVU_VntSwLowIndSta 4;
BA_ "UserSigValidity" SG_ 1141 Ast_SHVU_VntSwLowIndSta 3;
BA_REL_ "GenSigTimeoutTime" BU_SG_REL_ FCS SG_ 1141 Ast_SHVU_VntSwLowIndSta 1500;
BA_REL_ "GenSigTimeoutTime" BU_SG_REL_ CGW_CCU SG_ 1141 Ast_SHVU_VntSwLowIndSta 1500;
BA_ "NetworkRequest" SG_ 1141 Ast_SHVU_VntSwLowIndSta 0;
BA_ "NetworkRequestHoldingTime" SG_ 1141 Ast_SHVU_VntSwLowIndSta 5000;
BA_ "Version" SG_ 1141 Ast_SHVU_VntSwLowIndSta "19.01.04";
BA_ "Description" SG_ 1141 Ast_SHVU_HtBlcUSMSta "Hetaer Balance Assistant USM R vaule";
BA_ "GenSigSendType" SG_ 1141 Ast_SHVU_HtBlcUSMSta 4;
BA_ "UserSigValidity" SG_ 1141 Ast_SHVU_HtBlcUSMSta 0;
BA_REL_ "GenSigTimeoutTime" BU_SG_REL_ CGW_CCU SG_ 1141 Ast_SHVU_HtBlcUSMSta 1500;
BA_ "Version" SG_ 1141 Ast_SHVU_HtBlcUSMSta "19.01.04";
BA_ "Description" SG_ 1141 Ast_SHVU_SeatHtOperSta "µ¿½Â¼® ½ÃÆ® ÇöÀç ÀÛµ¿ ÁßÀÎ È÷ÅÍ/ÅëÇ³ ´Ü¼ö »óÅÂ";
BA_ "GenSigSendType" SG_ 1141 Ast_SHVU_SeatHtOperSta 4;
BA_ "UserSigValidity" SG_ 1141 Ast_SHVU_SeatHtOperSta 3;
BA_REL_ "GenSigTimeoutTime" BU_SG_REL_ CGW_CCU SG_ 1141 Ast_SHVU_SeatHtOperSta 1500;
BA_ "NetworkRequest" SG_ 1141 Ast_SHVU_SeatHtOperSta 0;
BA_ "NetworkRequestHoldingTime" SG_ 1141 Ast_SHVU_SeatHtOperSta 5000;
BA_ "Version" SG_ 1141 Ast_SHVU_SeatHtOperSta "19.01.04";
BA_ "Description" SG_ 1141 Ast_SHVU_HtSwHiIndSta_RHD "µ¿½Â¼® ½ÃÆ® ¿­¼± ½ºÀ§Ä¡ High Indicator Á¤º¸(RHD)";
BA_ "GenSigSendType" SG_ 1141 Ast_SHVU_HtSwHiIndSta_RHD 4;
BA_ "UserSigValidity" SG_ 1141 Ast_SHVU_HtSwHiIndSta_RHD 3;
BA_REL_ "GenSigTimeoutTime" BU_SG_REL_ FCS SG_ 1141 Ast_SHVU_HtSwHiIndSta_RHD 1500;
BA_REL_ "GenSigTimeoutTime" BU_SG_REL_ CGW_CCU SG_ 1141 Ast_SHVU_HtSwHiIndSta_RHD 1500;
BA_ "NetworkRequest" SG_ 1141 Ast_SHVU_HtSwHiIndSta_RHD 0;
BA_ "NetworkRequestHoldingTime" SG_ 1141 Ast_SHVU_HtSwHiIndSta_RHD 5000;
BA_ "Version" SG_ 1141 Ast_SHVU_HtSwHiIndSta_RHD "19.01.04";
BA_ "Description" SG_ 1141 Ast_SHVU_HtSwMidIndSta_RHD "µ¿½Â¼® ½ÃÆ® ¿­¼± ½ºÀ§Ä¡ Mid Indicator Á¤º¸(RHD)";
BA_ "GenSigSendType" SG_ 1141 Ast_SHVU_HtSwMidIndSta_RHD 4;
BA_ "UserSigValidity" SG_ 1141 Ast_SHVU_HtSwMidIndSta_RHD 3;
BA_REL_ "GenSigTimeoutTime" BU_SG_REL_ FCS SG_ 1141 Ast_SHVU_HtSwMidIndSta_RHD 1500;
BA_REL_ "GenSigTimeoutTime" BU_SG_REL_ CGW_CCU SG_ 1141 Ast_SHVU_HtSwMidIndSta_RHD 1500;
BA_ "NetworkRequest" SG_ 1141 Ast_SHVU_HtSwMidIndSta_RHD 0;
BA_ "NetworkRequestHoldingTime" SG_ 1141 Ast_SHVU_HtSwMidIndSta_RHD 5000;
BA_ "Version" SG_ 1141 Ast_SHVU_HtSwMidIndSta_RHD "19.01.04";
BA_ "Description" SG_ 1141 Ast_SHVU_HtSwLowIndSta_RHD "µ¿½Â¼® ½ÃÆ® ¿­¼± ½ºÀ§Ä¡ Low Indicator Á¤º¸(RHD)";
BA_ "GenSigSendType" SG_ 1141 Ast_SHVU_HtSwLowIndSta_RHD 4;
BA_ "UserSigValidity" SG_ 1141 Ast_SHVU_HtSwLowIndSta_RHD 3;
BA_REL_ "GenSigTimeoutTime" BU_SG_REL_ FCS SG_ 1141 Ast_SHVU_HtSwLowIndSta_RHD 1500;
BA_REL_ "GenSigTimeoutTime" BU_SG_REL_ CGW_CCU SG_ 1141 Ast_SHVU_HtSwLowIndSta_RHD 1500;
BA_ "NetworkRequest" SG_ 1141 Ast_SHVU_HtSwLowIndSta_RHD 0;
BA_ "NetworkRequestHoldingTime" SG_ 1141 Ast_SHVU_HtSwLowIndSta_RHD 5000;
BA_ "Version" SG_ 1141 Ast_SHVU_HtSwLowIndSta_RHD "19.01.04";
BA_ "Description" SG_ 1141 Ast_SHVU_VntSwHiIndSta_RHD "µ¿½Â¼® ½ÃÆ® ÅëÇ³ ½ºÀ§Ä¡ High Indicator Á¤º¸(RHD)";
BA_ "GenSigSendType" SG_ 1141 Ast_SHVU_VntSwHiIndSta_RHD 4;
BA_ "UserSigValidity" SG_ 1141 Ast_SHVU_VntSwHiIndSta_RHD 3;
BA_REL_ "GenSigTimeoutTime" BU_SG_REL_ FCS SG_ 1141 Ast_SHVU_VntSwHiIndSta_RHD 1500;
BA_REL_ "GenSigTimeoutTime" BU_SG_REL_ CGW_CCU SG_ 1141 Ast_SHVU_VntSwHiIndSta_RHD 1500;
BA_ "NetworkRequest" SG_ 1141 Ast_SHVU_VntSwHiIndSta_RHD 0;
BA_ "NetworkRequestHoldingTime" SG_ 1141 Ast_SHVU_VntSwHiIndSta_RHD 5000;
BA_ "Version" SG_ 1141 Ast_SHVU_VntSwHiIndSta_RHD "19.01.04";
BA_ "Description" SG_ 1141 Ast_SHVU_VntSwMidIndSta_RHD "µ¿½Â¼® ½ÃÆ® ÅëÇ³ ½ºÀ§Ä¡ Mid Indicator Á¤º¸(RHD)";
BA_ "GenSigSendType" SG_ 1141 Ast_SHVU_VntSwMidIndSta_RHD 4;
BA_ "UserSigValidity" SG_ 1141 Ast_SHVU_VntSwMidIndSta_RHD 3;
BA_REL_ "GenSigTimeoutTime" BU_SG_REL_ FCS SG_ 1141 Ast_SHVU_VntSwMidIndSta_RHD 1500;
BA_REL_ "GenSigTimeoutTime" BU_SG_REL_ CGW_CCU SG_ 1141 Ast_SHVU_VntSwMidIndSta_RHD 1500;
BA_ "NetworkRequest" SG_ 1141 Ast_SHVU_VntSwMidIndSta_RHD 0;
BA_ "NetworkRequestHoldingTime" SG_ 1141 Ast_SHVU_VntSwMidIndSta_RHD 5000;
BA_ "Version" SG_ 1141 Ast_SHVU_VntSwMidIndSta_RHD "19.01.04";
BA_ "Description" SG_ 1141 Ast_SHVU_VntSwLowIndSta_RHD "µ¿½Â¼® ½ÃÆ® ÅëÇ³ ½ºÀ§Ä¡ Low Indicator Á¤º¸(RHD)";
BA_ "GenSigSendType" SG_ 1141 Ast_SHVU_VntSwLowIndSta_RHD 4;
BA_ "UserSigValidity" SG_ 1141 Ast_SHVU_VntSwLowIndSta_RHD 3;
BA_REL_ "GenSigTimeoutTime" BU_SG_REL_ FCS SG_ 1141 Ast_SHVU_VntSwLowIndSta_RHD 1500;
BA_REL_ "GenSigTimeoutTime" BU_SG_REL_ CGW_CCU SG_ 1141 Ast_SHVU_VntSwLowIndSta_RHD 1500;
BA_ "NetworkRequest" SG_ 1141 Ast_SHVU_VntSwLowIndSta_RHD 0;
BA_ "NetworkRequestHoldingTime" SG_ 1141 Ast_SHVU_VntSwLowIndSta_RHD 5000;
BA_ "Version" SG_ 1141 Ast_SHVU_VntSwLowIndSta_RHD "19.01.04";
BA_ "GenMsgSendType" BO_ 1124 0;
BA_ "Description" SG_ 1124 BCM_Crc15Val "The data area for CRC calculation is based on the data length (DLC) of the message DB.

The CRC shall be calculated over the entire data block (excluding the CRC bytes) including the user data, alive counter and Data ID 

 

- CRC Polynomial (0x1D) , Initial Value : 0x00, XOR value : 0xFF, Data ID Mode : Both, Data ID : Message ID + 0xF800 

- The initial value is for CRC calculation and the message should be sent with the calculated result value. 

The mathematical expression to 8 bit CRC polynomial is given here. G(x) = x8 + x4 + x3 + x2 + 1";
BA_ "GenSigSendType" SG_ 1124 BCM_Crc15Val 4;
BA_ "GenSigStartValue" SG_ 1124 BCM_Crc15Val 255;
BA_ "UserSigValidity" SG_ 1124 BCM_Crc15Val 0;
BA_ "Version" SG_ 1124 BCM_Crc15Val "18.11.08";
BA_ "Description" SG_ 1124 BCM_AlvCnt15Val "For the first transmission request for a data element the counter shall be initialized with 0 and shall be incremented by 1

for every subsequent send request. When the counter reaches the maximum value(0xE), then it shall restart with 0 for the next send request";
BA_ "GenSigSendType" SG_ 1124 BCM_AlvCnt15Val 4;
BA_ "UserSigValidity" SG_ 1124 BCM_AlvCnt15Val 0;
BA_ "Version" SG_ 1124 BCM_AlvCnt15Val "18.11.08";
BA_ "Description" SG_ 1124 Window_DrvrSdWdwActSta "This signal indicates DRV Window Action Status";
BA_ "GenSigSendType" SG_ 1124 Window_DrvrSdWdwActSta 4;
BA_ "GenSigStartValue" SG_ 1124 Window_DrvrSdWdwActSta 15;
BA_ "UserSigValidity" SG_ 1124 Window_DrvrSdWdwActSta 0;
BA_ "NetworkRequest" SG_ 1124 Window_DrvrSdWdwActSta 0;
BA_ "NetworkRequestHoldingTime" SG_ 1124 Window_DrvrSdWdwActSta 5000;
BA_ "Version" SG_ 1124 Window_DrvrSdWdwActSta "18.02.01";
BA_ "Description" SG_ 1124 Window_AsstSdWdwActSta "This signal indicates AST Window Action Status";
BA_ "GenSigSendType" SG_ 1124 Window_AsstSdWdwActSta 4;
BA_ "GenSigStartValue" SG_ 1124 Window_AsstSdWdwActSta 15;
BA_ "UserSigValidity" SG_ 1124 Window_AsstSdWdwActSta 0;
BA_ "NetworkRequest" SG_ 1124 Window_AsstSdWdwActSta 0;
BA_ "NetworkRequestHoldingTime" SG_ 1124 Window_AsstSdWdwActSta 5000;
BA_ "Version" SG_ 1124 Window_AsstSdWdwActSta "18.02.01";
BA_ "Description" SG_ 1124 Window_RrLftWdwActSta "This signal indicates RL Window Action Status";
BA_ "GenSigSendType" SG_ 1124 Window_RrLftWdwActSta 4;
BA_ "GenSigStartValue" SG_ 1124 Window_RrLftWdwActSta 15;
BA_ "UserSigValidity" SG_ 1124 Window_RrLftWdwActSta 0;
BA_ "NetworkRequest" SG_ 1124 Window_RrLftWdwActSta 0;
BA_ "NetworkRequestHoldingTime" SG_ 1124 Window_RrLftWdwActSta 5000;
BA_ "Version" SG_ 1124 Window_RrLftWdwActSta "18.02.01";
BA_ "Description" SG_ 1124 Window_RrRtWdwActSta "This signal indicates RR Window Action Status";
BA_ "GenSigSendType" SG_ 1124 Window_RrRtWdwActSta 4;
BA_ "GenSigStartValue" SG_ 1124 Window_RrRtWdwActSta 15;
BA_ "UserSigValidity" SG_ 1124 Window_RrRtWdwActSta 0;
BA_ "NetworkRequest" SG_ 1124 Window_RrRtWdwActSta 0;
BA_ "NetworkRequestHoldingTime" SG_ 1124 Window_RrRtWdwActSta 5000;
BA_ "Version" SG_ 1124 Window_RrRtWdwActSta "18.02.01";
BA_ "Description" SG_ 1124 Window_DrvrSdWdwDetailOpnSta "This signal indicates DRV Window Open/Close Detail Status";
BA_ "GenSigSendType" SG_ 1124 Window_DrvrSdWdwDetailOpnSta 4;
BA_ "GenSigStartValue" SG_ 1124 Window_DrvrSdWdwDetailOpnSta 7;
BA_ "UserSigValidity" SG_ 1124 Window_DrvrSdWdwDetailOpnSta 0;
BA_ "NetworkRequest" SG_ 1124 Window_DrvrSdWdwDetailOpnSta 0;
BA_ "NetworkRequestHoldingTime" SG_ 1124 Window_DrvrSdWdwDetailOpnSta 5000;
BA_ "Version" SG_ 1124 Window_DrvrSdWdwDetailOpnSta "18.02.01";
BA_ "Description" SG_ 1124 Window_AsstSdWdwDetailOpnSta "This signal indicates AST Window Open/Close Detail Status";
BA_ "GenSigSendType" SG_ 1124 Window_AsstSdWdwDetailOpnSta 4;
BA_ "GenSigStartValue" SG_ 1124 Window_AsstSdWdwDetailOpnSta 7;
BA_ "UserSigValidity" SG_ 1124 Window_AsstSdWdwDetailOpnSta 0;
BA_ "NetworkRequest" SG_ 1124 Window_AsstSdWdwDetailOpnSta 0;
BA_ "NetworkRequestHoldingTime" SG_ 1124 Window_AsstSdWdwDetailOpnSta 5000;
BA_ "Version" SG_ 1124 Window_AsstSdWdwDetailOpnSta "18.02.01";
BA_ "Description" SG_ 1124 Window_DrvrSdWdwErrAntPinch "The DRV Window state whether Calibrated or not";
BA_ "GenSigSendType" SG_ 1124 Window_DrvrSdWdwErrAntPinch 4;
BA_ "GenSigStartValue" SG_ 1124 Window_DrvrSdWdwErrAntPinch 1;
BA_ "UserSigValidity" SG_ 1124 Window_DrvrSdWdwErrAntPinch 0;
BA_ "NetworkRequest" SG_ 1124 Window_DrvrSdWdwErrAntPinch 0;
BA_ "NetworkRequestHoldingTime" SG_ 1124 Window_DrvrSdWdwErrAntPinch 5000;
BA_ "Version" SG_ 1124 Window_DrvrSdWdwErrAntPinch "18.02.01";
BA_ "Description" SG_ 1124 Window_RrLftWdwDetailOpnSta "This signal indicates RL Window Open/Close Detail Status";
BA_ "GenSigSendType" SG_ 1124 Window_RrLftWdwDetailOpnSta 4;
BA_ "GenSigStartValue" SG_ 1124 Window_RrLftWdwDetailOpnSta 7;
BA_ "UserSigValidity" SG_ 1124 Window_RrLftWdwDetailOpnSta 0;
BA_ "NetworkRequest" SG_ 1124 Window_RrLftWdwDetailOpnSta 0;
BA_ "NetworkRequestHoldingTime" SG_ 1124 Window_RrLftWdwDetailOpnSta 5000;
BA_ "Version" SG_ 1124 Window_RrLftWdwDetailOpnSta "18.02.01";
BA_ "Description" SG_ 1124 Window_RrRtWdwDetailOpnSta "This signal indicates RR Window Open/Close Detail Status";
BA_ "GenSigSendType" SG_ 1124 Window_RrRtWdwDetailOpnSta 4;
BA_ "GenSigStartValue" SG_ 1124 Window_RrRtWdwDetailOpnSta 7;
BA_ "UserSigValidity" SG_ 1124 Window_RrRtWdwDetailOpnSta 0;
BA_ "NetworkRequest" SG_ 1124 Window_RrRtWdwDetailOpnSta 0;
BA_ "NetworkRequestHoldingTime" SG_ 1124 Window_RrRtWdwDetailOpnSta 5000;
BA_ "Version" SG_ 1124 Window_RrRtWdwDetailOpnSta "18.02.01";
BA_ "Description" SG_ 1124 Window_AsstSdWdwErrAntPinch "The AST Window state whether Calibrated or not";
BA_ "GenSigSendType" SG_ 1124 Window_AsstSdWdwErrAntPinch 4;
BA_ "GenSigStartValue" SG_ 1124 Window_AsstSdWdwErrAntPinch 1;
BA_ "UserSigValidity" SG_ 1124 Window_AsstSdWdwErrAntPinch 0;
BA_ "NetworkRequest" SG_ 1124 Window_AsstSdWdwErrAntPinch 0;
BA_ "NetworkRequestHoldingTime" SG_ 1124 Window_AsstSdWdwErrAntPinch 5000;
BA_ "Version" SG_ 1124 Window_AsstSdWdwErrAntPinch "18.02.01";
BA_ "Description" SG_ 1124 Window_RrLftWdwErrAntPinch "The RL Window state whether Calibrated or not";
BA_ "GenSigSendType" SG_ 1124 Window_RrLftWdwErrAntPinch 4;
BA_ "GenSigStartValue" SG_ 1124 Window_RrLftWdwErrAntPinch 1;
BA_ "UserSigValidity" SG_ 1124 Window_RrLftWdwErrAntPinch 0;
BA_ "NetworkRequest" SG_ 1124 Window_RrLftWdwErrAntPinch 0;
BA_ "NetworkRequestHoldingTime" SG_ 1124 Window_RrLftWdwErrAntPinch 5000;
BA_ "Version" SG_ 1124 Window_RrLftWdwErrAntPinch "18.02.01";
BA_ "Description" SG_ 1124 Window_RrRtWdwErrAntPinch "The RR Window state whether Calibrated or not";
BA_ "GenSigSendType" SG_ 1124 Window_RrRtWdwErrAntPinch 4;
BA_ "GenSigStartValue" SG_ 1124 Window_RrRtWdwErrAntPinch 1;
BA_ "UserSigValidity" SG_ 1124 Window_RrRtWdwErrAntPinch 0;
BA_ "NetworkRequest" SG_ 1124 Window_RrRtWdwErrAntPinch 0;
BA_ "NetworkRequestHoldingTime" SG_ 1124 Window_RrRtWdwErrAntPinch 5000;
BA_ "Version" SG_ 1124 Window_RrRtWdwErrAntPinch "18.02.01";
BA_ "Description" SG_ 1124 SunRoof_RrBlindPosSta "This signal indicates Rear Sunroof Blind Open/Close Status";
BA_ "GenSigSendType" SG_ 1124 SunRoof_RrBlindPosSta 4;
BA_ "GenSigStartValue" SG_ 1124 SunRoof_RrBlindPosSta 15;
BA_ "UserSigValidity" SG_ 1124 SunRoof_RrBlindPosSta 0;
BA_REL_ "GenSigTimeoutTime" BU_SG_REL_ ATS SG_ 1124 SunRoof_RrBlindPosSta 1500;
BA_ "Version" SG_ 1124 SunRoof_RrBlindPosSta "20.01.01";
BA_ "GenMsgSendType" BO_ 1130 0;
BA_ "Description" SG_ 1130 DLBCU_LumbarUpDis "This signal is used to display the seat movement to AVN";
BA_ "GenSigSendType" SG_ 1130 DLBCU_LumbarUpDis 4;
BA_ "UserSigValidity" SG_ 1130 DLBCU_LumbarUpDis 1;
BA_REL_ "GenSigTimeoutTime" BU_SG_REL_ CGW_CCU SG_ 1130 DLBCU_LumbarUpDis 1500;
BA_ "NetworkRequest" SG_ 1130 DLBCU_LumbarUpDis 0;
BA_ "NetworkRequestHoldingTime" SG_ 1130 DLBCU_LumbarUpDis 5000;
BA_ "Version" SG_ 1130 DLBCU_LumbarUpDis "18.03.07";
BA_ "Description" SG_ 1130 DLBCU_LumbarMidDis "This signal is used to display the seat movement to AVN";
BA_ "GenSigSendType" SG_ 1130 DLBCU_LumbarMidDis 4;
BA_ "UserSigValidity" SG_ 1130 DLBCU_LumbarMidDis 1;
BA_REL_ "GenSigTimeoutTime" BU_SG_REL_ CGW_CCU SG_ 1130 DLBCU_LumbarMidDis 1500;
BA_ "NetworkRequest" SG_ 1130 DLBCU_LumbarMidDis 0;
BA_ "NetworkRequestHoldingTime" SG_ 1130 DLBCU_LumbarMidDis 5000;
BA_ "Version" SG_ 1130 DLBCU_LumbarMidDis "18.03.07";
BA_ "Description" SG_ 1130 DLBCU_LumbarLowDis "This signal is used to display the seat movement to AVN";
BA_ "GenSigSendType" SG_ 1130 DLBCU_LumbarLowDis 4;
BA_ "UserSigValidity" SG_ 1130 DLBCU_LumbarLowDis 1;
BA_REL_ "GenSigTimeoutTime" BU_SG_REL_ CGW_CCU SG_ 1130 DLBCU_LumbarLowDis 1500;
BA_ "NetworkRequest" SG_ 1130 DLBCU_LumbarLowDis 0;
BA_ "NetworkRequestHoldingTime" SG_ 1130 DLBCU_LumbarLowDis 5000;
BA_ "Version" SG_ 1130 DLBCU_LumbarLowDis "18.03.07";
BA_ "Description" SG_ 1130 DLBCU_LumbarDefDis "This signal is used to display the seat movement to AVN";
BA_ "GenSigSendType" SG_ 1130 DLBCU_LumbarDefDis 4;
BA_ "UserSigValidity" SG_ 1130 DLBCU_LumbarDefDis 1;
BA_REL_ "GenSigTimeoutTime" BU_SG_REL_ CGW_CCU SG_ 1130 DLBCU_LumbarDefDis 1500;
BA_ "NetworkRequest" SG_ 1130 DLBCU_LumbarDefDis 0;
BA_ "NetworkRequestHoldingTime" SG_ 1130 DLBCU_LumbarDefDis 5000;
BA_ "Version" SG_ 1130 DLBCU_LumbarDefDis "18.03.07";
BA_ "GenMsgSendType" BO_ 1131 0;
BA_ "Description" SG_ 1131 DLBCU_BolsterInfDis "This signal is used to display the seat movement to AVN";
BA_ "GenSigSendType" SG_ 1131 DLBCU_BolsterInfDis 4;
BA_ "UserSigValidity" SG_ 1131 DLBCU_BolsterInfDis 1;
BA_REL_ "GenSigTimeoutTime" BU_SG_REL_ CGW_CCU SG_ 1131 DLBCU_BolsterInfDis 1500;
BA_ "NetworkRequest" SG_ 1131 DLBCU_BolsterInfDis 0;
BA_ "NetworkRequestHoldingTime" SG_ 1131 DLBCU_BolsterInfDis 5000;
BA_ "Version" SG_ 1131 DLBCU_BolsterInfDis "18.03.07";
BA_ "Description" SG_ 1131 DLBCU_BolsterDefDis "This signal is used to display the seat movement to AVN";
BA_ "GenSigSendType" SG_ 1131 DLBCU_BolsterDefDis 4;
BA_ "UserSigValidity" SG_ 1131 DLBCU_BolsterDefDis 1;
BA_REL_ "GenSigTimeoutTime" BU_SG_REL_ CGW_CCU SG_ 1131 DLBCU_BolsterDefDis 1500;
BA_ "NetworkRequest" SG_ 1131 DLBCU_BolsterDefDis 0;
BA_ "NetworkRequestHoldingTime" SG_ 1131 DLBCU_BolsterDefDis 5000;
BA_ "Version" SG_ 1131 DLBCU_BolsterDefDis "18.03.07";
BA_ "GenMsgSendType" BO_ 1127 0;
BA_ "Description" SG_ 1127 DPSS_Crc1Val "The data area for CRC calculation is based on the data length (DLC) of the message DB.

The CRC shall be calculated over the entire data block (excluding the CRC bytes) including the user data, alive counter and Data ID 

 

- CRC Polynomial (0x1D) , Initial Value : 0x00, XOR value : 0xFF, Data ID Mode : Both, Data ID : Message ID + 0xF800 

- The initial value is for CRC calculation and the message should be sent with the calculated result value. 

The mathematical expression to 8 bit CRC polynomial is given here. G(x) = x8 + x4 + x3 + x2 + 1";
BA_ "GenSigSendType" SG_ 1127 DPSS_Crc1Val 4;
BA_ "UserSigValidity" SG_ 1127 DPSS_Crc1Val 0;
BA_ "Version" SG_ 1127 DPSS_Crc1Val "21.09.03";
BA_ "Description" SG_ 1127 DPSS_AlvCnt1Val "For the first transmission request for a data element the counter shall be initialized with 0 and shall be incremented by 1

for every subsequent send request. When the counter reaches the maximum value(0xE), then it shall restart with 0 for the next send request";
BA_ "GenSigSendType" SG_ 1127 DPSS_AlvCnt1Val 4;
BA_ "UserSigValidity" SG_ 1127 DPSS_AlvCnt1Val 0;
BA_ "Version" SG_ 1127 DPSS_AlvCnt1Val "21.09.03";
BA_ "Description" SG_ 1127 DPSS_StExtFwdMvBtn "¿îÀü¼® Äí¼Ç ÀÍ½ºÅÙ¼Ç Æ÷¿öµå ¹öÆ°";
BA_ "GenSigSendType" SG_ 1127 DPSS_StExtFwdMvBtn 4;
BA_ "UserSigValidity" SG_ 1127 DPSS_StExtFwdMvBtn 0;
BA_ "NetworkRequest" SG_ 1127 DPSS_StExtFwdMvBtn 0;
BA_ "NetworkRequestHoldingTime" SG_ 1127 DPSS_StExtFwdMvBtn 5000;
BA_ "Version" SG_ 1127 DPSS_StExtFwdMvBtn "20.03.01";
BA_ "Description" SG_ 1127 DPSS_StExtBwdMvBtn "¿îÀü¼® Äí¼Ç ÀÍ½ºÅÙ¼Ç ¹é¿öµå ¹öÆ°";
BA_ "GenSigSendType" SG_ 1127 DPSS_StExtBwdMvBtn 4;
BA_ "UserSigValidity" SG_ 1127 DPSS_StExtBwdMvBtn 0;
BA_ "NetworkRequest" SG_ 1127 DPSS_StExtBwdMvBtn 0;
BA_ "NetworkRequestHoldingTime" SG_ 1127 DPSS_StExtBwdMvBtn 5000;
BA_ "Version" SG_ 1127 DPSS_StExtBwdMvBtn "20.03.01";
BA_ "Description" SG_ 1127 DPSS_StSldFwdMvBtn "¿îÀü¼® ½½¶óÀÌµå Æ÷¿öµå ¹öÆ°";
BA_ "GenSigSendType" SG_ 1127 DPSS_StSldFwdMvBtn 4;
BA_ "UserSigValidity" SG_ 1127 DPSS_StSldFwdMvBtn 0;
BA_ "NetworkRequest" SG_ 1127 DPSS_StSldFwdMvBtn 0;
BA_ "NetworkRequestHoldingTime" SG_ 1127 DPSS_StSldFwdMvBtn 5000;
BA_ "Version" SG_ 1127 DPSS_StSldFwdMvBtn "20.03.01";
BA_ "Description" SG_ 1127 DPSS_StSldBwdMvBtn "¿îÀü¼® ½½¶óÀÌµå ¹é¿öµå ¹öÆ°";
BA_ "GenSigSendType" SG_ 1127 DPSS_StSldBwdMvBtn 4;
BA_ "UserSigValidity" SG_ 1127 DPSS_StSldBwdMvBtn 0;
BA_ "NetworkRequest" SG_ 1127 DPSS_StSldBwdMvBtn 0;
BA_ "NetworkRequestHoldingTime" SG_ 1127 DPSS_StSldBwdMvBtn 5000;
BA_ "Version" SG_ 1127 DPSS_StSldBwdMvBtn "20.03.01";
BA_ "Description" SG_ 1127 DPSS_StRclFwdMvBtn "¿îÀü¼® ¸®Å¬¶óÀÌ³Ê Æ÷¿öµå ¹öÆ°";
BA_ "GenSigSendType" SG_ 1127 DPSS_StRclFwdMvBtn 4;
BA_ "UserSigValidity" SG_ 1127 DPSS_StRclFwdMvBtn 0;
BA_ "NetworkRequest" SG_ 1127 DPSS_StRclFwdMvBtn 0;
BA_ "NetworkRequestHoldingTime" SG_ 1127 DPSS_StRclFwdMvBtn 5000;
BA_ "Version" SG_ 1127 DPSS_StRclFwdMvBtn "20.03.01";
BA_ "Description" SG_ 1127 DPSS_StRclBwdMvBtn "¿îÀü¼® ¸®Å¬¶óÀÌ³Ê ¹é¿öµå ¹öÆ°";
BA_ "GenSigSendType" SG_ 1127 DPSS_StRclBwdMvBtn 4;
BA_ "UserSigValidity" SG_ 1127 DPSS_StRclBwdMvBtn 0;
BA_ "NetworkRequest" SG_ 1127 DPSS_StRclBwdMvBtn 0;
BA_ "NetworkRequestHoldingTime" SG_ 1127 DPSS_StRclBwdMvBtn 5000;
BA_ "Version" SG_ 1127 DPSS_StRclBwdMvBtn "20.03.01";
BA_ "Description" SG_ 1127 DPSS_StHgtUpMvBtn "¿îÀü¼® ÇÏÀÌÆ® ¾÷ ¹öÆ°";
BA_ "GenSigSendType" SG_ 1127 DPSS_StHgtUpMvBtn 4;
BA_ "UserSigValidity" SG_ 1127 DPSS_StHgtUpMvBtn 0;
BA_ "NetworkRequest" SG_ 1127 DPSS_StHgtUpMvBtn 0;
BA_ "NetworkRequestHoldingTime" SG_ 1127 DPSS_StHgtUpMvBtn 5000;
BA_ "Version" SG_ 1127 DPSS_StHgtUpMvBtn "20.03.01";
BA_ "Description" SG_ 1127 DPSS_StHgtDnMvBtn "¿îÀü¼® ÇÏÀÌÆ® ´Ù¿î ¹öÆ°";
BA_ "GenSigSendType" SG_ 1127 DPSS_StHgtDnMvBtn 4;
BA_ "UserSigValidity" SG_ 1127 DPSS_StHgtDnMvBtn 0;
BA_ "NetworkRequest" SG_ 1127 DPSS_StHgtDnMvBtn 0;
BA_ "NetworkRequestHoldingTime" SG_ 1127 DPSS_StHgtDnMvBtn 5000;
BA_ "Version" SG_ 1127 DPSS_StHgtDnMvBtn "20.03.01";
BA_ "Description" SG_ 1127 DPSS_StTltUpMvBtn "¿îÀü¼® Æ¿Æ® ¾÷ ¹öÆ°";
BA_ "GenSigSendType" SG_ 1127 DPSS_StTltUpMvBtn 4;
BA_ "UserSigValidity" SG_ 1127 DPSS_StTltUpMvBtn 0;
BA_ "NetworkRequest" SG_ 1127 DPSS_StTltUpMvBtn 0;
BA_ "NetworkRequestHoldingTime" SG_ 1127 DPSS_StTltUpMvBtn 5000;
BA_ "Version" SG_ 1127 DPSS_StTltUpMvBtn "20.03.01";
BA_ "Description" SG_ 1127 DPSS_StTltDnMvBtn "¿îÀü¼® Æ¿Æ® ´Ù¿î ¹öÆ°";
BA_ "GenSigSendType" SG_ 1127 DPSS_StTltDnMvBtn 4;
BA_ "UserSigValidity" SG_ 1127 DPSS_StTltDnMvBtn 0;
BA_ "NetworkRequest" SG_ 1127 DPSS_StTltDnMvBtn 0;
BA_ "NetworkRequestHoldingTime" SG_ 1127 DPSS_StTltDnMvBtn 5000;
BA_ "Version" SG_ 1127 DPSS_StTltDnMvBtn "20.03.01";
BA_ "Description" SG_ 1127 DPSS_StHRestUpMvBtn "¿îÀü¼® Çìµå·¹½ºÆ® UP ¹öÆ°";
BA_ "GenSigSendType" SG_ 1127 DPSS_StHRestUpMvBtn 4;
BA_ "UserSigValidity" SG_ 1127 DPSS_StHRestUpMvBtn 0;
BA_ "NetworkRequest" SG_ 1127 DPSS_StHRestUpMvBtn 0;
BA_ "NetworkRequestHoldingTime" SG_ 1127 DPSS_StHRestUpMvBtn 5000;
BA_ "Version" SG_ 1127 DPSS_StHRestUpMvBtn "20.03.01";
BA_ "Description" SG_ 1127 DPSS_StHRestDnMvBtn "¿îÀü¼® Çìµå·¹½ºÆ® DOWN ¹öÆ°";
BA_ "GenSigSendType" SG_ 1127 DPSS_StHRestDnMvBtn 4;
BA_ "UserSigValidity" SG_ 1127 DPSS_StHRestDnMvBtn 0;
BA_ "NetworkRequest" SG_ 1127 DPSS_StHRestDnMvBtn 0;
BA_ "NetworkRequestHoldingTime" SG_ 1127 DPSS_StHRestDnMvBtn 5000;
BA_ "Version" SG_ 1127 DPSS_StHRestDnMvBtn "20.03.01";
BA_ "Description" SG_ 1127 DPSS_StHRestFwdMvBtn "¿îÀü¼® Çìµå·¹½ºÆ® FWD ¹öÆ°";
BA_ "GenSigSendType" SG_ 1127 DPSS_StHRestFwdMvBtn 4;
BA_ "UserSigValidity" SG_ 1127 DPSS_StHRestFwdMvBtn 0;
BA_ "NetworkRequest" SG_ 1127 DPSS_StHRestFwdMvBtn 0;
BA_ "NetworkRequestHoldingTime" SG_ 1127 DPSS_StHRestFwdMvBtn 5000;
BA_ "Version" SG_ 1127 DPSS_StHRestFwdMvBtn "20.03.01";
BA_ "Description" SG_ 1127 DPSS_StHRestBwdMvBtn "¿îÀü¼® Çìµå·¹½ºÆ® BWD ¹öÆ°";
BA_ "GenSigSendType" SG_ 1127 DPSS_StHRestBwdMvBtn 4;
BA_ "UserSigValidity" SG_ 1127 DPSS_StHRestBwdMvBtn 0;
BA_ "NetworkRequest" SG_ 1127 DPSS_StHRestBwdMvBtn 0;
BA_ "NetworkRequestHoldingTime" SG_ 1127 DPSS_StHRestBwdMvBtn 5000;
BA_ "Version" SG_ 1127 DPSS_StHRestBwdMvBtn "20.03.01";
BA_ "Description" SG_ 1127 DPSS_StLegUpMvBtn "¿îÀü¼® ·¹±×·¹½ºÆ® ¾÷ ¹öÆ°";
BA_ "GenSigSendType" SG_ 1127 DPSS_StLegUpMvBtn 4;
BA_ "UserSigValidity" SG_ 1127 DPSS_StLegUpMvBtn 0;
BA_ "NetworkRequest" SG_ 1127 DPSS_StLegUpMvBtn 0;
BA_ "NetworkRequestHoldingTime" SG_ 1127 DPSS_StLegUpMvBtn 5000;
BA_ "Version" SG_ 1127 DPSS_StLegUpMvBtn "20.03.01";
BA_ "Description" SG_ 1127 DPSS_StLegDnMvBtn "¿îÀü¼® ·¹±×·¹½ºÆ® ´Ù¿î ¹öÆ°";
BA_ "GenSigSendType" SG_ 1127 DPSS_StLegDnMvBtn 4;
BA_ "UserSigValidity" SG_ 1127 DPSS_StLegDnMvBtn 0;
BA_ "NetworkRequest" SG_ 1127 DPSS_StLegDnMvBtn 0;
BA_ "NetworkRequestHoldingTime" SG_ 1127 DPSS_StLegDnMvBtn 5000;
BA_ "Version" SG_ 1127 DPSS_StLegDnMvBtn "20.03.01";
BA_ "Description" SG_ 1127 DPSS_StRlxModeBtn "¿îÀü¼® ¸±·º½º ¸ðµå ¹öÆ°";
BA_ "GenSigSendType" SG_ 1127 DPSS_StRlxModeBtn 4;
BA_ "UserSigValidity" SG_ 1127 DPSS_StRlxModeBtn 0;
BA_ "NetworkRequest" SG_ 1127 DPSS_StRlxModeBtn 0;
BA_ "NetworkRequestHoldingTime" SG_ 1127 DPSS_StRlxModeBtn 5000;
BA_ "Version" SG_ 1127 DPSS_StRlxModeBtn "20.03.01";
BA_ "Description" SG_ 1127 DPSS_StRlxReturnBtn "¿îÀü¼® ¸±·º½º ¸®ÅÏ ¹öÆ°";
BA_ "GenSigSendType" SG_ 1127 DPSS_StRlxReturnBtn 4;
BA_ "UserSigValidity" SG_ 1127 DPSS_StRlxReturnBtn 0;
BA_ "NetworkRequest" SG_ 1127 DPSS_StRlxReturnBtn 0;
BA_ "NetworkRequestHoldingTime" SG_ 1127 DPSS_StRlxReturnBtn 5000;
BA_ "Version" SG_ 1127 DPSS_StRlxReturnBtn "20.03.01";
BA_ "Description" SG_ 1127 DPSS_StRlxTltUpMvBtn "¿îÀü¼® ¸±·º½º Æ¿Æ® ¾÷ ¹öÆ°";
BA_ "GenSigSendType" SG_ 1127 DPSS_StRlxTltUpMvBtn 4;
BA_ "UserSigValidity" SG_ 1127 DPSS_StRlxTltUpMvBtn 0;
BA_ "NetworkRequest" SG_ 1127 DPSS_StRlxTltUpMvBtn 0;
BA_ "NetworkRequestHoldingTime" SG_ 1127 DPSS_StRlxTltUpMvBtn 5000;
BA_ "Version" SG_ 1127 DPSS_StRlxTltUpMvBtn "21.11.01";
BA_ "Description" SG_ 1127 DPSS_StRlxTltDnMvBtn "¿îÀü¼® ¸±·º½º Æ¿Æ® ´Ù¿î ¹öÆ°";
BA_ "GenSigSendType" SG_ 1127 DPSS_StRlxTltDnMvBtn 4;
BA_ "UserSigValidity" SG_ 1127 DPSS_StRlxTltDnMvBtn 0;
BA_ "NetworkRequest" SG_ 1127 DPSS_StRlxTltDnMvBtn 0;
BA_ "NetworkRequestHoldingTime" SG_ 1127 DPSS_StRlxTltDnMvBtn 5000;
BA_ "Version" SG_ 1127 DPSS_StRlxTltDnMvBtn "21.11.01";
BA_ "GenMsgSendType" BO_ 1128 0;
BA_ "Description" SG_ 1128 DPSS_Crc2Val "The data area for CRC calculation is based on the data length (DLC) of the message DB.

The CRC shall be calculated over the entire data block (excluding the CRC bytes) including the user data, alive counter and Data ID 

 

- CRC Polynomial (0x1D) , Initial Value : 0x00, XOR value : 0xFF, Data ID Mode : Both, Data ID : Message ID + 0xF800 

- The initial value is for CRC calculation and the message should be sent with the calculated result value. 

The mathematical expression to 8 bit CRC polynomial is given here. G(x) = x8 + x4 + x3 + x2 + 1";
BA_ "GenSigSendType" SG_ 1128 DPSS_Crc2Val 4;
BA_ "GenSigStartValue" SG_ 1128 DPSS_Crc2Val 255;
BA_ "UserSigValidity" SG_ 1128 DPSS_Crc2Val 0;
BA_REL_ "GenSigTimeoutTime" BU_SG_REL_ DLBCU SG_ 1128 DPSS_Crc2Val 1500;
BA_ "Version" SG_ 1128 DPSS_Crc2Val "19.01.01";
BA_ "Description" SG_ 1128 DPSS_AlvCnt2Val "For the first transmission request for a data element the counter shall be initialized with 0 and shall be incremented by 1

for every subsequent send request. When the counter reaches the maximum value(0xE), then it shall restart with 0 for the next send request";
BA_ "GenSigSendType" SG_ 1128 DPSS_AlvCnt2Val 4;
BA_ "UserSigValidity" SG_ 1128 DPSS_AlvCnt2Val 0;
BA_REL_ "GenSigTimeoutTime" BU_SG_REL_ DLBCU SG_ 1128 DPSS_AlvCnt2Val 1500;
BA_ "Version" SG_ 1128 DPSS_AlvCnt2Val "19.01.01";
BA_ "Description" SG_ 1128 DPSS_LumbarUpSw "¿îÀü¼® ·³¹ö ¾÷ ½ºÀ§Ä¡";
BA_ "GenSigSendType" SG_ 1128 DPSS_LumbarUpSw 4;
BA_ "UserSigValidity" SG_ 1128 DPSS_LumbarUpSw 0;
BA_REL_ "GenSigTimeoutTime" BU_SG_REL_ DLBCU SG_ 1128 DPSS_LumbarUpSw 1500;
BA_ "NetworkRequest" SG_ 1128 DPSS_LumbarUpSw 0;
BA_ "NetworkRequestHoldingTime" SG_ 1128 DPSS_LumbarUpSw 5000;
BA_ "Version" SG_ 1128 DPSS_LumbarUpSw "20.03.01";
BA_ "Description" SG_ 1128 DPSS_LumbarMidSw "¿îÀü¼® ·³¹ö ¹Ìµé ½ºÀ§Ä¡";
BA_ "GenSigSendType" SG_ 1128 DPSS_LumbarMidSw 4;
BA_ "UserSigValidity" SG_ 1128 DPSS_LumbarMidSw 0;
BA_REL_ "GenSigTimeoutTime" BU_SG_REL_ DLBCU SG_ 1128 DPSS_LumbarMidSw 1500;
BA_ "NetworkRequest" SG_ 1128 DPSS_LumbarMidSw 0;
BA_ "NetworkRequestHoldingTime" SG_ 1128 DPSS_LumbarMidSw 5000;
BA_ "Version" SG_ 1128 DPSS_LumbarMidSw "20.03.01";
BA_ "Description" SG_ 1128 DPSS_LumbarLowSw "¿îÀü¼® ·³¹ö ÇÏ´Ü ¹öÆ°";
BA_ "GenSigSendType" SG_ 1128 DPSS_LumbarLowSw 4;
BA_ "UserSigValidity" SG_ 1128 DPSS_LumbarLowSw 0;
BA_REL_ "GenSigTimeoutTime" BU_SG_REL_ DLBCU SG_ 1128 DPSS_LumbarLowSw 1500;
BA_ "NetworkRequest" SG_ 1128 DPSS_LumbarLowSw 0;
BA_ "NetworkRequestHoldingTime" SG_ 1128 DPSS_LumbarLowSw 5000;
BA_ "Version" SG_ 1128 DPSS_LumbarLowSw "20.03.01";
BA_ "Description" SG_ 1128 DPSS_LumbarDefSw "¿îÀü¼® ·³¹ö µðÇÃ·¹ÀÌ¼Ç ¹öÆ°";
BA_ "GenSigSendType" SG_ 1128 DPSS_LumbarDefSw 4;
BA_ "UserSigValidity" SG_ 1128 DPSS_LumbarDefSw 0;
BA_REL_ "GenSigTimeoutTime" BU_SG_REL_ DLBCU SG_ 1128 DPSS_LumbarDefSw 1500;
BA_ "NetworkRequest" SG_ 1128 DPSS_LumbarDefSw 0;
BA_ "NetworkRequestHoldingTime" SG_ 1128 DPSS_LumbarDefSw 5000;
BA_ "Version" SG_ 1128 DPSS_LumbarDefSw "20.03.01";
BA_ "Description" SG_ 1128 DPSS_BolsterInfSw "¿îÀü¼® º¼½ºÅÍ Èí±â ¹öÆ°";
BA_ "GenSigSendType" SG_ 1128 DPSS_BolsterInfSw 4;
BA_ "UserSigValidity" SG_ 1128 DPSS_BolsterInfSw 0;
BA_REL_ "GenSigTimeoutTime" BU_SG_REL_ DLBCU SG_ 1128 DPSS_BolsterInfSw 1500;
BA_ "NetworkRequest" SG_ 1128 DPSS_BolsterInfSw 0;
BA_ "NetworkRequestHoldingTime" SG_ 1128 DPSS_BolsterInfSw 5000;
BA_ "Version" SG_ 1128 DPSS_BolsterInfSw "20.03.01";
BA_ "Description" SG_ 1128 DPSS_BolsterDefSw "¿îÀü¼® º¼½ºÅÍ ¹è±â ¹öÆ°";
BA_ "GenSigSendType" SG_ 1128 DPSS_BolsterDefSw 4;
BA_ "UserSigValidity" SG_ 1128 DPSS_BolsterDefSw 0;
BA_REL_ "GenSigTimeoutTime" BU_SG_REL_ DLBCU SG_ 1128 DPSS_BolsterDefSw 1500;
BA_ "NetworkRequest" SG_ 1128 DPSS_BolsterDefSw 0;
BA_ "NetworkRequestHoldingTime" SG_ 1128 DPSS_BolsterDefSw 5000;
BA_ "Version" SG_ 1128 DPSS_BolsterDefSw "20.03.01";
BA_ "Description" SG_ 1128 DPSS_ActiveSw "¿îÀü¼® Äí¼Ç º¼½ºÅÍ Á¶Àý ½ºÀ§Ä¡";
BA_ "GenSigSendType" SG_ 1128 DPSS_ActiveSw 4;
BA_ "UserSigValidity" SG_ 1128 DPSS_ActiveSw 0;
BA_REL_ "GenSigTimeoutTime" BU_SG_REL_ DLBCU SG_ 1128 DPSS_ActiveSw 1500;
BA_ "NetworkRequest" SG_ 1128 DPSS_ActiveSw 0;
BA_ "NetworkRequestHoldingTime" SG_ 1128 DPSS_ActiveSw 5000;
BA_ "Version" SG_ 1128 DPSS_ActiveSw "20.03.01";
BA_ "Description" SG_ 1128 DPSS_CushInfSw "¿îÀü¼® Äí¼Ç°ø¾ÐÁ¶Àý Èí±â ¹öÆ°";
BA_ "GenSigSendType" SG_ 1128 DPSS_CushInfSw 4;
BA_ "UserSigValidity" SG_ 1128 DPSS_CushInfSw 0;
BA_REL_ "GenSigTimeoutTime" BU_SG_REL_ DLBCU SG_ 1128 DPSS_CushInfSw 1500;
BA_ "NetworkRequest" SG_ 1128 DPSS_CushInfSw 0;
BA_ "NetworkRequestHoldingTime" SG_ 1128 DPSS_CushInfSw 5000;
BA_ "Version" SG_ 1128 DPSS_CushInfSw "20.03.01";
BA_ "Description" SG_ 1128 DPSS_CushDefSw "¿îÀü¼® Äí¼Ç °ø¾Ð Á¶Àý ¹è±â ¹öÆ°";
BA_ "GenSigSendType" SG_ 1128 DPSS_CushDefSw 4;
BA_ "UserSigValidity" SG_ 1128 DPSS_CushDefSw 0;
BA_REL_ "GenSigTimeoutTime" BU_SG_REL_ DLBCU SG_ 1128 DPSS_CushDefSw 1500;
BA_ "NetworkRequest" SG_ 1128 DPSS_CushDefSw 0;
BA_ "NetworkRequestHoldingTime" SG_ 1128 DPSS_CushDefSw 5000;
BA_ "Version" SG_ 1128 DPSS_CushDefSw "20.03.01";
BA_ "GenMsgSendType" BO_ 1129 0;
BA_ "Description" SG_ 1129 DPSS_Crc3Val "The data area for CRC calculation is based on the data length (DLC) of the message DB.

The CRC shall be calculated over the entire data block (excluding the CRC bytes) including the user data, alive counter and Data ID 

 

- CRC Polynomial (0x1D) , Initial Value : 0x00, XOR value : 0xFF, Data ID Mode : Both, Data ID : Message ID + 0xF800 

- The initial value is for CRC calculation and the message should be sent with the calculated result value. 

The mathematical expression to 8 bit CRC polynomial is given here. G(x) = x8 + x4 + x3 + x2 + 1";
BA_ "GenSigSendType" SG_ 1129 DPSS_Crc3Val 4;
BA_ "GenSigStartValue" SG_ 1129 DPSS_Crc3Val 255;
BA_ "UserSigValidity" SG_ 1129 DPSS_Crc3Val 3;
BA_REL_ "GenSigTimeoutTime" BU_SG_REL_ CGW_CCU SG_ 1129 DPSS_Crc3Val 1500;
BA_ "Version" SG_ 1129 DPSS_Crc3Val "19.01.01";
BA_ "Description" SG_ 1129 DPSS_AlvCnt3Val "For the first transmission request for a data element the counter shall be initialized with 0 and shall be incremented by 1

for every subsequent send request. When the counter reaches the maximum value(0xE), then it shall restart with 0 for the next send request";
BA_ "GenSigSendType" SG_ 1129 DPSS_AlvCnt3Val 4;
BA_ "UserSigValidity" SG_ 1129 DPSS_AlvCnt3Val 3;
BA_ "Version" SG_ 1129 DPSS_AlvCnt3Val "19.01.01";
BA_ "Description" SG_ 1129 DPSS_SldTch "ÅÍÄ¡ ½ºÀ§Ä¡ Á¤º¸";
BA_ "GenSigSendType" SG_ 1129 DPSS_SldTch 4;
BA_ "UserSigValidity" SG_ 1129 DPSS_SldTch 3;
BA_REL_ "GenSigTimeoutTime" BU_SG_REL_ CGW_CCU SG_ 1129 DPSS_SldTch 1500;
BA_ "NetworkRequest" SG_ 1129 DPSS_SldTch 0;
BA_ "NetworkRequestHoldingTime" SG_ 1129 DPSS_SldTch 5000;
BA_ "Version" SG_ 1129 DPSS_SldTch "19.01.01";
BA_ "Description" SG_ 1129 DPSS_RclTch "ÅÍÄ¡ ½ºÀ§Ä¡ Á¤º¸";
BA_ "GenSigSendType" SG_ 1129 DPSS_RclTch 4;
BA_ "UserSigValidity" SG_ 1129 DPSS_RclTch 3;
BA_REL_ "GenSigTimeoutTime" BU_SG_REL_ CGW_CCU SG_ 1129 DPSS_RclTch 1500;
BA_ "NetworkRequest" SG_ 1129 DPSS_RclTch 0;
BA_ "NetworkRequestHoldingTime" SG_ 1129 DPSS_RclTch 5000;
BA_ "Version" SG_ 1129 DPSS_RclTch "19.01.01";
BA_ "Description" SG_ 1129 DPSS_ExtTch "ÅÍÄ¡ ½ºÀ§Ä¡ Á¤º¸";
BA_ "GenSigSendType" SG_ 1129 DPSS_ExtTch 4;
BA_ "UserSigValidity" SG_ 1129 DPSS_ExtTch 3;
BA_REL_ "GenSigTimeoutTime" BU_SG_REL_ CGW_CCU SG_ 1129 DPSS_ExtTch 1500;
BA_ "NetworkRequest" SG_ 1129 DPSS_ExtTch 0;
BA_ "NetworkRequestHoldingTime" SG_ 1129 DPSS_ExtTch 5000;
BA_ "Version" SG_ 1129 DPSS_ExtTch "19.01.01";
BA_ "Description" SG_ 1129 DPSS_LmbrTch "ÅÍÄ¡ ½ºÀ§Ä¡ Á¤º¸";
BA_ "GenSigSendType" SG_ 1129 DPSS_LmbrTch 4;
BA_ "UserSigValidity" SG_ 1129 DPSS_LmbrTch 3;
BA_REL_ "GenSigTimeoutTime" BU_SG_REL_ CGW_CCU SG_ 1129 DPSS_LmbrTch 1500;
BA_ "NetworkRequest" SG_ 1129 DPSS_LmbrTch 0;
BA_ "NetworkRequestHoldingTime" SG_ 1129 DPSS_LmbrTch 5000;
BA_ "Version" SG_ 1129 DPSS_LmbrTch "19.01.01";
BA_ "Description" SG_ 1129 DPSS_CushOnOffTch "ÅÍÄ¡ ½ºÀ§Ä¡ Á¤º¸";
BA_ "GenSigSendType" SG_ 1129 DPSS_CushOnOffTch 4;
BA_ "UserSigValidity" SG_ 1129 DPSS_CushOnOffTch 3;
BA_REL_ "GenSigTimeoutTime" BU_SG_REL_ CGW_CCU SG_ 1129 DPSS_CushOnOffTch 1500;
BA_ "NetworkRequest" SG_ 1129 DPSS_CushOnOffTch 0;
BA_ "NetworkRequestHoldingTime" SG_ 1129 DPSS_CushOnOffTch 5000;
BA_ "Version" SG_ 1129 DPSS_CushOnOffTch "19.09.00";
BA_ "Description" SG_ 1129 DPSS_HRestTch "Çìµå·¹½ºÆ® ½ºÀ§Ä¡ ÅÍÄ¡ Á¤º¸";
BA_ "GenSigSendType" SG_ 1129 DPSS_HRestTch 4;
BA_ "UserSigValidity" SG_ 1129 DPSS_HRestTch 3;
BA_REL_ "GenSigTimeoutTime" BU_SG_REL_ CGW_CCU SG_ 1129 DPSS_HRestTch 1500;
BA_ "NetworkRequest" SG_ 1129 DPSS_HRestTch 0;
BA_ "NetworkRequestHoldingTime" SG_ 1129 DPSS_HRestTch 5000;
BA_ "Version" SG_ 1129 DPSS_HRestTch "19.11.09";
BA_ "Description" SG_ 1129 DPSS_RelaxTch "ÅÍÄ¡ ½ºÀ§Ä¡ Á¤º¸";
BA_ "GenSigSendType" SG_ 1129 DPSS_RelaxTch 4;
BA_ "UserSigValidity" SG_ 1129 DPSS_RelaxTch 3;
BA_REL_ "GenSigTimeoutTime" BU_SG_REL_ CGW_CCU SG_ 1129 DPSS_RelaxTch 1500;
BA_ "NetworkRequest" SG_ 1129 DPSS_RelaxTch 0;
BA_ "NetworkRequestHoldingTime" SG_ 1129 DPSS_RelaxTch 5000;
BA_ "Version" SG_ 1129 DPSS_RelaxTch "21.07.05";
BA_ "Description" SG_ 1129 DPSS_ThighTch "¿îÀü¼® Äí¼Ç ¿¡¾î¼¿ ½ºÀ§Ä¡ ³ëºê ÅÍÄ¡ Á¤º¸";
BA_ "GenSigSendType" SG_ 1129 DPSS_ThighTch 4;
BA_ "UserSigValidity" SG_ 1129 DPSS_ThighTch 3;
BA_REL_ "GenSigTimeoutTime" BU_SG_REL_ CGW_CCU SG_ 1129 DPSS_ThighTch 1500;
BA_ "NetworkRequest" SG_ 1129 DPSS_ThighTch 0;
BA_ "NetworkRequestHoldingTime" SG_ 1129 DPSS_ThighTch 5000;
BA_ "Version" SG_ 1129 DPSS_ThighTch "22.02.02";
BA_ "Description" SG_ 1129 DPSS_ExtThighTch "¿îÀü¼® Äí¼Ç ÀÍ½ºÅÙ¼Ç&¿¡¾î¼¿ ½ºÀ§Ä¡ ³ëºê ÅÍÄ¡";
BA_ "GenSigSendType" SG_ 1129 DPSS_ExtThighTch 4;
BA_ "UserSigValidity" SG_ 1129 DPSS_ExtThighTch 3;
BA_REL_ "GenSigTimeoutTime" BU_SG_REL_ CGW_CCU SG_ 1129 DPSS_ExtThighTch 1500;
BA_ "NetworkRequest" SG_ 1129 DPSS_ExtThighTch 0;
BA_ "NetworkRequestHoldingTime" SG_ 1129 DPSS_ExtThighTch 5000;
BA_ "Version" SG_ 1129 DPSS_ExtThighTch "22.02.02";
BA_ "Description" SG_ 1129 DPSS_LmbrBolsterTch "¿îÀü¼® ·³¹ö, º¼½ºÅÍ ³ëºê ÅÍÄ¡ Á¤º¸";
BA_ "GenSigSendType" SG_ 1129 DPSS_LmbrBolsterTch 4;
BA_ "UserSigValidity" SG_ 1129 DPSS_LmbrBolsterTch 3;
BA_REL_ "GenSigTimeoutTime" BU_SG_REL_ CGW_CCU SG_ 1129 DPSS_LmbrBolsterTch 1500;
BA_ "NetworkRequest" SG_ 1129 DPSS_LmbrBolsterTch 0;
BA_ "NetworkRequestHoldingTime" SG_ 1129 DPSS_LmbrBolsterTch 5000;
BA_ "Version" SG_ 1129 DPSS_LmbrBolsterTch "22.02.02";
BA_ "GenMsgSendType" BO_ 614 0;
BA_ "Description" SG_ 614 EMCU_Crc1Val "The data area for CRC calculation is based on the data length (DLC) of the message DB.

The CRC shall be calculated over the entire data block (excluding the CRC bytes) including the user data, alive counter and Data ID 

 

- CRC Polynomial (0x1D) , Initial Value : 0x00, XOR value : 0xFF, Data ID Mode : Both, Data ID : Message ID + 0xF800 

- The initial value is for CRC calculation and the message should be sent with the calculated result value. 

The mathematical expression to 8 bit CRC polynomial is given here. G(x) = x8 + x4 + x3 + x2 + 1";
BA_ "GenSigSendType" SG_ 614 EMCU_Crc1Val 4;
BA_ "UserSigValidity" SG_ 614 EMCU_Crc1Val 3;
BA_ "Version" SG_ 614 EMCU_Crc1Val "21.09.03";
BA_ "Description" SG_ 614 EMCU_AlvCnt1Val "For the first transmission request for a data element the counter shall be initialized with 0 and shall be incremented by 1

for every subsequent send request. When the counter reaches the maximum value(0xE), then it shall restart with 0 for the next send request";
BA_ "GenSigSendType" SG_ 614 EMCU_AlvCnt1Val 4;
BA_ "UserSigValidity" SG_ 614 EMCU_AlvCnt1Val 3;
BA_ "Version" SG_ 614 EMCU_AlvCnt1Val "21.09.03";
BA_ "Description" SG_ 614 EMCU_LHActSta "Left Engine Mount ON/OFF Status";
BA_ "GenSigSendType" SG_ 614 EMCU_LHActSta 4;
BA_ "UserSigValidity" SG_ 614 EMCU_LHActSta 3;
BA_ "Version" SG_ 614 EMCU_LHActSta "21.10.03";
BA_ "Description" SG_ 614 EMCU_RHActSta "Right Engine Mount ON/OFF Status";
BA_ "GenSigSendType" SG_ 614 EMCU_RHActSta 4;
BA_ "UserSigValidity" SG_ 614 EMCU_RHActSta 3;
BA_ "Version" SG_ 614 EMCU_RHActSta "21.10.03";
BA_ "Description" SG_ 614 EMCU_DeltaSpdVal "Current Delta Speed Vaule in control logic";
BA_ "GenSigSendType" SG_ 614 EMCU_DeltaSpdVal 4;
BA_ "UserSigValidity" SG_ 614 EMCU_DeltaSpdVal 3;
BA_ "Version" SG_ 614 EMCU_DeltaSpdVal "21.10.03";
BA_ "Description" SG_ 614 EMCU_System_Sta "Engine Mount Control Unit Status";
BA_ "GenSigSendType" SG_ 614 EMCU_System_Sta 4;
BA_ "UserSigValidity" SG_ 614 EMCU_System_Sta 3;
BA_ "Version" SG_ 614 EMCU_System_Sta "21.10.03";
BA_ "GenMsgSendType" BO_ 2214658049 0;
BA_ "GenMsgCycleTime" BO_ 2214658049 50;
BA_ "GenMsgCycleTimeFast" BO_ 2214658049 0;
BA_ "GenMsgNrOfRepetition" BO_ 2214658049 0;
BA_ "VFrameFormat" BO_ 2214658049 1;
BA_ "Description" SG_ 2214658049 EMS_Crc2Val "The data area for CRC calculation is based on the data length (DLC) of the message DB.

The CRC shall be calculated over the entire data block (excluding the CRC bytes) including the user data, alive counter and Data ID

 

- CRC Polynomial (0x1021) , Initial Value : 0xFFFF, XOR value : 0x0000, Data ID : Message ID + 0xF800 

- The initial value is for CRC calculation and the message should be sent with the calculated result value. 

- The mathematical expression to 16 bit CRC polynomial is given here. G(x) = x16 + x12 + x5 + 1";
BA_ "GenSigStartValue" SG_ 2214658049 EMS_Crc2Val 65535;
BA_ "UserSigValidity" SG_ 2214658049 EMS_Crc2Val 3;
BA_ "RoutingFactor" SG_ 2214658049 EMS_Crc2Val 5;
BA_ "Version" SG_ 2214658049 EMS_Crc2Val "18.11.08";
BA_ "Description" SG_ 2214658049 EMS_AlvCnt2Val "For the first transmission request for a data element the counter shall be initialized with 0 and shall be incremented by 1 for every subsequent send request. 

When the counter reaches the maximum value(0xFF), then it shall restart with 0 for the next send request";
BA_ "UserSigValidity" SG_ 2214658049 EMS_AlvCnt2Val 3;
BA_ "RoutingFactor" SG_ 2214658049 EMS_AlvCnt2Val 5;
BA_ "Version" SG_ 2214658049 EMS_AlvCnt2Val "18.11.08";
BA_ "Description" SG_ 2214658049 ENG_BrkSwSta "This signal indicates that a brake switch is activated or not. When the brake switch is activated(pressed) its value is 01H otherwise its value is 00H.

If the EMS does not support this signal the value is 02H.



Physical range : 0 ... 100

Conversion : (PH) = (Unsigned)0.002 * (HEX)[%]";
BA_ "GenSigStartValue" SG_ 2214658049 ENG_BrkSwSta 1;
BA_ "UserSigValidity" SG_ 2214658049 ENG_BrkSwSta 3;
BA_ "RoutingFactor" SG_ 2214658049 ENG_BrkSwSta 5;
BA_ "Version" SG_ 2214658049 ENG_BrkSwSta "18.11.00";
BA_ "Description" SG_ 2214658049 ENG_ObdFrzFrmSta "An ECU which detects an OBD fault, requires the EMS to store a set of environmental conditions

(freeze frame). If the EMS follows this requirement it is acknowledged in OBD_FRF_ACK. Also the synchronization of OBD relevant ECUs is made by this signal:



Bit 3-5 is used for freeze frame acknowledgement.

Bit 2 is set, in case a driving cycle has started.

Bit 1 is set, in case a trip is finished.

Bit 0 is set, in case a warm up cycle is finished.



Bit 5, 4, 3 freeze frame status :

0 - No freeze frame stored

1 - Freeze frame requested by EMS

2 - Freeze frame requested by TCU

3 - Freeze frame requested by TCS

4~7 - Reserved";
BA_ "UserSigValidity" SG_ 2214658049 ENG_ObdFrzFrmSta 3;
BA_ "RoutingFactor" SG_ 2214658049 ENG_ObdFrzFrmSta 5;
BA_ "Version" SG_ 2214658049 ENG_ObdFrzFrmSta "17.12.00";
BA_ "Description" SG_ 2214658049 ENG_EngClntTempVal "Engine coolant temperature in EMS sensed via an A/D converter; converted into degrees centigrade (¡ÆC).";
BA_ "GenSigStartValue" SG_ 2214658049 ENG_EngClntTempVal 255;
BA_ "UserSigValidity" SG_ 2214658049 ENG_EngClntTempVal 3;
BA_ "RoutingFactor" SG_ 2214658049 ENG_EngClntTempVal 5;
BA_ "Version" SG_ 2214658049 ENG_EngClntTempVal "17.12.00";
BA_ "Description" SG_ 2214658049 ENG_MafCrctVal "The altitude correction factor MAF_FAC_ALTI_MMV is calculated from division of MAF by MAF_SUB_DIAG (=limp home-value for MAF) or from AMP_AD by 1013 mbar in order to take into account different atmospheric pressures at different altitudes.



The Initial-value of 1.0 indicates sea-level, whereas lower values indicate altitude. MAF_FAC_ALTI_MMV is limited to C_MAF_FAC_ALTI_MMV_MIN (=0.6) and C_MAF_FAC_ALTI_MMV_MAX (=1.1) by calibration.";
BA_ "GenSigStartValue" SG_ 2214658049 ENG_MafCrctVal 128;
BA_ "UserSigValidity" SG_ 2214658049 ENG_MafCrctVal 3;
BA_ "RoutingFactor" SG_ 2214658049 ENG_MafCrctVal 5;
BA_ "Version" SG_ 2214658049 ENG_MafCrctVal "17.12.00";
BA_ "Description" SG_ 2214658049 ENG_BattDscnctSta "The signal specifies that ECU has detected a disconnection of the battery since last driving cycle, and therefore has reset the adaptive values and failure memory.

If the EMS does not support this signal the value is 00H



The failure memory erasure is activated only if the calibration C_CONF_NVMY_RST is set to 1 inside the EMS.";
BA_ "UserSigValidity" SG_ 2214658049 ENG_BattDscnctSta 3;
BA_ "RoutingFactor" SG_ 2214658049 ENG_BattDscnctSta 5;
BA_ "Version" SG_ 2214658049 ENG_BattDscnctSta "17.12.00";
BA_ "Description" SG_ 2214658049 OBD_MilConfgVal "The signal specifies the Configuration of the MIL Handling and Failure Memory Management by ECU.";
BA_ "GenSigStartValue" SG_ 2214658049 OBD_MilConfgVal 3;
BA_ "UserSigValidity" SG_ 2214658049 OBD_MilConfgVal 3;
BA_ "RoutingFactor" SG_ 2214658049 OBD_MilConfgVal 5;
BA_ "Version" SG_ 2214658049 OBD_MilConfgVal "17.12.00";
BA_ "Description" SG_ 2214658049 ENG_EngSta "This signal indicates that a status of engine.";
BA_ "UserSigValidity" SG_ 2214658049 ENG_EngSta 3;
BA_ "RoutingFactor" SG_ 2214658049 ENG_EngSta 5;
BA_ "Version" SG_ 2214658049 ENG_EngSta "17.12.00";
BA_ "GenMsgSendType" BO_ 2214658050 0;
BA_ "GenMsgCycleTime" BO_ 2214658050 50;
BA_ "GenMsgCycleTimeFast" BO_ 2214658050 0;
BA_ "GenMsgNrOfRepetition" BO_ 2214658050 0;
BA_ "VFrameFormat" BO_ 2214658050 1;
BA_ "Description" SG_ 2214658050 ENG_Ack4EngStpSta "The signal specifies the acknowledgement of the request for the operating state 'engine stopped'.";
BA_ "UserSigValidity" SG_ 2214658050 ENG_Ack4EngStpSta 3;
BA_ "RoutingFactor" SG_ 2214658050 ENG_Ack4EngStpSta 5;
BA_ "Version" SG_ 2214658050 ENG_Ack4EngStpSta "17.12.00";
BA_ "Description" SG_ 2214658050 ENG_AccDrvAlertDisp "If EMS sends the No Auto cruise engaged status or Auto cruise Disengaged status, 

Cluster shall display the status of Auto cruise.";
BA_ "TimeoutValue" SG_ 2214658050 ENG_AccDrvAlertDisp "0x0";
BA_ "UserSigValidity" SG_ 2214658050 ENG_AccDrvAlertDisp 3;
BA_ "RoutingFactor" SG_ 2214658050 ENG_AccDrvAlertDisp 5;
BA_ "Version" SG_ 2214658050 ENG_AccDrvAlertDisp "19.12.08";
BA_ "Description" SG_ 2214658050 DSL_GlowCtrlReq "This signal indicates that a diesel ECU requests ISS system to control glow plugs. 



If the EMS does not support this signal the value is 00H";
BA_ "UserSigValidity" SG_ 2214658050 DSL_GlowCtrlReq 3;
BA_ "RoutingFactor" SG_ 2214658050 DSL_GlowCtrlReq 5;
BA_ "Version" SG_ 2214658050 DSL_GlowCtrlReq "17.12.00";
BA_ "Description" SG_ 2214658050 ENG_GlowLmpSta "This signal indicates that a status of glow lamp.



This signal is used for a Diesel or LPI Engine alternatively.";
BA_ "GenSigStartValue" SG_ 2214658050 ENG_GlowLmpSta 1;
BA_ "UserSigValidity" SG_ 2214658050 ENG_GlowLmpSta 3;
BA_ "RoutingFactor" SG_ 2214658050 ENG_GlowLmpSta 5;
BA_ "Version" SG_ 2214658050 ENG_GlowLmpSta "17.12.00";
BA_ "Description" SG_ 2214658050 ENG_ThrPosVal "The signal TPS is a measure of the throttle position.

The throttle position is determined via a potentiometer, which is connected mechanically to the throttle shaft. The voltage value, which is adjusted in the port via the voltage divider, is sensed in the EMS by an A/D converter. The lower mechanical stop (idle) is sensed by a learning algorithm (offset). If the EMS-ECU recognizes closed throttle then the value 20 H is carried over on the CAN. If the EMS-ECU detects full load, that means nearly perpendicular throttle position, then F5 H is carried over on the CAN bus. Even if the throttle position exceeds the full load detection throttle angle the transmitted HEX-value is limited to F5 H.



If an error is detected in sensing of the position, this is identified by the value FFH.";
BA_ "GenSigStartValue" SG_ 2214658050 ENG_ThrPosVal 32;
BA_ "UserSigValidity" SG_ 2214658050 ENG_ThrPosVal 3;
BA_ "RoutingFactor" SG_ 2214658050 ENG_ThrPosVal 5;
BA_ "Version" SG_ 2214658050 ENG_ThrPosVal "17.12.00";
BA_ "Description" SG_ 2214658050 ENG_OverDrvOffReq "This signal indicates that auto cruise control function requests over drive off of TCU. 

In general, the over drive off request is done by hardware. (i.e. line-to-line signal between an EMS and a TCU). However, some systems may not have external over drive off requetst signal line and for these systems OD_OFF_REQ signal can be used as the same function.";
BA_ "UserSigValidity" SG_ 2214658050 ENG_OverDrvOffReq 3;
BA_ "RoutingFactor" SG_ 2214658050 ENG_OverDrvOffReq 5;
BA_ "Version" SG_ 2214658050 ENG_OverDrvOffReq "17.12.00";
BA_ "Description" SG_ 2214658050 ENG_AccelPdlVal "The signal PV_AV_CAN is a measure of the Accelerator Pedal value.

The accelerator pedal value is determined via 2 pedal sensors, which are connected mechanically to the

accelerator pedal. If the EMS-ECU recognizes that the accelerator pedal is not activated, then the value

00 H is carried over on the CAN. If the EMS-ECU detects that the accelerator pedal is fully activated, then 3FEH is carried over on the CAN bus.

If an error is detected on both pedal sensor channels, this is identified by the value 3FFH.



Signal relationship between ACC_ACT and PV_AV_CAN :

The phase relationship between auto cruise control and PV_AV_CAN is as following figure. If an auto cruise control system is not installed or if cruise control is not activated in auto cruise control system installed vehicle then PV_AV_CAN has actual pedal position value. But if the auto cruise control is activated (actually speed control is performed by EMS), PV_AV_CAN should have modeling value even if a driver does not press the acceleration pedal.

If ACC_ACT is value(0), then PV_AV_CAN is APS Value.

If ACC_ACT is value(1), then PV_AV_CAN is Modeling Value.

* APS Value : Acceleration Pedal Sensor value.

* Modeling Value : Estimated APS value which is calculated by ECU logic considering engine control during the auto-cruise control is activated period. (e.g. estimated throttle value of

gasoline engine system or TPS model value of diesel engine system)

And also this value can be used as a driver intension for the shift control of an A/T during auto-cruise control.



Signal relationship between PV_AV_CAN and TPS in DIESEL system :

In a diesel engine vehicle which has an ETC system, basically TPS has APS value. And if auto cruise control is activated then both TPS and PV_AV_CAN should have modeling value which is estimated according to the actual fuel injection and other factors that affect engine torque.";
BA_ "UserSigValidity" SG_ 2214658050 ENG_AccelPdlVal 3;
BA_ "RoutingFactor" SG_ 2214658050 ENG_AccelPdlVal 5;
BA_ "Version" SG_ 2214658050 ENG_AccelPdlVal "18.01.01";
BA_ "Description" SG_ 2214658050 ENG_AccActSta "EMS sends the state of the cruise control via the signal ACC_ACT. 

If the EMS does not support this signal the value is 00H



If the cruise control is activated then ACC_ACT = 1. In this period, vehicle speed control (cruise control) is performed by the auto-cruise control function of ECU only (including acceleration control, deceleration control, etc.). 

Although ¡°SCC set¡± switch is on (Cruise control is enabled), if the cruise control function is deactivated (e.g. when a driver presses an accel. pedal or a brake pedal to increase or to decarese vcehicle speed more or less than set speed) then ACC_ACT should be set to ¡®0¡¯.";
BA_ "UserSigValidity" SG_ 2214658050 ENG_AccActSta 3;
BA_ "RoutingFactor" SG_ 2214658050 ENG_AccActSta 5;
BA_ "Version" SG_ 2214658050 ENG_AccActSta "17.12.00";
BA_ "Description" SG_ 2214658050 ACC_CrsMainSwLmpSta "This signal indicates that an ECU requests cluster to turn on/off auto-cruise control ¡°MAIN¡± switch indication lamp.



This signal is for the CAN-type cluster installed vehicled only.";
BA_ "UserSigValidity" SG_ 2214658050 ACC_CrsMainSwLmpSta 3;
BA_ "RoutingFactor" SG_ 2214658050 ACC_CrsMainSwLmpSta 5;
BA_ "Version" SG_ 2214658050 ACC_CrsMainSwLmpSta "17.12.00";
BA_ "Description" SG_ 2214658050 ACC_CrsSetSwLmpSta "This signal indicates that an ECU requests cluster to turn on/off auto-cruise control ¡°SET¡± switch indication lamp.



This signal is for the CAN-type cluster installed vehicled only.";
BA_ "UserSigValidity" SG_ 2214658050 ACC_CrsSetSwLmpSta 3;
BA_ "RoutingFactor" SG_ 2214658050 ACC_CrsSetSwLmpSta 5;
BA_ "Version" SG_ 2214658050 ACC_CrsSetSwLmpSta "17.12.00";
BA_ "Description" SG_ 2214658050 ENG_LV_FUP_ENA_THD "The signal indicates that the status of the pressure on fuel rail is enough high to start engine.

(LPI)";
BA_ "UserSigValidity" SG_ 2214658050 ENG_LV_FUP_ENA_THD 3;
BA_ "RoutingFactor" SG_ 2214658050 ENG_LV_FUP_ENA_THD 5;
BA_ "Version" SG_ 2214658050 ENG_LV_FUP_ENA_THD "18.12.01";
BA_ "Description" SG_ 2214658050 ENG_SoakTimeErrSta "This signal indicates that information on soak time error.";
BA_ "UserSigValidity" SG_ 2214658050 ENG_SoakTimeErrSta 3;
BA_ "RoutingFactor" SG_ 2214658050 ENG_SoakTimeErrSta 5;
BA_ "Version" SG_ 2214658050 ENG_SoakTimeErrSta "17.12.00";
BA_ "Description" SG_ 2214658050 ENG_SoakTimeVal "The Signal SOAK_TIME means the duration from Engine Ignition Off to Ignition On.";
BA_ "UserSigValidity" SG_ 2214658050 ENG_SoakTimeVal 3;
BA_ "RoutingFactor" SG_ 2214658050 ENG_SoakTimeVal 5;
BA_ "Version" SG_ 2214658050 ENG_SoakTimeVal "17.12.00";
BA_ "Description" SG_ 2214658050 ENG_SprkTimeVal "This signal indicates output value of final spark timing from ECU which reflects torque intervention requests by ESC(TCS), SCC and TCU.



Physical range:

-35.625¢ª ¡¦ 0¢ª  =  00H .. 5FH (Retard)

0.375¢ª ¡¦ 60¢ª  =  60H .. FFH (Advance) 



Conversion:  (PH)=((HEX)-5FH) * 0.375 [¢ª ] (Advance)

(PH)=(5FH-(HEX)) *(- 0.375) [¢ª ] (Retard)";
BA_ "UserSigValidity" SG_ 2214658050 ENG_SprkTimeVal 3;
BA_ "RoutingFactor" SG_ 2214658050 ENG_SprkTimeVal 5;
BA_ "Version" SG_ 2214658050 ENG_SprkTimeVal "17.12.00";
BA_ "Description" SG_ 2214658050 ENG_CltchOpSta "This signal indicates that ECU has detected an operation of a clutch. Using this signal an ISG (Idle Stop & Go) system acts as an alternator or a starter.



If the EMS does not support this signal the value is 00H";
BA_ "UserSigValidity" SG_ 2214658050 ENG_CltchOpSta 3;
BA_ "RoutingFactor" SG_ 2214658050 ENG_CltchOpSta 5;
BA_ "Version" SG_ 2214658050 ENG_CltchOpSta "17.12.00";
BA_ "Description" SG_ 2214658050 EMS_BrkReq_Slope "Brake request at slope for anti-stall";
BA_ "UserSigValidity" SG_ 2214658050 EMS_BrkReq_Slope 3;
BA_ "RoutingFactor" SG_ 2214658050 EMS_BrkReq_Slope 5;
BA_ "Version" SG_ 2214658050 EMS_BrkReq_Slope "20.04.06";
BA_ "GenMsgSendType" BO_ 2214658051 0;
BA_ "GenMsgCycleTime" BO_ 2214658051 50;
BA_ "GenMsgCycleTimeFast" BO_ 2214658051 0;
BA_ "GenMsgNrOfRepetition" BO_ 2214658051 0;
BA_ "VFrameFormat" BO_ 2214658051 1;
BA_ "Description" SG_ 2214658051 ENG_MinIndTqVal "The signal TQI_MIN is the minimum engine torque (minimum air charging rate) which can be fired without misfire including compensation factors such as atmospheric pressure and temperature.

It is not enough to keep the engine running without external power such as inertia.

Firing is impossible below TQI_MIN even if engine is turning by inertia. The friction torque is

always greater than TQI_MIN which is almost constant value across engine RPM.

This signal is used to determine when activation of automatic braking is required to achieve a certain deceleration or if the engine deceleration is sufficient under current conditions.



Under normal driving conditions the physical value of this signal is negative:

TQ_MIN[Nm] = TQI_MIN[Nm] - TQFR[Nm]



If MSB is 1, this signal is - value.

else, this signal is +value.

0~10bit is used for absolute value.";
BA_ "UserSigValidity" SG_ 2214658051 ENG_MinIndTqVal 3;
BA_ "RoutingFactor" SG_ 2214658051 ENG_MinIndTqVal 5;
BA_ "Version" SG_ 2214658051 ENG_MinIndTqVal "18.01.01";
BA_ "Description" SG_ 2214658051 ENG_TrgtTqVal "The signal TQI_TARGET is determined by an engine torque map with input which consists of  acceleration pedal value, MAF sensor, current RPM and etc. This signal reflects driver¡¯s demand directly. 

But it does not depend on torque interventions realised due to reduction of airflow into the engine cylinders and due to ignition angle adjustment or injection/cylinder shut off.



In case of failures of the load signal (either MAF error or other errors depending on the system congiguration), a backup value is generated from specific index tables. The backup value mode is identified by the signal F_SUB_TQI. 



There is a specific phase relationship between the signals TQI_TARGET and F_SUB_TQI.



If MSB is 1, this signal is - value.

else, this signal is +value.

0~10bit is used for absolute value.";
BA_ "UserSigValidity" SG_ 2214658051 ENG_TrgtTqVal 3;
BA_ "RoutingFactor" SG_ 2214658051 ENG_TrgtTqVal 5;
BA_ "Version" SG_ 2214658051 ENG_TrgtTqVal "18.01.01";
BA_ "Description" SG_ 2214658051 ENG_MaxIndTqVal "The signal TQI_MAX is the current maximum indicated engine torque. This signal reflects the maximum engine torque under current conditions (engine speed, etc¡¦).



Note : TQI_MAX must be transmitted actual engine torque including COT, thermal/spark efficiency etc..

 This means that the TQI_ACOR can reach to the TQI_MAX.

 If not possible, thTQI_MAX should be ¡° FFH¡± (99.6%) to reduce TCS/ESC variant.



TQ_MAX[Nm] = TQI_MAX[Nm] - TQFR[Nm]



If MSB is 1, this signal is - value.

else, this signal is +value.

0~10bit is used for absolute value.";
BA_ "UserSigValidity" SG_ 2214658051 ENG_MaxIndTqVal 3;
BA_ "RoutingFactor" SG_ 2214658051 ENG_MaxIndTqVal 5;
BA_ "Version" SG_ 2214658051 ENG_MaxIndTqVal "18.01.01";
BA_ "Description" SG_ 2214658051 ENG_AppAccelPdlSta "This signal indicates if the driver applies the accelerator pedal. 

The signal always indicates the actual operation of the accelerator pedal, independent from SCC mode.";
BA_ "UserSigValidity" SG_ 2214658051 ENG_AppAccelPdlSta 3;
BA_ "RoutingFactor" SG_ 2214658051 ENG_AppAccelPdlSta 5;
BA_ "Version" SG_ 2214658051 ENG_AppAccelPdlSta "17.12.00";
BA_ "Description" SG_ 2214658051 ENG_BrkCtrlReq "This signal indicates that if brake control request during cruise control or speed limiter is active or not. This signal is for prevention of unwanted vehicle speed increase during cruise control or speed limiter control mode.";
BA_ "UserSigValidity" SG_ 2214658051 ENG_BrkCtrlReq 3;
BA_ "RoutingFactor" SG_ 2214658051 ENG_BrkCtrlReq 5;
BA_ "Version" SG_ 2214658051 ENG_BrkCtrlReq "17.12.00";
BA_ "Description" SG_ 2214658051 ACC_DnShftCtrlReq "This signal indicates target gear for downshift control request during cruise control or speed limiter is active or not. This signal is for prevention of unwanted vehicle speed increase during cruise control or speed limiter control mode.";
BA_ "UserSigValidity" SG_ 2214658051 ACC_DnShftCtrlReq 3;
BA_ "RoutingFactor" SG_ 2214658051 ACC_DnShftCtrlReq 5;
BA_ "Version" SG_ 2214658051 ACC_DnShftCtrlReq "17.12.00";
BA_ "GenMsgSendType" BO_ 2214658052 0;
BA_ "GenMsgCycleTime" BO_ 2214658052 50;
BA_ "GenMsgCycleTimeFast" BO_ 2214658052 0;
BA_ "GenMsgNrOfRepetition" BO_ 2214658052 0;
BA_ "VFrameFormat" BO_ 2214658052 1;
BA_ "Description" SG_ 2214658052 ENG_DclBrkCntrlReq "When current vehicle speed goes over set vehicle speed in the downhill during cruise control or speed limiter, ECU requests brake control to TCS with target deceleration. This is function of (Current vehicle speed - Set vehicle speed).";
BA_ "GenSigStartValue" SG_ 2214658052 ENG_DclBrkCntrlReq 4094;
BA_ "UserSigValidity" SG_ 2214658052 ENG_DclBrkCntrlReq 3;
BA_ "RoutingFactor" SG_ 2214658052 ENG_DclBrkCntrlReq 5;
BA_ "Version" SG_ 2214658052 ENG_DclBrkCntrlReq "17.12.00";
BA_ "Description" SG_ 2214658052 ENG_BstPrsrVal "Boost pressure for Turbo engine";
BA_ "UserSigValidity" SG_ 2214658052 ENG_BstPrsrVal 3;
BA_ "RoutingFactor" SG_ 2214658052 ENG_BstPrsrVal 5;
BA_ "Version" SG_ 2214658052 ENG_BstPrsrVal "17.12.00";
BA_ "Description" SG_ 2214658052 ENG_EngOilTempVal "engine oil temperature";
BA_ "GenSigStartValue" SG_ 2214658052 ENG_EngOilTempVal 53;
BA_ "UserSigValidity" SG_ 2214658052 ENG_EngOilTempVal 3;
BA_ "RoutingFactor" SG_ 2214658052 ENG_EngOilTempVal 5;
BA_ "Version" SG_ 2214658052 ENG_EngOilTempVal "17.12.00";
BA_ "Description" SG_ 2214658052 ENG_AmbtTempModelVal "Modeled Ambient temperature";
BA_ "GenSigStartValue" SG_ 2214658052 ENG_AmbtTempModelVal 164;
BA_ "UserSigValidity" SG_ 2214658052 ENG_AmbtTempModelVal 3;
BA_ "RoutingFactor" SG_ 2214658052 ENG_AmbtTempModelVal 5;
BA_ "Version" SG_ 2214658052 ENG_AmbtTempModelVal "17.12.00";
BA_ "Description" SG_ 2214658052 ENG_DpfWrngSta "The signal indicates the status of the 'DPF Warning Level'";
BA_ "UserSigValidity" SG_ 2214658052 ENG_DpfWrngSta 3;
BA_ "RoutingFactor" SG_ 2214658052 ENG_DpfWrngSta 5;
BA_ "Version" SG_ 2214658052 ENG_DpfWrngSta "17.12.00";
BA_ "Description" SG_ 2214658052 ENG_BattWrngLmpSta "The signal indicates the status of the 'Battery Warning Lamp'";
BA_ "UserSigValidity" SG_ 2214658052 ENG_BattWrngLmpSta 3;
BA_ "RoutingFactor" SG_ 2214658052 ENG_BattWrngLmpSta 5;
BA_ "Version" SG_ 2214658052 ENG_BattWrngLmpSta "17.12.00";
BA_ "Description" SG_ 2214658052 ENG_OilPrsrWrngLmpSta "The signal indicates the status of the 'Oil Pressure Warning Lamp'";
BA_ "UserSigValidity" SG_ 2214658052 ENG_OilPrsrWrngLmpSta 3;
BA_ "RoutingFactor" SG_ 2214658052 ENG_OilPrsrWrngLmpSta 5;
BA_ "Version" SG_ 2214658052 ENG_OilPrsrWrngLmpSta "17.12.00";
BA_ "Description" SG_ 2214658052 ENG_IsgInhbtLmpSta "The signal indicates the status of the 'ISG Inhibit Lamp'";
BA_ "UserSigValidity" SG_ 2214658052 ENG_IsgInhbtLmpSta 3;
BA_ "RoutingFactor" SG_ 2214658052 ENG_IsgInhbtLmpSta 5;
BA_ "Version" SG_ 2214658052 ENG_IsgInhbtLmpSta "17.12.00";
BA_ "GenMsgCycleTime" BO_ 1616 0;
BA_ "GenSigSendType" SG_ 1616 MKBD_IllumiState 4;
BA_ "GenSigStartValue" SG_ 1616 MKBD_IllumiState 3;
BA_ "UserSigValidity" SG_ 1616 MKBD_IllumiState 1;
BA_ "Version" SG_ 1616 MKBD_IllumiState "20.04.02";
BA_ "Description" SG_ 1616 MKBD_SeatKeySet "The signal for transmitting Seat Key inputs from MKBD to Seat ECU

Release : 0x0 / Press : 0x1";
BA_ "GenSigSendType" SG_ 1616 MKBD_SeatKeySet 4;
BA_ "GenSigStartValue" SG_ 1616 MKBD_SeatKeySet 3;
BA_ "UserSigValidity" SG_ 1616 MKBD_SeatKeySet 3;
BA_REL_ "GenSigTimeoutTime" BU_SG_REL_ APSU SG_ 1616 MKBD_SeatKeySet 0;
BA_REL_ "GenSigTimeoutTime" BU_SG_REL_ SHVU_FR SG_ 1616 MKBD_SeatKeySet 0;
BA_REL_ "GenSigTimeoutTime" BU_SG_REL_ DPSU SG_ 1616 MKBD_SeatKeySet 0;
BA_ "Version" SG_ 1616 MKBD_SeatKeySet "20.06.07";
BA_ "GenMsgCycleTime" BO_ 1578 0;
BA_ "GenMsgILSupport" BO_ 1578 0;
BA_ "TpMessage" BO_ 1578 1;
BA_ "GenMsgDelayTime" BO_ 1578 10;
BA_ "UsrSigPurpose" SG_ 1578 PSB_CCP_CRO_Byte0 0;
BA_ "GenSigSendType" SG_ 1578 PSB_CCP_CRO_Byte0 2;
BA_ "UserSigValidity" SG_ 1578 PSB_CCP_CRO_Byte0 0;
BA_REL_ "GenSigTimeoutTime" BU_SG_REL_ PSB SG_ 1578 PSB_CCP_CRO_Byte0 0;
BA_ "NetworkRequest" SG_ 1578 PSB_CCP_CRO_Byte0 0;
BA_ "NetworkRequestHoldingTime" SG_ 1578 PSB_CCP_CRO_Byte0 5000;
BA_ "Version" SG_ 1578 PSB_CCP_CRO_Byte0 "21.02.04";
BA_ "UsrSigPurpose" SG_ 1578 PSB_CCP_CRO_Byte2 0;
BA_ "GenSigSendType" SG_ 1578 PSB_CCP_CRO_Byte2 2;
BA_ "UserSigValidity" SG_ 1578 PSB_CCP_CRO_Byte2 0;
BA_REL_ "GenSigTimeoutTime" BU_SG_REL_ PSB SG_ 1578 PSB_CCP_CRO_Byte2 0;
BA_ "NetworkRequest" SG_ 1578 PSB_CCP_CRO_Byte2 0;
BA_ "NetworkRequestHoldingTime" SG_ 1578 PSB_CCP_CRO_Byte2 5000;
BA_ "Version" SG_ 1578 PSB_CCP_CRO_Byte2 "21.02.04";
BA_ "UsrSigPurpose" SG_ 1578 PSB_CCP_CRO_Byte3 0;
BA_ "GenSigSendType" SG_ 1578 PSB_CCP_CRO_Byte3 2;
BA_ "UserSigValidity" SG_ 1578 PSB_CCP_CRO_Byte3 0;
BA_REL_ "GenSigTimeoutTime" BU_SG_REL_ PSB SG_ 1578 PSB_CCP_CRO_Byte3 0;
BA_ "NetworkRequest" SG_ 1578 PSB_CCP_CRO_Byte3 0;
BA_ "NetworkRequestHoldingTime" SG_ 1578 PSB_CCP_CRO_Byte3 5000;
BA_ "Version" SG_ 1578 PSB_CCP_CRO_Byte3 "21.02.04";
BA_ "UsrSigPurpose" SG_ 1578 PSB_CCP_CRO_Byte4 0;
BA_ "GenSigSendType" SG_ 1578 PSB_CCP_CRO_Byte4 2;
BA_ "UserSigValidity" SG_ 1578 PSB_CCP_CRO_Byte4 0;
BA_REL_ "GenSigTimeoutTime" BU_SG_REL_ PSB SG_ 1578 PSB_CCP_CRO_Byte4 0;
BA_ "NetworkRequest" SG_ 1578 PSB_CCP_CRO_Byte4 0;
BA_ "NetworkRequestHoldingTime" SG_ 1578 PSB_CCP_CRO_Byte4 5000;
BA_ "Version" SG_ 1578 PSB_CCP_CRO_Byte4 "21.02.04";
BA_ "UsrSigPurpose" SG_ 1578 PSB_CCP_CRO_Byte5 0;
BA_ "GenSigSendType" SG_ 1578 PSB_CCP_CRO_Byte5 2;
BA_ "UserSigValidity" SG_ 1578 PSB_CCP_CRO_Byte5 0;
BA_REL_ "GenSigTimeoutTime" BU_SG_REL_ PSB SG_ 1578 PSB_CCP_CRO_Byte5 0;
BA_ "NetworkRequest" SG_ 1578 PSB_CCP_CRO_Byte5 0;
BA_ "NetworkRequestHoldingTime" SG_ 1578 PSB_CCP_CRO_Byte5 5000;
BA_ "Version" SG_ 1578 PSB_CCP_CRO_Byte5 "21.02.04";
BA_ "UsrSigPurpose" SG_ 1578 PSB_CCP_CRO_Byte6 0;
BA_ "GenSigSendType" SG_ 1578 PSB_CCP_CRO_Byte6 2;
BA_ "UserSigValidity" SG_ 1578 PSB_CCP_CRO_Byte6 0;
BA_REL_ "GenSigTimeoutTime" BU_SG_REL_ PSB SG_ 1578 PSB_CCP_CRO_Byte6 0;
BA_ "NetworkRequest" SG_ 1578 PSB_CCP_CRO_Byte6 0;
BA_ "NetworkRequestHoldingTime" SG_ 1578 PSB_CCP_CRO_Byte6 5000;
BA_ "Version" SG_ 1578 PSB_CCP_CRO_Byte6 "21.02.04";
BA_ "UsrSigPurpose" SG_ 1578 PSB_CCP_CRO_Byte7 0;
BA_ "GenSigSendType" SG_ 1578 PSB_CCP_CRO_Byte7 2;
BA_ "UserSigValidity" SG_ 1578 PSB_CCP_CRO_Byte7 0;
BA_REL_ "GenSigTimeoutTime" BU_SG_REL_ PSB SG_ 1578 PSB_CCP_CRO_Byte7 0;
BA_ "NetworkRequest" SG_ 1578 PSB_CCP_CRO_Byte7 0;
BA_ "NetworkRequestHoldingTime" SG_ 1578 PSB_CCP_CRO_Byte7 5000;
BA_ "Version" SG_ 1578 PSB_CCP_CRO_Byte7 "21.02.04";
BA_ "UsrSigPurpose" SG_ 1578 PSB_CCP_CRO_Byte1 0;
BA_ "GenSigSendType" SG_ 1578 PSB_CCP_CRO_Byte1 2;
BA_ "UserSigValidity" SG_ 1578 PSB_CCP_CRO_Byte1 0;
BA_REL_ "GenSigTimeoutTime" BU_SG_REL_ PSB SG_ 1578 PSB_CCP_CRO_Byte1 0;
BA_ "NetworkRequest" SG_ 1578 PSB_CCP_CRO_Byte1 0;
BA_ "NetworkRequestHoldingTime" SG_ 1578 PSB_CCP_CRO_Byte1 5000;
BA_ "Version" SG_ 1578 PSB_CCP_CRO_Byte1 "21.02.04";
BA_ "GenMsgCycleTime" BO_ 1579 0;
BA_ "GenMsgILSupport" BO_ 1579 0;
BA_ "TpMessage" BO_ 1579 1;
BA_ "GenMsgDelayTime" BO_ 1579 10;
BA_ "UsrSigPurpose" SG_ 1579 PSB_CCP_DTO_Byte0 0;
BA_ "GenSigSendType" SG_ 1579 PSB_CCP_DTO_Byte0 2;
BA_ "UserSigValidity" SG_ 1579 PSB_CCP_DTO_Byte0 0;
BA_REL_ "GenSigTimeoutTime" BU_SG_REL_ CGW_CCU SG_ 1579 PSB_CCP_DTO_Byte0 0;
BA_ "NetworkRequest" SG_ 1579 PSB_CCP_DTO_Byte0 0;
BA_ "NetworkRequestHoldingTime" SG_ 1579 PSB_CCP_DTO_Byte0 5000;
BA_ "Version" SG_ 1579 PSB_CCP_DTO_Byte0 "21.02.04";
BA_ "UsrSigPurpose" SG_ 1579 PSB_CCP_DTO_Byte2 0;
BA_ "GenSigSendType" SG_ 1579 PSB_CCP_DTO_Byte2 2;
BA_ "UserSigValidity" SG_ 1579 PSB_CCP_DTO_Byte2 0;
BA_REL_ "GenSigTimeoutTime" BU_SG_REL_ CGW_CCU SG_ 1579 PSB_CCP_DTO_Byte2 0;
BA_ "NetworkRequest" SG_ 1579 PSB_CCP_DTO_Byte2 0;
BA_ "NetworkRequestHoldingTime" SG_ 1579 PSB_CCP_DTO_Byte2 5000;
BA_ "Version" SG_ 1579 PSB_CCP_DTO_Byte2 "21.02.04";
BA_ "UsrSigPurpose" SG_ 1579 PSB_CCP_DTO_Byte3 0;
BA_ "GenSigSendType" SG_ 1579 PSB_CCP_DTO_Byte3 2;
BA_ "UserSigValidity" SG_ 1579 PSB_CCP_DTO_Byte3 0;
BA_REL_ "GenSigTimeoutTime" BU_SG_REL_ CGW_CCU SG_ 1579 PSB_CCP_DTO_Byte3 0;
BA_ "NetworkRequest" SG_ 1579 PSB_CCP_DTO_Byte3 0;
BA_ "NetworkRequestHoldingTime" SG_ 1579 PSB_CCP_DTO_Byte3 5000;
BA_ "Version" SG_ 1579 PSB_CCP_DTO_Byte3 "21.02.04";
BA_ "UsrSigPurpose" SG_ 1579 PSB_CCP_DTO_Byte4 0;
BA_ "GenSigSendType" SG_ 1579 PSB_CCP_DTO_Byte4 2;
BA_ "UserSigValidity" SG_ 1579 PSB_CCP_DTO_Byte4 0;
BA_REL_ "GenSigTimeoutTime" BU_SG_REL_ CGW_CCU SG_ 1579 PSB_CCP_DTO_Byte4 0;
BA_ "NetworkRequest" SG_ 1579 PSB_CCP_DTO_Byte4 0;
BA_ "NetworkRequestHoldingTime" SG_ 1579 PSB_CCP_DTO_Byte4 5000;
BA_ "Version" SG_ 1579 PSB_CCP_DTO_Byte4 "21.02.04";
BA_ "UsrSigPurpose" SG_ 1579 PSB_CCP_DTO_Byte5 0;
BA_ "GenSigSendType" SG_ 1579 PSB_CCP_DTO_Byte5 2;
BA_ "UserSigValidity" SG_ 1579 PSB_CCP_DTO_Byte5 0;
BA_REL_ "GenSigTimeoutTime" BU_SG_REL_ CGW_CCU SG_ 1579 PSB_CCP_DTO_Byte5 0;
BA_ "NetworkRequest" SG_ 1579 PSB_CCP_DTO_Byte5 0;
BA_ "NetworkRequestHoldingTime" SG_ 1579 PSB_CCP_DTO_Byte5 5000;
BA_ "Version" SG_ 1579 PSB_CCP_DTO_Byte5 "21.02.04";
BA_ "UsrSigPurpose" SG_ 1579 PSB_CCP_DTO_Byte6 0;
BA_ "GenSigSendType" SG_ 1579 PSB_CCP_DTO_Byte6 2;
BA_ "UserSigValidity" SG_ 1579 PSB_CCP_DTO_Byte6 0;
BA_REL_ "GenSigTimeoutTime" BU_SG_REL_ CGW_CCU SG_ 1579 PSB_CCP_DTO_Byte6 0;
BA_ "NetworkRequest" SG_ 1579 PSB_CCP_DTO_Byte6 0;
BA_ "NetworkRequestHoldingTime" SG_ 1579 PSB_CCP_DTO_Byte6 5000;
BA_ "Version" SG_ 1579 PSB_CCP_DTO_Byte6 "21.02.04";
BA_ "UsrSigPurpose" SG_ 1579 PSB_CCP_DTO_Byte7 0;
BA_ "GenSigSendType" SG_ 1579 PSB_CCP_DTO_Byte7 2;
BA_ "UserSigValidity" SG_ 1579 PSB_CCP_DTO_Byte7 0;
BA_REL_ "GenSigTimeoutTime" BU_SG_REL_ CGW_CCU SG_ 1579 PSB_CCP_DTO_Byte7 0;
BA_ "NetworkRequest" SG_ 1579 PSB_CCP_DTO_Byte7 0;
BA_ "NetworkRequestHoldingTime" SG_ 1579 PSB_CCP_DTO_Byte7 5000;
BA_ "Version" SG_ 1579 PSB_CCP_DTO_Byte7 "21.02.04";
BA_ "UsrSigPurpose" SG_ 1579 PSB_CCP_DTO_Byte1 0;
BA_ "GenSigSendType" SG_ 1579 PSB_CCP_DTO_Byte1 2;
BA_ "UserSigValidity" SG_ 1579 PSB_CCP_DTO_Byte1 0;
BA_REL_ "GenSigTimeoutTime" BU_SG_REL_ CGW_CCU SG_ 1579 PSB_CCP_DTO_Byte1 0;
BA_ "NetworkRequest" SG_ 1579 PSB_CCP_DTO_Byte1 0;
BA_ "NetworkRequestHoldingTime" SG_ 1579 PSB_CCP_DTO_Byte1 5000;
BA_ "Version" SG_ 1579 PSB_CCP_DTO_Byte1 "21.02.04";
BA_ "GenMsgSendType" BO_ 1027 0;
BA_ "GenSigSendType" SG_ 1027 Win_ElecChildLkSwOpt 4;
BA_ "UserSigValidity" SG_ 1027 Win_ElecChildLkSwOpt 0;
BA_ "NetworkRequest" SG_ 1027 Win_ElecChildLkSwOpt 0;
BA_ "NetworkRequestHoldingTime" SG_ 1027 Win_ElecChildLkSwOpt 5000;
BA_ "Version" SG_ 1027 Win_ElecChildLkSwOpt "20.12.05";
BA_ "GenSigSendType" SG_ 1027 Win_PwrWdwSwTyp 4;
BA_ "UserSigValidity" SG_ 1027 Win_PwrWdwSwTyp 0;
BA_ "NetworkRequest" SG_ 1027 Win_PwrWdwSwTyp 0;
BA_ "NetworkRequestHoldingTime" SG_ 1027 Win_PwrWdwSwTyp 5000;
BA_ "Version" SG_ 1027 Win_PwrWdwSwTyp "20.12.05";
BA_ "GenSigSendType" SG_ 1027 Win_DrvIMSSwSta 4;
BA_ "UserSigValidity" SG_ 1027 Win_DrvIMSSwSta 0;
BA_REL_ "GenSigTimeoutTime" BU_SG_REL_ DPSU SG_ 1027 Win_DrvIMSSwSta 1500;
BA_ "NetworkRequest" SG_ 1027 Win_DrvIMSSwSta 0;
BA_ "NetworkRequestHoldingTime" SG_ 1027 Win_DrvIMSSwSta 5000;
BA_ "Version" SG_ 1027 Win_DrvIMSSwSta "20.12.05";
BA_ "GenSigSendType" SG_ 1027 Win_DrvPwrWdwSwSta 4;
BA_ "UserSigValidity" SG_ 1027 Win_DrvPwrWdwSwSta 0;
BA_ "NetworkRequest" SG_ 1027 Win_DrvPwrWdwSwSta 0;
BA_ "NetworkRequestHoldingTime" SG_ 1027 Win_DrvPwrWdwSwSta 5000;
BA_ "Version" SG_ 1027 Win_DrvPwrWdwSwSta "20.12.05";
BA_ "GenSigSendType" SG_ 1027 Win_AsstPwrWdwSwSta 4;
BA_ "UserSigValidity" SG_ 1027 Win_AsstPwrWdwSwSta 0;
BA_ "NetworkRequest" SG_ 1027 Win_AsstPwrWdwSwSta 0;
BA_ "NetworkRequestHoldingTime" SG_ 1027 Win_AsstPwrWdwSwSta 5000;
BA_ "Version" SG_ 1027 Win_AsstPwrWdwSwSta "20.12.05";
BA_ "GenSigSendType" SG_ 1027 Win_CtrlDrLkSwSta 4;
BA_ "UserSigValidity" SG_ 1027 Win_CtrlDrLkSwSta 0;
BA_ "NetworkRequest" SG_ 1027 Win_CtrlDrLkSwSta 0;
BA_ "NetworkRequestHoldingTime" SG_ 1027 Win_CtrlDrLkSwSta 5000;
BA_ "Version" SG_ 1027 Win_CtrlDrLkSwSta "20.12.05";
BA_ "GenSigSendType" SG_ 1027 Win_RrLftPwrWdwSwSta 4;
BA_ "UserSigValidity" SG_ 1027 Win_RrLftPwrWdwSwSta 0;
BA_ "NetworkRequest" SG_ 1027 Win_RrLftPwrWdwSwSta 0;
BA_ "NetworkRequestHoldingTime" SG_ 1027 Win_RrLftPwrWdwSwSta 5000;
BA_ "Version" SG_ 1027 Win_RrLftPwrWdwSwSta "20.12.05";
BA_ "GenSigSendType" SG_ 1027 Win_RrRtPwrWdwSwSta 4;
BA_ "UserSigValidity" SG_ 1027 Win_RrRtPwrWdwSwSta 0;
BA_ "NetworkRequest" SG_ 1027 Win_RrRtPwrWdwSwSta 0;
BA_ "NetworkRequestHoldingTime" SG_ 1027 Win_RrRtPwrWdwSwSta 5000;
BA_ "Version" SG_ 1027 Win_RrRtPwrWdwSwSta "20.12.05";
BA_ "GenSigSendType" SG_ 1027 Win_CtrlDrUnLkSwSta 4;
BA_ "UserSigValidity" SG_ 1027 Win_CtrlDrUnLkSwSta 0;
BA_ "NetworkRequest" SG_ 1027 Win_CtrlDrUnLkSwSta 0;
BA_ "NetworkRequestHoldingTime" SG_ 1027 Win_CtrlDrUnLkSwSta 5000;
BA_ "Version" SG_ 1027 Win_CtrlDrUnLkSwSta "20.12.05";
BA_ "GenSigSendType" SG_ 1027 Win_PwrWdwLkSwSta 4;
BA_ "UserSigValidity" SG_ 1027 Win_PwrWdwLkSwSta 0;
BA_ "NetworkRequest" SG_ 1027 Win_PwrWdwLkSwSta 0;
BA_ "NetworkRequestHoldingTime" SG_ 1027 Win_PwrWdwLkSwSta 5000;
BA_ "Version" SG_ 1027 Win_PwrWdwLkSwSta "20.12.05";
BA_ "GenSigSendType" SG_ 1027 Win_RrCrtSwSta 4;
BA_ "UserSigValidity" SG_ 1027 Win_RrCrtSwSta 0;
BA_ "NetworkRequest" SG_ 1027 Win_RrCrtSwSta 0;
BA_ "NetworkRequestHoldingTime" SG_ 1027 Win_RrCrtSwSta 5000;
BA_ "Version" SG_ 1027 Win_RrCrtSwSta "20.12.05";
VAL_ 2223057409 LKA_OptUsmSta 0 "None LKA/LDW Option (Default)" 1 "LDW" 2 "LKA" 3 "Reserved" 4 "LDW Only (None LKA)" 5 "LDW only OFF (None LKA)" 6 "LDW/LKA OFF" 7 "Invalid" ;
VAL_ 2223057409 LKA_RcgSta 0 "Not Recognized" 1 "Left Lane Recognition" 2 "Right Lane Recognition" 3 "Full Lane Recognition" 4 "Reserved" 5 "Reserved" 6 "Reserved" 7 "Reserved" ;
VAL_ 2223057409 LKA_LHLnWrnSta 0 "No Warning" 1 "Lane Departure Warning" 2 "Reserved" 3 "Reserved" ;
VAL_ 2223057409 LKA_RHLnWrnSta 0 "No Warning" 1 "Lane Departure Warning" 2 "Reserved" 3 "Reserved" ;
VAL_ 2223057409 LKA_HndsoffSnd 0 "Off" 1 "Hands-off Sound Warning" 2 "Reserved" 3 "Reserved" ;
VAL_ 2223057409 LKA_SysIndReq 0 "Off" 1 "Unavailable_(Grey On)" 2 "Lane Recognized_(Green On)" 3 "Lane Departure_(Green Blink)" 4 "System Fail_(Orange On)" 5 "Not Calibrated_(Orange Blink)" 6 "Off for Regulation (Orange On)" 7 "Temp. Unavailable (Orange On)" ;
VAL_ 2223057409 ADAS_StrTqReqVal 0 "0x0x000~0x7FD:0~2045" 2045 "0x0x000~0x7FD:0~2045" 2046 "Reserved" 2047 "Invalid" ;
VAL_ 2223057409 ADAS_ActToiSta 0 "De-activate TOI" 1 "Activate TOI" 2 "Reserved" 3 "Error indicator" ;
VAL_ 2223057409 ADAS_ToiFltSta 0 "No Fault" 1 "Fault" 2 "Reserved" 3 "Error indicatorr" ;
VAL_ 2223057409 BCA_Rear_WrnSta 0 "No Warning" 1 "Left Warning" 2 "Right Warning" 3 "Left Control" 4 "Right Control" 5 "Reserved" 6 "Not used" 7 "Error indicator" ;
VAL_ 2223057409 LKA_SysWrn 0 "No Info" 1 "Reserved" 2 "Reserved" 3 "Reserved" 4 "Hands-Off Warning 1" 5 "Hands-Off Warning 2" 6 "Hands-Off Warning 3" 7 "Reserved" 8 "Reserved" 9 "System Automatic off" 10 "Reserved" 11 "Reserved" 12 "Reserved" 13 "Reserved" 14 "Blockage Warning" 15 "System Fail" ;
VAL_ 2223057410 FCA_LO_WrnSta 0 "No Warning" 1 "Left Warning" 2 "Right Warning" 3 "Left Control" 4 "Right Control" 5 "Reserved" 6 "Reserved" 7 "Error indicator" ;
VAL_ 2223057410 LKA_UsmMod 0 "NONE" 1 "LKA 1 mode" 2 "Reserved" 3 "LDW" ;
VAL_ 2223057410 ELK_SysFlrSta 0 "No Warning" 1 "Temp, Unavailable by Camera" 2 "Temp, Unavailable by Radar" 3 "Service Required" 4 "Reserved" 5 "Reserved" 6 "Reserved" 7 "Reserved" ;
VAL_ 2223057410 ELK_SymbDisp 0 "Default" 1 "No warning" 2 "ELK Amber warning on" 3 "ELK Red warning blingking" 4 "ELK Gray warning on" 5 "Reserved" 6 "Reserved" 7 "Reserved" ;
VAL_ 2223057410 FCA_ESA_WrnSta 0 "No Warning" 1 "Reserved" 2 "Reserved" 3 "Left Control" 4 "Right Control" 5 "Reserved" 6 "Reserved" 7 "Error Indicator" ;
VAL_ 2223057410 ADAS_ActAciSta 0 "Reserved" 1 "Standby" 2 "Active" 3 "Redundancy" 4 "Abort" 5 "Fail" ;
VAL_ 2223057410 FCA_ESA_CtrlSta 0 "No Control" 1 "FCA 1st Warning" 2 "FCA w/ ESA Driver Initiated Control" 3 "FCA w/ ESA Auto Control Step 1" 4 "FCA w/ ESA Auto Control Step 2" 5 "FCA w/ ESA Auto Control Step 3" 6 "Reserved" 7 "Error Indicator" ;
VAL_ 2223057410 FCA_LS_WrnSta 0 "No Warning" 1 "Left Warning" 2 "Right Warning" 3 "Left Control" 4 "Right Control" 5 "Reserved" 6 "Reserved" 7 "Error indicator" ;
VAL_ 2223057410 ADAS_Damping_Gain 0 "Reserved" 1 "Reserved" 2 "Reserved" 3 "0x3~0xC8:3 ~ 200%" 200 "0x3~0xC8:3 ~ 200%" 201 "Reserved" 202 "Reserved" 203 "Reserved" 204 "Reserved" 205 "Reserved" 206 "Reserved" 207 "Reserved" 208 "Reserved" 209 "Reserved" 210 "Reserved" 211 "Reserved" 212 "Reserved" 213 "Reserved" 214 "Reserved" 215 "Reserved" 216 "Reserved" 217 "Reserved" 218 "Reserved" 219 "Reserved" 220 "Reserved" 221 "Reserved" 222 "Reserved" 223 "Reserved" 224 "Reserved" 225 "Reserved" 226 "Reserved" 227 "Reserved" 228 "Reserved" 229 "Reserved" 230 "Reserved" 231 "Reserved" 232 "Reserved" 233 "Reserved" 234 "Reserved" 235 "Reserved" 236 "Reserved" 237 "Reserved" 238 "Reserved" 239 "Reserved" 240 "Reserved" 241 "Reserved" 242 "Reserved" 243 "Reserved" 244 "Reserved" 245 "Reserved" 246 "Reserved" 247 "Reserved" 248 "Reserved" 249 "Reserved" 250 "Reserved" 251 "Reserved" 252 "Reserved" 253 "Reserved" 254 "Reserved" 255 "Reserved" ;
VAL_ 2223057410 LKA_OnOffEquip2Sta 0 "Default" 1 "Off" 2 "On" 3 "Invalid" ;
VAL_ 2273435649 HDA_OptUsmSta 0 "Not Applied" 1 "Function Off" 2 "Function On" 3 "Reserved" 4 "Reserved" 5 "Reserved" 6 "Reserved" 7 "Invalid (Fail)" ;
VAL_ 2273435649 HDA_CntrlModSta 0 "System OFF (Default)" 1 "System STANDBY" 2 "System ACTIVE" 3 "Reserved" ;
VAL_ 2273435649 HDA_InfoPUDis 0 "No pop-up" 1 "system start pop-up" 2 "system auto disengaged pop-up by highway off" 3 "System Fail pop up (LFA)" 4 "System Fail pop up (HDA)" 5 "Hands-off pop up" 6 "Hands-off pop up w/sound" 7 "RESERVED" ;
VAL_ 2273435649 HDP_AutoCallReqSta 0 "No request" 1 "HDP MRM Auto Call Request" 2 "Reserved" 3 "Reserved" 4 "Reserved" 5 "Reserved" 6 "Cancel the HDP Auto Call" 7 "Invalid" ;
VAL_ 2273435649 HDP_DispBarSta 0 "Not Display" 1 "Reserved" 2 "Reserved" 3 "Amber Display" 4 "Red Display" 5 "Reserved" 6 "Reserved" 7 "Reserved" 8 "Reserved" 9 "Reserved" 10 "Reserved" 11 "Reserved" 12 "Reserved" 13 "Reserved" 14 "Reserved" 15 "Reserved" ;
VAL_ 2273435649 HDP_OptInfoSta 0 "HDP option not applied" 1 "HDP option applied" 2 "Reserved" 3 "Reserved" ;
VAL_ 2273435649 HDA_LFA_SymSta 0 "Off" 1 "Gray" 2 "Green" 3 "White blink" ;
VAL_ 2273435649 HDA_LFA_WrnSnd 0 "Off" 1 "Additional Warning Sound" 2 "Reserved" 3 "Error indicator" ;
VAL_ 2273435649 HDA_InfoPUDis1 0 "No Pop-up" 1 "System Automatic off (LFA)" 2 "System Automatic off (HDA)" 3 "Reserved" 4 "Reserved" 5 "Reserved" 6 "Not Used" 7 "Error Indicator" ;
VAL_ 2273435649 HDA_TDMRMDclReq 0 "Not automatically deactivated state of LFA (default)" 1 "Automatically deactivated state of LFA" 2 "Reserved" 3 "Reserved" ;
VAL_ 2273435649 HDP_ActvSta 0 "Not Active" 1 "Active" 2 "Reserved" 3 "Reserved" ;
VAL_ 2273435649 HDP_SysSta 0 "OFF" 1 "Standby" 2 "DDT" 3 "TD" 4 "MRM" 5 "EM" 6 "Reserved" 15 "Reserved" ;
VAL_ 2273435649 HDP_FailureMode 0 "Normal" 1 "Blockage" 2 "Failure" ;
VAL_ 2273435650 HDP_ObstacleDstVal 0 "0x0x0~0x5DC:Distance" 1500 "0x0x0~0x5DC:Distance" 1501 "0x5DD~0x7FD:Reserved" 2045 "0x5DD~0x7FD:Reserved" 2046 "Default" 2047 "Error" ;
VAL_ 2273435650 HDP_ObstacleLatPosVal 0 "0x0x0~0x1FD:Position Value" 509 "0x0x0~0x1FD:Position Value" 510 "Default" 511 "Error" ;
VAL_ 2273435650 HDP_InfoPUDis 0 "None" 1 "HDP Active" 2 "HDP TD Lv1" 3 "HDP TD Lv2" 4 "HDP MRM" 5 "HDP EM" 6 "HDP Automatic system off (ÀÚµ¿ ÇØÁ¦)" 7 "HDP Driver availability warning (¿îÀüÀÚ »óÅÂ °æ°í)" 8 "HDP Unable to start warning (È°¼ºÈ­ ºÒ°¡)" 9 "HDP guides user to change lane (°æ·Î º¯°æ À¯µµ ¾È³»)" 10 "Reserved" 11 "Reserved" 12 "Reserved" 13 "Reserved" 14 "Reserved" 15 "Reserved" ;
VAL_ 2273435650 HDP_WrngTypPUDis 0 "Reserved" 1 "Reserved" 2 "Reserved" 3 "Reserved" 4 "Reserved" 5 "Reserved" 6 "Reserved" 7 "Reserved" 8 "Reserved" 9 "Reserved" 10 "Reserved" 11 "Reserved" 12 "Reserved" 13 "Reserved" 14 "Reserved" 15 "Reserved" 16 "Reserved" 17 "Reserved" 18 "Reserved" 19 "Reserved" 20 "Reserved" 21 "Reserved" 22 "Reserved" 23 "Reserved" 24 "Reserved" 25 "Reserved" 26 "Reserved" 27 "Reserved" 28 "Reserved" 29 "Reserved" 30 "Reserved" 31 "Reserved" ;
VAL_ 2273435650 HDP_HapticWarnReq 0 "No Warn" 1 "Request Haptic Warn - Level1" 2 "Request Haptic Warn - Level2" 3 "Reserved" ;
VAL_ 2273435650 HDP_ActvStaDis 0 "Not Active" 1 "Active" 2 "Reserved" 3 "Reserved" 4 "Reserved" 5 "Reserved" 6 "Reserved" 7 "Invalid" ;
VAL_ 2273435650 HDP_OpStaDisp 0 "None" 1 "Standby" 2 "Ready" 3 "Active(DDT)" 4 "Active(TD)" 5 "Active(MRM)" 6 "Active(EM)" 7 "Reserved" 8 "Reserved" 9 "Reserved" 10 "Reserved" 11 "Reserved" 12 "Reserved" 13 "Reserved" 14 "Reserved" 15 "Invalid" ;
VAL_ 2273435650 HDP_ObstSta 0 "No in-path obstacle detected" 1 "In-path obstacle detected (uncontrollable)" 2 "In-path obstacle detected (controllable:longitudinal)" 3 "Reserved" 4 "Reserved" 5 "Reserved" 6 "Reserved" 7 "Reserved" ;
VAL_ 2273435650 HDP_SysFlrDisp 0 "No HDP failure pop-up" 1 "Display HDP failure pop-up" 2 "Reserved" 3 "Reserved" ;
VAL_ 2273435650 HDP_InhbtOffDispSta 0 "None" 1 "Inhibit FCA off in HDP" 2 "Inhibit DrivingSafety off in HDP" 3 "Reserved" 4 "Reserved" 5 "Reserved" 6 "Reserved" 7 "Reserved" ;
VAL_ 2273435650 HDP_CtRoadSrfcDistVal 0 "0x0x0~0x5DC:value (*0.1m)" 1500 "0x0x0~0x5DC:value (*0.1m)" 1501 "0x5DD~0x7FD:Reserved" 2045 "0x5DD~0x7FD:Reserved" 2046 "Default (Not Display)" 2047 "Invalid" ;
VAL_ 2273435650 ADAS_DRV_UpDateInfo 0 "old" 1 "new" ;
VAL_ 2244046849 PCA_RrEquipSta 0 "Default" 1 "Off" 2 "Warning" 3 "Assist" 4 "Reserved" 5 "Reserved" 6 "Reserved" 7 "Invalid" ;
VAL_ 2244046849 PCA_SysFlrSta 0 "Off (No Display)" 1 "Reserved" 2 "Camera Blockage" 3 "Ultrasonic sensor Blockage" 4 "PCA Failure" 5 "Reserved" 6 "Reserved" 7 "Error Indicator" ;
VAL_ 2244046849 PCA_RrWrngLvlSta 0 "Normal" 1 "Ready" 2 "Warning" 3 "Assist" 4 "Assist Ended" 5 "Brake Hold" 6 "Reserved" 7 "Invalid" ;
VAL_ 2244046849 PCA_ModDis 0 "No Warning" 1 "PCA-R Off" 2 "PCA-R On" 3 "PCA-R Off, PCA-F/S Off" 4 "PCA-R On, PCA-F/S Off" 5 "PCA-R On, PCA-F/S On" 6 "Reserved" 7 "Invalid" ;
VAL_ 2244046849 PCA_WrngSndCtSta 0 "Normal" 1 "Warning" 2 "Reserved" 3 "Invalid" ;
VAL_ 2244046849 PCA_WrngSndLtSta 0 "Normal" 1 "Warning" 2 "Reserved" 3 "Invalid" ;
VAL_ 2244046849 PCA_WrngSndRtSta 0 "Normal" 1 "Warning" 2 "Reserved" 3 "Invalid" ;
VAL_ 2244046849 PCA_HptReq 0 "Haptic Off" 1 "Haptic On" 2 "Reserved" 3 "Invalid" ;
VAL_ 2244046849 PCA_BrkReq 0 "PCA Brake off" 1 "PCA Brake on" 2 "PCA Brake on (hold)" 3 "Error indicator" ;
VAL_ 2244046849 PCA_EpbReq 0 "Apply EPB" 1 "Stand by" 2 "Reserved" 3 "Invalid" ;
VAL_ 2244046849 PU_F_Group7_DrvrAsstFlr10Sta 0 "Not Display" 1 "Failure" 2 "Camera Blockage" 3 "Ultrasonic sensor Blockage" 4 "Reserved" 5 "Reserved" 6 "Reserved" 7 "Error Indicator" ;
VAL_ 2244046849 ADAS_PRK_PDW_SysFlrSta 0 "No Display" 1 "Unable by Ultrasonic" 2 "PDW Failure" 3 "Error Indicator" ;
VAL_ 2244046850 ADAS_PRK_PDW_SwIndOnReq 0 "Indicator Off" 1 "Indicator On" 2 "Not Used" 3 "Error Indicator" ;
VAL_ 2244046850 PCA_RrEquipChkSta 0 "Default" 1 "Off" 2 "On" 3 "Invalid" ;
VAL_ 2244046850 PCA_FrWrngLvlSta 0 "Normal" 1 "Ready" 2 "Warning" 3 "Assist" 4 "Assist Ended" 5 "Reserved" 6 "Reserved" 7 "Invalid" ;
VAL_ 2244046850 PCA_LtWrngLvlSta 0 "Normal" 1 "Ready" 2 "Warning" 3 "Assist" 4 "Assist Ended" 5 "Reserved" 6 "Reserved" 7 "Invalid" ;
VAL_ 2244046850 ADAS_PRK_PDW_OptTyp 0 "None" 1 "PDW-R" 2 "PDW-FR" 3 "PDW-FSR" 4 "PDW-R (w/ 1st Corner Warning)" 5 "PDW-FR (w/ 1st Corner Warning)" 6 "Not Used" 7 "Error Indicator" ;
VAL_ 2244046850 PCA_RtWrngLvlSta 0 "Normal" 1 "Ready" 2 "Warning" 3 "Assist" 4 "Assist Ended" 5 "Reserved" 6 "Reserved" 7 "Invalid" ;
VAL_ 2244046850 PCA_RrFlrDis 0 "Normal" 1 "Unvailable by PCA-R" 2 "Reserved" 3 "Invalid" ;
VAL_ 2244046850 PCA_FrFlrDis 0 "Normal" 1 "Unvailable by PCA-F" 2 "Reserved" 3 "Invalid" ;
VAL_ 2244046850 PCA_LtFlrDis 0 "Normal" 1 "Unvailable by PCA-S" 2 "Reserved" 3 "Invalid" ;
VAL_ 2244046850 PCA_RtFlrDis 0 "Normal" 1 "Unvailable by PCA-S" 2 "Reserved" 3 "Invalid" ;
VAL_ 2244046850 PCA_FrBndryLn 0 "Off (No Display)" 1 "Ready" 2 "Assist" 3 "Error Indicator" ;
VAL_ 2244046850 PCA_RrBndryLn 0 "Off (No Display)" 1 "Ready" 2 "Assist" 3 "Error Indicator" ;
VAL_ 2244046850 PCA_LtBndryLn 0 "Off (No Display)" 1 "Ready" 2 "Assist" 3 "Error Indicator" ;
VAL_ 2244046850 PCA_RtBndryLn 0 "Off (No Display)" 1 "Ready" 2 "Assist" 3 "Error Indicator" ;
VAL_ 2244046850 PCA_WrngPhrs 0 "Off (No Display)" 1 "Warning" 2 "Assist" 3 "Assist Ended" 4 "Brake Hold" 5 "Reserved" 6 "Reserved" 7 "Error Indicator" ;
VAL_ 2244046850 ADAS_PRK_PDW_AutoOn_USM 0 "Default" 1 "Function Off" 2 "Function On" 3 "Invalid" ;
VAL_ 2244046850 PCA_FrSdEquipChkSta 0 "Default" 1 "Off" 2 "On" 3 "Invalid" ;
VAL_ 1133 APSU_AstStEsyAcsUSMSta 0 "Default Value" 1 "Off (Disable)" 2 "50mmOn (Enable)" 3 "75mmOn (Enable)" 4 "Reserved" 5 "Reserved" 6 "Reserved" 7 "Invalid" ;
VAL_ 1133 APSU_AstReturnModeSta 0 "Default" 1 "Off" 2 "Stop" 3 "Moving" 4 "Finish" 5 "Invalid" ;
VAL_ 1133 APSU_CntryConfigTyp 0 "Dom" 1 "Na" 2 "Eu" 3 "Aus" 4 "China" 5 "Gen,Mes" 6 "India" 7 "RESERVED" 8 "RESERVED" 9 "RESERVED" 10 "RESERVED" 11 "RESERVED" 12 "RESERVED" 13 "RESERVED" 15 "Error Indicator" ;
VAL_ 1133 APSU_AutoHtrCtrlUSMSta 0 "Default" 1 "Off" 2 "On" 3 "Invalid" ;
VAL_ 1133 APSU_HtBlcUSMSta 0 "Default" 1 "Normal" 2 "Back 1" 3 "Back 2" 4 "Back 3" 5 "Cush 1" 6 "Cush 2" 7 "Cush 3" 8 "Reserved" 9 "Reserved" 10 "Reserved" 11 "Reserved" 12 "Reserved" 13 "Reserved" 14 "Reserved" 15 "Invalid" ;
VAL_ 1133 APSU_AstAntPncMod 0 "Default" 1 "Off" 2 "On" 3 "Invalid" ;
VAL_ 1133 APSU_AstOneTchFldModSta 0 "Default" 1 "Off" 2 "Reclining FWD" 3 "Reclining BWD" 4 "Folding Mode" 5 "Unfolding Mode" 6 "Reserved" 7 "Invalid" ;
VAL_ 1133 APSU_AstOneTchOperSta 0 "Default" 1 "Off" 2 "Ready" 3 "Move" 4 "Finished" 5 "Reserved" 6 "Reserved" 7 "Invalid" ;
VAL_ 1133 APSU_AstRelaxModeSta 0 "Default" 1 "Off" 2 "Stop" 3 "Moving" 4 "Finish" 5 "Invalid" ;
VAL_ 527 ATS_DrvStRseFwdBtn 0 "Default" 1 "Off" 2 "On" 3 "Reserved" ;
VAL_ 527 ATS_DrvStRseBwdBtn 0 "Default" 1 "Off" 2 "On" 3 "Reserved" ;
VAL_ 527 ATS_RRRestModBtn 0 "Default" 1 "Off" 2 "On" 3 "Reserved" ;
VAL_ 527 ATS_RRResetModBtn 0 "Default" 1 "Off" 2 "On" 3 "Reserved" ;
VAL_ 527 ATS_RRAvWtcModBtn 0 "Default" 1 "Off" 2 "On" 3 "Reserved" ;
VAL_ 527 ATS_RRReadingModBtn 0 "Default" 1 "Off" 2 "On" 3 "Reserved" ;
VAL_ 527 ATS_RLRestModBtn 0 "Default" 1 "Off" 2 "On" 3 "Reserved" ;
VAL_ 527 ATS_RLResetModBtn 0 "Default" 1 "Off" 2 "On" 3 "Reserved" ;
VAL_ 543 ATS_AstStSldFwdBtn 0 "Default" 1 "Off" 2 "On" 3 "Reserved" ;
VAL_ 543 ATS_AstStSldBwdBtn 0 "Default" 1 "Off" 2 "On" 3 "Reserved" ;
VAL_ 543 ATS_AstStRclFwdBtn 0 "Default" 1 "Off" 2 "On" 3 "Reserved" ;
VAL_ 543 ATS_AstStRclBwdBtn 0 "Default" 1 "Off" 2 "On" 3 "Reserved" ;
VAL_ 543 ATS_AstStHgtUpBtn 0 "Default" 1 "Off" 2 "On" 3 "Reserved" ;
VAL_ 543 ATS_AstStHgtDnBtn 0 "Default" 1 "Off" 2 "On" 3 "Reserved" ;
VAL_ 543 ATS_AstStHRestUpBtn 0 "Default" 1 "Off" 2 "On" 3 "Reserved" ;
VAL_ 543 ATS_AstStHRestDnBtn 0 "Default" 1 "Off" 2 "On" 3 "Reserved" ;
VAL_ 543 ATS_AstStHRestFwdBtn 0 "Default" 1 "Off" 2 "On" 3 "Reserved" ;
VAL_ 543 ATS_AstStHRestBwdBtn 0 "Default" 1 "Off" 2 "On" 3 "Reserved" ;
VAL_ 543 ATS_AstStHRestFldBtn 0 "Default" 1 "Off" 2 "On" 3 "Reserved" ;
VAL_ 543 ATS_AstStHRestUnFldBtn 0 "Default" 1 "Off" 2 "On" 3 "Reserved" ;
VAL_ 543 ATS_AstStRseFwdBtn 0 "Default" 1 "Off" 2 "On" 3 "Reserved" ;
VAL_ 543 ATS_AstStRseBwdBtn 0 "Default" 1 "Off" 2 "On" 3 "Reserved" ;
VAL_ 543 ATS_AstStFRestFldBtn 0 "Default" 1 "Off" 2 "On" 3 "Reserved" ;
VAL_ 543 ATS_AstStFRestUnFldBtn 0 "Default" 1 "Off" 2 "On" 3 "Reserved" ;
VAL_ 543 ATS_AstTltUpBtn 0 "Default" 1 "Off" 2 "On" 3 "Reserved" ;
VAL_ 543 ATS_AstTltDnBtn 0 "Default" 1 "Off" 2 "On" 3 "Reserved" ;
VAL_ 1141 Ast_SHVU_SeatOptSta 0 "Init" 1 "Heater only 2step" 2 "Heater only 3step" 3 "Vent only 2step" 4 "Vent only 3step" 5 "Heater and Vent 2step" 6 "Heater and Vent 3step" 7 "Invalid" ;
VAL_ 1141 Ast_SHVU_HtSwHiIndSta 0 "Off(Initial Value)" 1 "On" 2 "Not Used" 3 "Error Indicator" ;
VAL_ 1141 Ast_SHVU_HtSwMidIndSta 0 "Off(Initial Value)" 1 "On" 2 "Not Used" 3 "Error Indicator" ;
VAL_ 1141 Ast_SHVU_HtSwLowIndSta 0 "Off(Initial Value)" 1 "On" 2 "Not Used" 3 "Error Indicator" ;
VAL_ 1141 Ast_SHVU_VntSwHiIndSta 0 "Off(Initial Value)" 1 "On" 2 "Not Used" 3 "Error Indicator" ;
VAL_ 1141 Ast_SHVU_VntSwMidIndSta 0 "Off(Initial Value)" 1 "On" 2 "Not Used" 3 "Error Indicator" ;
VAL_ 1141 Ast_SHVU_VntSwLowIndSta 0 "Off(Initial Value)" 1 "On" 2 "Not Used" 3 "Error Indicator" ;
VAL_ 1141 Ast_SHVU_HtBlcUSMSta 0 "Default" 1 "Normal" 2 "Back 1" 3 "Back 2" 4 "Back 3" 5 "Cush 1" 6 "Cush 2" 7 "Cush 3" 8 "Reserved" 9 "Reserved" 10 "Reserved" 11 "Reserved" 12 "Reserved" 13 "Reserved" 14 "Reserved" 15 "Invalid" ;
VAL_ 1141 Ast_SHVU_SeatHtOperSta 0 "Init" 1 "Unused" 2 "Heater & Vent OFF" 3 "Vent Low" 4 "Vent Mid" 5 "Vent High" 6 "Heater Low" 7 "Heater Mid" 8 "Heater High" 9 "Unused" 10 "Unused" 11 "Unused" 12 "Unused" 13 "Unused" 14 "Unused" 15 "Invalid" ;
VAL_ 1141 Ast_SHVU_HtSwHiIndSta_RHD 0 "Off(Initial Value)" 1 "On" 2 "Not Used" 3 "Error Indicator" ;
VAL_ 1141 Ast_SHVU_HtSwMidIndSta_RHD 0 "Off(Initial Value)" 1 "On" 2 "Not Used" 3 "Error Indicator" ;
VAL_ 1141 Ast_SHVU_HtSwLowIndSta_RHD 0 "Off(Initial Value)" 1 "On" 2 "Not Used" 3 "Error Indicator" ;
VAL_ 1141 Ast_SHVU_VntSwHiIndSta_RHD 0 "Off(Initial Value)" 1 "On" 2 "Not Used" 3 "Error Indicator" ;
VAL_ 1141 Ast_SHVU_VntSwMidIndSta_RHD 0 "Off(Initial Value)" 1 "On" 2 "Not Used" 3 "Error Indicator" ;
VAL_ 1141 Ast_SHVU_VntSwLowIndSta_RHD 0 "Off(Initial Value)" 1 "On" 2 "Not Used" 3 "Error Indicator" ;
VAL_ 1124 Window_DrvrSdWdwActSta 0 "No Action" 1 "Manual Down" 2 "Manual Up" 3 "RLY Stuck/FET Error" 4 "Motor Stop Error" 5 "Auto Down" 6 "Auto Up" 7 "Reverse" 8 "Reserved" 9 "Reserved" 10 "Reserved" 11 "Reserved" 12 "Reserved" 13 "Reserved" 14 "Reserved" 15 "Invalid" ;
VAL_ 1124 Window_AsstSdWdwActSta 0 "No Action" 1 "Manual Down" 2 "Manual Up" 3 "RLY Stuck/FET Error" 4 "Motor Stop Error" 5 "Auto Down" 6 "Auto Up" 7 "Reverse" 8 "Reserved" 9 "Reserved" 10 "Reserved" 11 "Reserved" 12 "Reserved" 13 "Reserved" 14 "Reserved" 15 "Invalid" ;
VAL_ 1124 Window_RrLftWdwActSta 0 "No Action" 1 "Manual Down" 2 "Manual Up" 3 "RLY Stuck/FET Error" 4 "Motor Stop Error" 5 "Auto Down" 6 "Auto Up" 7 "Reverse" 8 "Reserved" 9 "Reserved" 10 "Reserved" 11 "Reserved" 12 "Reserved" 13 "Reserved" 14 "Reserved" 15 "Invalid" ;
VAL_ 1124 Window_RrRtWdwActSta 0 "No Action" 1 "Manual Down" 2 "Manual Up" 3 "RLY Stuck/FET Error" 4 "Motor Stop Error" 5 "Auto Down" 6 "Auto Up" 7 "Reverse" 8 "Reserved" 9 "Reserved" 10 "Reserved" 11 "Reserved" 12 "Reserved" 13 "Reserved" 14 "Reserved" 15 "Invalid" ;
VAL_ 1124 Window_DrvrSdWdwDetailOpnSta 0 "Full Close" 1 "1~30% Open" 2 "31~99% Open" 3 "Full Open" 4 "Reserved" 5 "Reserved" 6 "Reserved" 7 "Invalid" ;
VAL_ 1124 Window_AsstSdWdwDetailOpnSta 0 "Full Close" 1 "1~30% Open" 2 "31~99% Open" 3 "Full Open" 4 "Reserved" 5 "Reserved" 6 "Reserved" 7 "Invalid" ;
VAL_ 1124 Window_DrvrSdWdwErrAntPinch 0 "Calibrated" 1 "De-Calibrated" 2 "Reserved" 3 "Invalid" ;
VAL_ 1124 Window_RrLftWdwDetailOpnSta 0 "Full Close" 1 "1~30% Open" 2 "31~99% Open" 3 "Full Open" 4 "Reserved" 5 "Reserved" 6 "Reserved" 7 "Invalid" ;
VAL_ 1124 Window_RrRtWdwDetailOpnSta 0 "Full Close" 1 "1~30% Open" 2 "31~99% Open" 3 "Full Open" 4 "Reserved" 5 "Reserved" 6 "Reserved" 7 "Invalid" ;
VAL_ 1124 Window_AsstSdWdwErrAntPinch 0 "Calibrated" 1 "De-Calibrated" 2 "Reserved" 3 "Invalid" ;
VAL_ 1124 Window_RrLftWdwErrAntPinch 0 "Calibrated" 1 "De-Calibrated" 2 "Reserved" 3 "Invalid" ;
VAL_ 1124 Window_RrRtWdwErrAntPinch 0 "Calibrated" 1 "De-Calibrated" 2 "Reserved" 3 "Invalid" ;
VAL_ 1124 SunRoof_RrBlindPosSta 0 "BLIND_HALF_OPEN" 1 "BLIND_LESS_THEN_HALF_OPEN" 2 "BLIND_ANTIPINCH_LESS_THAN_HALF_OPEN" 3 "BLIND_FULLY_CLOSE" 4 "BLIND_ANTIPINCH_MORE_THAN_HALF_OPEN" 5 "BLIND_MORE_THAN_HALF_OPEN" 6 "BLIND_FULLY_OPEN" 7 "BLIND_UNINITIALIZED" 8 "Reserved" 9 "Reserved" 10 "Reserved" 11 "Reserved" 12 "Reserved" 13 "Reserved" 14 "Reserved" 15 "invalid" ;
VAL_ 1130 DLBCU_LumbarUpDis 0 "default" 1 "off" 2 "on" 3 "invalid" ;
VAL_ 1130 DLBCU_LumbarMidDis 0 "default" 1 "off" 2 "on" 3 "invalid" ;
VAL_ 1130 DLBCU_LumbarLowDis 0 "default" 1 "off" 2 "on" 3 "invalid" ;
VAL_ 1130 DLBCU_LumbarDefDis 0 "default" 1 "off" 2 "on" 3 "invalid" ;
VAL_ 1131 DLBCU_BolsterInfDis 0 "default" 1 "off" 2 "on" 3 "invalid" ;
VAL_ 1131 DLBCU_BolsterDefDis 0 "default" 1 "off" 2 "on" 3 "invalid" ;
VAL_ 1127 DPSS_Crc1Val 0 "0x0x0~0xFF:CRCValue" 255 "0x0x0~0xFF:CRCValue" ;
VAL_ 1127 DPSS_AlvCnt1Val 0 "AlvCntValue" 1 "AlvCntValue" 2 "AlvCntValue" 3 "AlvCntValue" 4 "AlvCntValue" 5 "AlvCntValue" 6 "AlvCntValue" 7 "AlvCntValue" 8 "AlvCntValue" 9 "AlvCntValue" 10 "AlvCntValue" 11 "AlvCntValue" 12 "AlvCntValue" 13 "AlvCntValue" 14 "AlvCntValue" 15 "AlvCntValue" ;
VAL_ 1127 DPSS_StExtFwdMvBtn 0 "Default" 1 "Off" 2 "On" 3 "Invalid" ;
VAL_ 1127 DPSS_StExtBwdMvBtn 0 "Default" 1 "Off" 2 "On" 3 "Invaild" ;
VAL_ 1127 DPSS_StSldFwdMvBtn 0 "Default" 1 "Off" 2 "On" 3 "Invalid" ;
VAL_ 1127 DPSS_StSldBwdMvBtn 0 "Default" 1 "Off" 2 "On" 3 "Invalid" ;
VAL_ 1127 DPSS_StRclFwdMvBtn 0 "Default" 1 "Off" 2 "On" 3 "Invaild" ;
VAL_ 1127 DPSS_StRclBwdMvBtn 0 "Default" 1 "Off" 2 "On" 3 "Invalid" ;
VAL_ 1127 DPSS_StHgtUpMvBtn 0 "Default" 1 "Off" 2 "On" 3 "Invaild" ;
VAL_ 1127 DPSS_StHgtDnMvBtn 0 "Default" 1 "Off" 2 "On" 3 "Invalid" ;
VAL_ 1127 DPSS_StTltUpMvBtn 0 "Default" 1 "Off" 2 "On" 3 "Invalid" ;
VAL_ 1127 DPSS_StTltDnMvBtn 0 "Default" 1 "Off" 2 "On" 3 "Invalid" ;
VAL_ 1127 DPSS_StHRestUpMvBtn 0 "Default" 1 "Off" 2 "On" 3 "Invalid" ;
VAL_ 1127 DPSS_StHRestDnMvBtn 0 "Default" 1 "Off" 2 "On" 3 "Invalid" ;
VAL_ 1127 DPSS_StHRestFwdMvBtn 0 "Default" 1 "Off" 2 "On" 3 "Invalid" ;
VAL_ 1127 DPSS_StHRestBwdMvBtn 0 "Default" 1 "Off" 2 "On" 3 "Invalid" ;
VAL_ 1127 DPSS_StLegUpMvBtn 0 "Default" 1 "Off" 2 "On" 3 "Invalid" ;
VAL_ 1127 DPSS_StLegDnMvBtn 0 "Default" 1 "Off" 2 "On" 3 "Invalid" ;
VAL_ 1127 DPSS_StRlxModeBtn 0 "Default" 1 "Off" 2 "On" 3 "Invalid" ;
VAL_ 1127 DPSS_StRlxReturnBtn 0 "Default" 1 "Off" 2 "On" 3 "Invalid" ;
VAL_ 1127 DPSS_StRlxTltUpMvBtn 0 "Default" 1 "Off" 2 "On" 3 "Invalid" ;
VAL_ 1127 DPSS_StRlxTltDnMvBtn 0 "Default" 1 "Off" 2 "On" 3 "Invalid" ;
VAL_ 1128 DPSS_LumbarUpSw 0 "Default" 1 "Off" 2 "On" 3 "Invalid" ;
VAL_ 1128 DPSS_LumbarMidSw 0 "Default" 1 "Off" 2 "On" 3 "Invalid" ;
VAL_ 1128 DPSS_LumbarLowSw 0 "Default" 1 "Off" 2 "On" 3 "Invalid" ;
VAL_ 1128 DPSS_LumbarDefSw 0 "Default" 1 "Off" 2 "On" 3 "Invalid" ;
VAL_ 1128 DPSS_BolsterInfSw 0 "Default" 1 "Off" 2 "On" 3 "Invalid" ;
VAL_ 1128 DPSS_BolsterDefSw 0 "Default" 1 "Off" 2 "On" 3 "Invalid" ;
VAL_ 1128 DPSS_ActiveSw 0 "Default" 1 "Off" 2 "On" 3 "Invalid" ;
VAL_ 1128 DPSS_CushInfSw 0 "Default" 1 "Off" 2 "On" 3 "Invaild" ;
VAL_ 1128 DPSS_CushDefSw 0 "Default" 1 "Off" 2 "On" 3 "Invalid" ;
VAL_ 1129 DPSS_SldTch 0 "Default" 1 "Off" 2 "On" 3 "Invalid" ;
VAL_ 1129 DPSS_RclTch 0 "Default" 1 "Off" 2 "On" 3 "Invalid" ;
VAL_ 1129 DPSS_ExtTch 0 "Default" 1 "Off" 2 "On" 3 "Invalid" ;
VAL_ 1129 DPSS_LmbrTch 0 "Default" 1 "Off" 2 "On" 3 "Invalid" ;
VAL_ 1129 DPSS_CushOnOffTch 0 "Default" 1 "Off" 2 "On(Off State)" 3 "On(Mode1 State)" 4 "On(Mode2 State)" 5 "On(Mode3 State)" 6 "Reserved" 7 "Invalid" ;
VAL_ 1129 DPSS_HRestTch 0 "Default" 1 "Off" 2 "On" 3 "Invalid" ;
VAL_ 1129 DPSS_RelaxTch 0 "Default" 1 "Off" 2 "On" 3 "Invalid" ;
VAL_ 1129 DPSS_ThighTch 0 "Default" 1 "Off" 2 "On" 3 "Invalid" ;
VAL_ 1129 DPSS_ExtThighTch 0 "Default" 1 "Off" 2 "On" 3 "Invalid" ;
VAL_ 1129 DPSS_LmbrBolsterTch 0 "Default" 1 "Off" 2 "On" 3 "Invalid" ;
VAL_ 614 EMCU_Crc1Val 0 "0x0x0~0xFF:CRCValue" 255 "0x0x0~0xFF:CRCValue" ;
VAL_ 614 EMCU_AlvCnt1Val 0 "AlvCntValue" 1 "AlvCntValue" 2 "AlvCntValue" 3 "AlvCntValue" 4 "AlvCntValue" 5 "AlvCntValue" 6 "AlvCntValue" 7 "AlvCntValue" 8 "AlvCntValue" 9 "AlvCntValue" 10 "AlvCntValue" 11 "AlvCntValue" 12 "AlvCntValue" 13 "AlvCntValue" 14 "AlvCntValue" 15 "AlvCntValue" ;
VAL_ 614 EMCU_LHActSta 0 "OFF" 1 "ON" 2 "RESERVED" 3 "Error indicator" ;
VAL_ 614 EMCU_RHActSta 0 "OFF" 1 "ON" 2 "RESERVED" 3 "Error indicator" ;
VAL_ 614 EMCU_DeltaSpdVal 0 "0x0x000~0xFFE:real values" 4094 "0x0x000~0xFFE:real values" 4095 "Error indicator" ;
VAL_ 614 EMCU_System_Sta 0 "Normal" 1 "RESERVED" 2 "RESERVED" 3 "Error indicator" ;
VAL_ 2214658049 EMS_Crc2Val 65535 "Signal Invalid (Message with unused CRC. CRC signal is transmitted fixed value)" ;
VAL_ 2214658049 EMS_AlvCnt2Val 255 "Signal Invalid (Message with unused Alive counter. Alive counter signal is transmitted fixed value)" ;
VAL_ 2214658049 ENG_BrkSwSta 0 "Brake switch is not pressed (OFF)" 1 "Brake switch is pressed (ON)" 2 "EMS does not support this function." 3 "Brake switch failure" ;
VAL_ 2214658049 ENG_EngClntTempVal 255 "Error indicator" ;
VAL_ 2214658049 ENG_MafCrctVal 128 "Error indicator" ;
VAL_ 2214658049 ENG_BattDscnctSta 0 "no battery disconnection detected" 1 "battery disconnection detected and failure memory erased" 2 "Not used" 3 "Error indicator" ;
VAL_ 2214658049 OBD_MilConfgVal 0 "no MIL, Failure Memory Management OBD-I" 1 "MIL Treatment OBD-I, Failure Memory Management OBD-I" 2 "MIL Treatment OBD-II, Exception" 3 "MIL Treatment OBD-II, Failure Memory Management OBD-II" 4 "MIL Treatment E-OBD, Failure Memory Management E-OBD" 5 "MIL Treatment K-OBD, Failure Memory Management K-OBD" ;
VAL_ 2214658049 ENG_EngSta 0 "Engine Stop" 1 "Cranking" 2 "Stalled" 3 "Running" 4 "Reserved" 5 "Reserved" 6 "Reserved" 7 "Fault" ;
VAL_ 2214658050 ENG_Ack4EngStpSta 0 "No acknowledgement" 1 "Acknowledgement engine stopped" 2 "Not used" 3 "Error indicator" ;
VAL_ 2214658050 ENG_AccDrvAlertDisp 0 "Default" 1 "Auto cruise Disengaged" 2 "No Auto cruise Engaged" 3 "Error indicator" ;
VAL_ 2214658050 DSL_GlowCtrlReq 0 "Glow plug off request" 1 "Glow plug on request" 2 "System Error" 3 "Reserved" ;
VAL_ 2214658050 ENG_GlowLmpSta 0 "Lamp Off" 1 "Lamp On" 2 "Not used" 3 "Error indicator" ;
VAL_ 2214658050 ENG_ThrPosVal 32 "Idle (port value is learnt)" 245 "Throttle perpendicular" 255 "Throttle defective" ;
VAL_ 2214658050 ENG_OverDrvOffReq 0 "Normal operation" 1 "Over drive off request to TCU by the cruise control function" 2 "Not used" 3 "Error indicator" ;
VAL_ 2214658050 ENG_AccelPdlVal 0 "Accelerator Pedal not activated" 1022 "Accelerator Pedal fully activated" 1023 "Accelerator Pedal is defective (fail state) or Non-ETC system (APS is not installed), Error indicator" ;
VAL_ 2214658050 ENG_AccActSta 0 "Auto cruise control is not active" 1 "Auto cruise control is active" 2 "Not used" 3 "Error indicator" ;
VAL_ 2214658050 ACC_CrsMainSwLmpSta 0 "Cruise MAIN switch indication lamp turn OFF" 1 "Cruise MAIN switch indication lamp turn ON" 2 "Not used" 3 "Error indicator" ;
VAL_ 2214658050 ACC_CrsSetSwLmpSta 0 "Cruise SET switch indication lamp turn OFF" 1 "Cruise SET switch indication lamp turn ON" 2 "Not used" 3 "Error indicator" ;
VAL_ 2214658050 ENG_LV_FUP_ENA_THD 0 "The pressure is too low to start engine" 1 "The pressure is enough high to start engine" ;
VAL_ 2214658050 ENG_SoakTimeErrSta 0 "No Failure detected" 1 "Failure detected" 2 "Not used" 3 "Error indicator" ;
VAL_ 2214658050 ENG_CltchOpSta 0 "Clutch is not operating" 1 "Clutch is operating" 2 "Not used" 3 "Error indicator" ;
VAL_ 2214658050 EMS_BrkReq_Slope 0 "No Request" 1 "Brake Request" ;
VAL_ 2214658051 ENG_AppAccelPdlSta 0 "Accelerator pedal not pressed" 1 "Accelerator pedal pressed" 2 "Reserved" 3 "Accelerator pedal position sensor failure" ;
VAL_ 2214658051 ENG_BrkCtrlReq 0 "Brake control request is not active" 1 "Brake control request is active" 2 "Not used" 3 "Error indicator" ;
VAL_ 2214658051 ACC_DnShftCtrlReq 0 "Downshift control request is not active" 1 "Downshift request to 1st gear" 2 "Downshift request to 2nd gear" 3 "Downshift request to 3rd gear" 4 "Downshift request to 4th gear" 5 "Downshift request to 5th gear" 6 "Downshift request to 6th gear" 7 "Downshift request to 7th gear" 8 "Downshift request to 8th gear" 9 "Reserved" 10 "Reserved" 11 "Reserved" 12 "Reserved" 13 "Reserved" 14 "Reserved" 15 "Error indicator" ;
VAL_ 2214658052 ENG_DclBrkCntrlReq 4095 "Error indicator" ;
VAL_ 2214658052 ENG_BstPrsrVal 4095 "Error indicator" ;
VAL_ 2214658052 ENG_EngOilTempVal 255 "Error indicator" ;
VAL_ 2214658052 ENG_DpfWrngSta 0 "DPF Normal State" 1 "DPF Warning State Level 1" 2 "DPF Warning State Level 2" 3 "Reserved" ;
VAL_ 2214658052 ENG_BattWrngLmpSta 0 "Battery Warning Lamp OFF" 1 "Battery Warning Lamp ON" 2 "Not used" 3 "Error indicator" ;
VAL_ 2214658052 ENG_OilPrsrWrngLmpSta 0 "Oil Pressure Warning Lamp OFF" 1 "Oil Pressure Warning Lamp ON" 2 "Not used" 3 "Error indicator" ;
VAL_ 2214658052 ENG_IsgInhbtLmpSta 0 "ISG Inhibit Lamp OFF" 1 "ISG Inhibit Lamp ON" 2 "Not used" 3 "Error indicator" ;
VAL_ 1616 MKBD_IllumiState 0 "Not received" 1 "Receive Completed" 2 "Reserved" 3 "Invalid" ;
VAL_ 1616 MKBD_SeatKeySet 0 "Off" 1 "On" 2 "Reserved" 3 "Invalid" ;
VAL_ 1027 Win_ElecChildLkSwOpt 0 "Off" 1 "On" 2 "Not Used" 3 "Error Indicator" ;
VAL_ 1027 Win_PwrWdwSwTyp 0 "Invalid" 1 "All Manual" 2 "Drv Auto Down" 3 "Drv Safety" 4 "Frt Safety" 5 "All Safety" 6 "Not Used" 7 "Error Indicator" ;
VAL_ 1027 Win_DrvIMSSwSta 0 "Off" 1 "1" 2 "2" 3 "3(Smart)" 4 "Set(Passenger Seat)" 5 "Not Used" 6 "Not Used" 7 "Error Indicator" ;
VAL_ 1027 Win_DrvPwrWdwSwSta 0 "Off" 1 "Manual Up" 2 "Manual Down" 3 "Auto Up" 4 "Auto Down" 5 "Stuck" 6 "Not Used" 7 "Error Indicator" ;
VAL_ 1027 Win_AsstPwrWdwSwSta 0 "Off" 1 "Manual Up" 2 "Manual Down" 3 "Auto Up" 4 "Auto Down" 5 "Stuck" 6 "Not Used" 7 "Error Indicator" ;
VAL_ 1027 Win_CtrlDrLkSwSta 0 "Off" 1 "On" 2 "Not Used" 3 "Error Indicator" ;
VAL_ 1027 Win_RrLftPwrWdwSwSta 0 "Off" 1 "Manual Up" 2 "Manual Down" 3 "Auto Up" 4 "Auto Down" 5 "Stuck" 6 "Not Used" 7 "Error Indicator" ;
VAL_ 1027 Win_RrRtPwrWdwSwSta 0 "Off" 1 "Manual Up" 2 "Manual Down" 3 "Auto Up" 4 "Auto Down" 5 "Stuck" 6 "Not Used" 7 "Error Indicator" ;
VAL_ 1027 Win_CtrlDrUnLkSwSta 0 "Off" 1 "On" 2 "Not Used" 3 "Error Indicator" ;
VAL_ 1027 Win_PwrWdwLkSwSta 0 "Off" 1 "On" 2 "Not Used" 3 "Error Indicator" ;
VAL_ 1027 Win_RrCrtSwSta 0 "Off" 1 "On" 2 "Not Used" 3 "Error Indicator" ;
